VERSION "ChassisFusionCANFD"

NS_ :

BS_:

BU_: ADD BCP BCS EPS FZCU SCU SWM VECU XCD

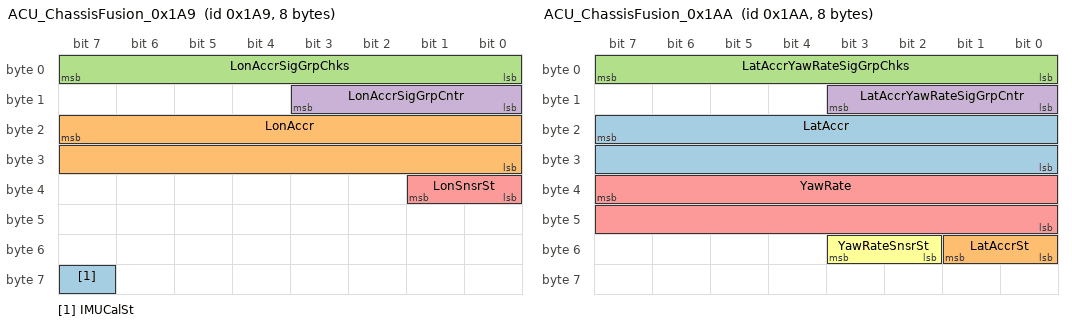
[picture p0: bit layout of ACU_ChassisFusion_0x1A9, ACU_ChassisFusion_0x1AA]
BO_ 425 ACU_ChassisFusion_0x1A9: 8 XCD
 SG_ IMUCalSt : 63|1@0+ (1,0) [0|1] ""  BCP,BCS,SCU
 SG_ LonAccr : 23|16@0+ (0.0002,-5) [-5|5] "g"  BCP,BCS,SCU
 SG_ LonAccrSigGrpChks : 7|8@0+ (1,0) [0|255] ""  BCP,BCS,SCU
 SG_ LonAccrSigGrpCntr : 11|4@0+ (1,0) [0|15] ""  BCP,BCS,SCU
 SG_ LonSnsrSt : 33|2@0+ (1,0) [0|3] ""  BCP,BCS,SCU

BO_ 426 ACU_ChassisFusion_0x1AA: 8 XCD
 SG_ LatAccr : 23|16@0+ (0.0002,-5) [-5|5] "g"  BCS,SCU
 SG_ LatAccrSt : 49|2@0+ (1,0) [0|3] ""  BCS,SCU
 SG_ LatAccrYawRateSigGrpChks : 7|8@0+ (1,0) [0|255] ""  BCS,SCU
 SG_ LatAccrYawRateSigGrpCntr : 11|4@0+ (1,0) [0|15] ""  BCS,SCU
 SG_ YawRate : 39|16@0+ (0.01,-300) [-300|300] "deg/s"  BCS,SCU
 SG_ YawRateSnsrSt : 51|2@0+ (1,0) [0|3] ""  BCS,SCU

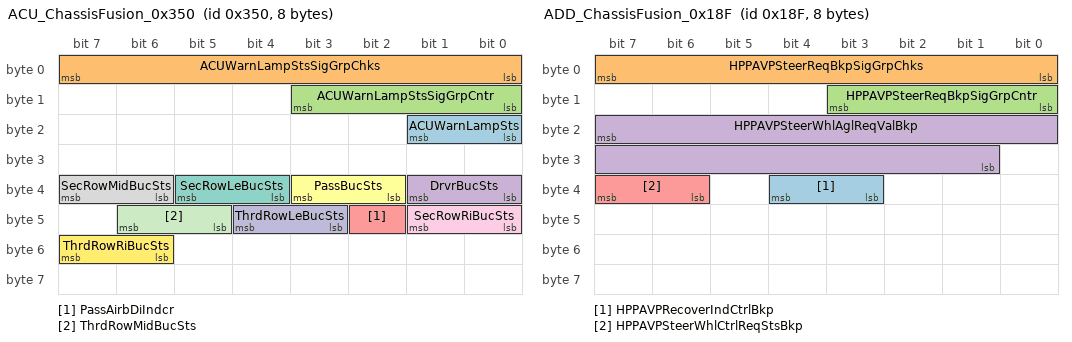
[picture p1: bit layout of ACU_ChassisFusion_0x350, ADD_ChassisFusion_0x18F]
BO_ 848 ACU_ChassisFusion_0x350: 8 XCD
 SG_ ACUWarnLampSts : 17|2@0+ (1,0) [0|3] "" Vector__XXX
 SG_ ACUWarnLampStsSigGrpChks : 7|8@0+ (1,0) [0|255] "" Vector__XXX
 SG_ ACUWarnLampStsSigGrpCntr : 11|4@0+ (1,0) [0|15] "" Vector__XXX
 SG_ DrvrBucSts : 33|2@0+ (1,0) [0|3] ""  SCU
 SG_ PassAirbDiIndcr : 42|1@0+ (1,0) [0|1] "" Vector__XXX
 SG_ PassBucSts : 35|2@0+ (1,0) [0|3] "" Vector__XXX
 SG_ SecRowLeBucSts : 37|2@0+ (1,0) [0|3] "" Vector__XXX
 SG_ SecRowMidBucSts : 39|2@0+ (1,0) [0|3] "" Vector__XXX
 SG_ SecRowRiBucSts : 41|2@0+ (1,0) [0|3] "" Vector__XXX
 SG_ ThrdRowLeBucSts : 44|2@0+ (1,0) [0|3] "" Vector__XXX
 SG_ ThrdRowMidBucSts : 46|2@0+ (1,0) [0|3] "" Vector__XXX
 SG_ ThrdRowRiBucSts : 55|2@0+ (1,0) [0|3] "" Vector__XXX

BO_ 379 ADD_ChassisFusion_0x17B: 16 ADD
 SG_ ADDKeepAwakeReq : 39|1@0+ (1,0) [0|1] ""  FZCU,XCD
 SG_ ParkGearReqEnaFrmADD : 20|2@0+ (1,0) [0|3] ""  FZCU,XCD
 SG_ ParkGearReqFrmADD : 18|3@0+ (1,0) [0|7] ""  FZCU,XCD
 SG_ ParkGearReqSigGrpChks : 7|8@0+ (1,0) [0|255] ""  FZCU,XCD
 SG_ ParkGearReqSigGrpCntr : 11|4@0+ (1,0) [0|15] ""  FZCU,XCD
 SG_ ParkGearReqSigGrpFV : 87|16@0+ (1,0) [0|65535] ""  FZCU,XCD
 SG_ ParkGearReqSigGrpMAC : 103|32@0+ (1,0) [0|0] ""  FZCU,XCD
 SG_ RPAHVOnReqFrmADD : 21|1@0+ (1,0) [0|1] ""  FZCU,XCD
 SG_ RPAPrkinRecdFrmADD : 23|2@0+ (1,0) [0|3] ""  FZCU,XCD

BO_ 399 ADD_ChassisFusion_0x18F: 8 ADD
 SG_ HPPAVPRecoverIndCtrlBkp : 36|2@0+ (1,0) [0|3] ""  EPS
 SG_ HPPAVPSteerReqBkpSigGrpChks : 7|8@0+ (1,0) [0|255] ""  EPS
 SG_ HPPAVPSteerReqBkpSigGrpCntr : 11|4@0+ (1,0) [0|15] ""  EPS
 SG_ HPPAVPSteerWhlAglReqValBkp : 23|15@0- (0.0625,0) [-780|780] "deg"  EPS
 SG_ HPPAVPSteerWhlCtrlReqStsBkp : 39|2@0+ (1,0) [0|3] ""  EPS

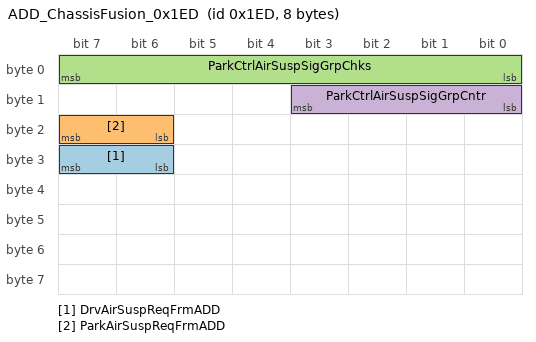
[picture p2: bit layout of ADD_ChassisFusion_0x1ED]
BO_ 493 ADD_ChassisFusion_0x1ED: 8 ADD
 SG_ DrvAirSuspReqFrmADD : 31|2@0+ (1,0) [0|3] ""  SCU
 SG_ ParkAirSuspReqFrmADD : 23|2@0+ (1,0) [0|3] ""  SCU
 SG_ ParkCtrlAirSuspSigGrpChks : 7|8@0+ (1,0) [0|255] ""  SCU
 SG_ ParkCtrlAirSuspSigGrpCntr : 11|4@0+ (1,0) [0|15] ""  SCU

BO_ 512 ADD_ChassisFusion_0x200: 48 ADD
 SG_ ADDBSDLCAStsFrmADD : 271|2@0+ (1,0) [0|3] ""  FZCU,XCD
 SG_ ADSAEBStsFrmADD : 279|3@0+ (1,0) [0|7] ""  FZCU,XCD
 SG_ ADSAEBTarDirFrmADD : 303|3@0+ (1,0) [0|4] ""  FZCU,XCD
 SG_ ADSAEBWarnReqFrmADD : 37|2@0+ (1,0) [0|3] ""  FZCU,VECU,XCD
 SG_ AdsAutoTurnLiCnclReqFrmADD : 89|2@0+ (1,0) [0|3] ""  FZCU,XCD
 SG_ AdsAutoTurnLiSwtStsFrmADD : 167|3@0+ (1,0) [0|7] ""  FZCU,XCD
 SG_ AdsAutoTurnLiUnavlRsnFrmADD : 164|4@0+ (1,0) [0|15] ""  XCD
 SG_ ADSBSDLCAAudioWarnReqFrmADD : 79|2@0+ (1,0) [0|2] ""  FZCU,VECU,XCD
 SG_ ADSBSDLCAWarnReqLeFrmADD : 35|2@0+ (1,0) [0|3] ""  FZCU,VECU,XCD
 SG_ ADSBSDLCAWarnReqRiFrmADD : 47|2@0+ (1,0) [0|3] ""  FZCU,VECU,XCD
 SG_ ADSBSDLightWarningLeReqFrmADD : 77|2@0+ (1,0) [0|2] ""  FZCU,VECU,XCD
 SG_ ADSBSDLightWarningRiReqFrmADD : 75|2@0+ (1,0) [0|2] ""  FZCU,VECU,XCD
 SG_ ADSDOWStsFrmADD : 269|2@0+ (1,0) [0|3] ""  FZCU,XCD
 SG_ ADSDOWWarnReqFrLeFrmADD : 45|2@0+ (1,0) [0|3] ""  FZCU,VECU,XCD
 SG_ ADSDOWWarnReqFrRiFrmADD : 15|2@0+ (1,0) [0|3] ""  FZCU,VECU,XCD
 SG_ ADSDOWWarnReqReLeFrmADD : 13|2@0+ (1,0) [0|3] ""  FZCU,VECU,XCD
 SG_ ADSDOWWarnReqReRiFrmADD : 43|2@0+ (1,0) [0|3] ""  FZCU,VECU,XCD
 SG_ ADSELKStsFrmADD : 276|3@0+ (1,0) [0|7] ""  FZCU,XCD
 SG_ ADSESSStsFrmADD : 287|3@0+ (1,0) [0|7] ""  FZCU,XCD
 SG_ ADSESSWarnReqFrmADD : 41|1@0+ (1,0) [0|1] ""  FZCU,VECU,XCD
 SG_ ADSFctStsSigGrpChks : 263|8@0+ (1,0) [0|255] ""  FZCU,XCD
 SG_ ADSFctStsSigGrpCntr : 267|4@0+ (1,0) [0|15] ""  FZCU,XCD
 SG_ ADSFCWReqFrmADD : 23|2@0+ (1,0) [0|3] ""  FZCU,VECU,XCD
 SG_ ADSFCWStsFrmADD : 284|3@0+ (1,0) [0|7] ""  FZCU,XCD
 SG_ ADSGearReqSigGrpChks : 175|8@0+ (1,0) [0|255] ""  FZCU,XCD
 SG_ ADSGearReqSigGrpCntr : 179|4@0+ (1,0) [0|15] ""  FZCU,XCD
 SG_ AdsIntelgntSpdSwtStsFrmADD : 159|3@0+ (1,0) [0|7] ""  XCD
 SG_ AdsIntelgntSpdUnavlRsnFrmADD : 156|3@0+ (1,0) [0|7] ""  XCD
 SG_ ADSLDPHandOffExitFrmADD : 56|1@0+ (1,0) [0|1] ""  FZCU,VECU,XCD
 SG_ ADSLDPHandOffWarningFrmADD : 65|2@0+ (1,0) [0|3] ""  FZCU,VECU,XCD
 SG_ ADSLDPStsFrmADD : 295|3@0+ (1,0) [0|7] ""  FZCU,XCD
 SG_ ADSLDPWarnReqLeFrmADD : 21|1@0+ (1,0) [0|1] ""  FZCU,VECU,XCD
 SG_ ADSLDPWarnReqRiFrmADD : 20|1@0+ (1,0) [0|1] ""  FZCU,VECU,XCD
 SG_ ADSLDWStsFrmADD : 292|3@0+ (1,0) [0|7] ""  FZCU,XCD
 SG_ ADSLDWWarnLeReqFrmADD : 19|1@0+ (1,0) [0|1] ""  FZCU,VECU,XCD
 SG_ ADSLDWWarnRiReqFrmADD : 18|1@0+ (1,0) [0|1] ""  FZCU,VECU,XCD
 SG_ AdsLearnSwtStsFrmADD : 370|3@0+ (1,0) [0|7] ""  XCD
 SG_ AdsLearnSwtUnavlRsnFrmADD : 363|4@0+ (1,0) [0|15] ""  XCD
 SG_ ADSLiReqFrmADD : 142|2@0+ (1,0) [0|3] ""  FZCU,XCD
 SG_ ADSMAIInhibitReqFrmADD : 207|2@0+ (1,0) [0|3] ""  XCD
 SG_ ADSMAIStsFrmADD : 205|3@0+ (1,0) [0|7] ""  XCD
 SG_ ADSMAIWarnReqFrmADD : 202|2@0+ (1,0) [0|3] ""  XCD
 SG_ AdsModSwtStsFrmADD : 367|4@0+ (1,0) [0|15] ""  XCD
 SG_ AdsNOAOddSwtStsFrmADD : 355|4@0+ (1,0) [0|15] ""  XCD
 SG_ AdsNOAOddSwtUnavlRsnFrmADD : 373|3@0+ (1,0) [0|7] ""  XCD
 SG_ ADSRCTAStsFrmADD : 273|2@0+ (1,0) [0|3] ""  FZCU,XCD
 SG_ ADSRCTAWarnReqLeFrmADD : 17|2@0+ (1,0) [0|3] ""  FZCU,VECU,XCD
 SG_ ADSRCTAWarnReqRiFrmADD : 31|2@0+ (1,0) [0|3] ""  FZCU,VECU,XCD
 SG_ ADSRCTBStsFrmADD : 281|2@0+ (1,0) [0|3] ""  FZCU,XCD
 SG_ ADSRCTBWarnReqLeFrmADD : 29|2@0+ (1,0) [0|3] ""  FZCU,VECU,XCD
 SG_ ADSRCTBWarnReqRiFrmADD : 27|2@0+ (1,0) [0|3] ""  FZCU,VECU,XCD
 SG_ ADSRCWStsFrmADD : 289|2@0+ (1,0) [0|3] ""  FZCU,XCD
 SG_ ADSRCWWarnReqFrmADD : 25|2@0+ (1,0) [0|3] ""  FZCU,VECU,XCD
 SG_ ADSSysErrorRmdFrmADD : 95|2@0+ (1,0) [0|3] ""  XCD
 SG_ ADSSysErrorStsFrmADD : 93|2@0+ (1,0) [0|3] ""  XCD
 SG_ ADSTakeoverRmdFrmADD : 91|2@0+ (1,0) [0|3] ""  XCD
 SG_ ADSTLAStsFrmADD : 335|3@0+ (1,0) [0|7] ""  XCD
 SG_ AdsTrfcLiCtrlSwtStsFrmADD : 375|2@0+ (1,0) [0|3] ""  XCD
 SG_ ADSVcCtrlArbFrmADD : 39|2@0+ (1,0) [0|3] ""  FZCU,VECU,XCD
 SG_ AdsVehDetourSwtStsFrmADD : 357|2@0+ (1,0) [0|3] ""  XCD
 SG_ ADSWarnSigGrpChks : 7|8@0+ (1,0) [0|255] ""  FZCU,VECU,XCD
 SG_ ADSWarnSigGrpCntr : 11|4@0+ (1,0) [0|15] ""  FZCU,VECU,XCD
 SG_ ADSwtStsSigGrp2Chks : 343|8@0+ (1,0) [0|255] ""  XCD
 SG_ ADSwtStsSigGrp2Cntr : 347|4@0+ (1,0) [0|15] ""  XCD
 SG_ AEBTarObjClassFrmADD : 223|2@0+ (1,0) [0|3] ""  FZCU,XCD
 SG_ AEBTarObjTTIFrmADD : 231|8@0+ (0.02,0) [0|5.1] ""  FZCU,XCD
 SG_ AEBtoIDPFrmADDChks : 215|8@0+ (1,0) [0|255] ""  FZCU,XCD
 SG_ AEBtoIDPFrmADDCntr : 219|4@0+ (1,0) [0|15] ""  FZCU,XCD
 SG_ AutoDrvLaneChgStsFrmADD : 103|4@0+ (1,0) [0|15] ""  FZCU,XCD
 SG_ AVMCamVideoChainSts : 245|2@0+ (1,0) [0|3] ""  XCD
 SG_ AVMCamVideoChainStsChks : 239|8@0+ (1,0) [0|255] ""  XCD
 SG_ AVMCamVideoChainStsCntr : 243|4@0+ (1,0) [0|15] ""  XCD
 SG_ DrvAtmLiReqFrmADD : 40|1@0+ (1,0) [0|1] ""  FZCU,VECU,XCD
 SG_ DrvGearReqFrmADD : 191|3@0+ (1,0) [0|7] ""  FZCU,XCD
 SG_ DrvGearReqVldFrmADD : 188|1@0+ (1,0) [0|1] ""  FZCU,XCD
 SG_ DrvHUDDspFrmADD : 99|4@0+ (1,0) [0|15] ""  FZCU,XCD
 SG_ DrvLaneChgStsFrmADD : 111|4@0+ (1,0) [0|15] ""  FZCU,XCD
 SG_ DrvMdlStsFrmADD : 317|3@0+ (1,0) [0|7] ""  FZCU,XCD
 SG_ DrvNOAExtLgtDstFrmADD : 119|9@0+ (1,0) [0|511] "m"  FZCU,XCD
 SG_ DrvNOAQutLgtDstFrmADD : 135|9@0+ (1,0) [0|511] "m"  FZCU,XCD
 SG_ DrvNOARemdFrmADD : 327|6@0+ (1,0) [0|63] ""  XCD
 SG_ DrvPltSysStsFrmADD : 126|4@0+ (1,0) [0|15] ""  FZCU,XCD
 SG_ DrvPnt2PntExtLgtDstFrmADD : 311|9@0+ (1,0) [0|511] "m"  XCD
 SG_ DrvPnt2PntSysStsFrmADD : 332|5@0+ (1,0) [0|31] ""  XCD
 SG_ DrvrSeldDstLvlFrmADD : 122|3@0+ (1,0) [0|7] ""  FZCU,XCD
 SG_ DrvSysWarnFrmADD : 55|3@0+ (1,0) [0|7] ""  FZCU,VECU,XCD
 SG_ DrvTurnLiReqFrmADD : 140|2@0+ (1,0) [0|3] ""  FZCU,XCD
 SG_ IndcrCancelReqFrmADD : 138|2@0+ (1,0) [0|3] ""  FZCU,XCD
 SG_ LidarCleanReqFrmADD : 321|2@0+ (1,0) [0|3] ""  FZCU,XCD
 SG_ NOASysStsFrmADD : 107|4@0+ (1,0) [0|15] ""  FZCU,XCD
 SG_ NOATypFrmADD : 153|2@0+ (1,0) [0|3] "-"  XCD
 SG_ TSASignQlyFrmADD : 63|7@0+ (1,0) [0|126] ""  FZCU,VECU,XCD
 SG_ TSASignTypeFrmADD : 71|6@0+ (1,0) [0|63] ""  FZCU,VECU,XCD
 SG_ TSASpdLimitFrmADD : 52|5@0+ (1,0) [0|31] ""  FZCU,VECU,XCD
 SG_ TSASpdLimitUnitFrmADD : 33|2@0+ (1,0) [0|3] ""  FZCU,VECU,XCD
 SG_ UserFbReqFrmADD : 151|2@0+ (1,0) [0|3] ""  FZCU,XCD

BO_ 513 ADD_ChassisFusion_0x201: 48 ADD
 SG_ ADSAPPUnableOpenRsnFrmADD : 162|3@0+ (1,0) [0|7] ""  XCD
 SG_ ADSAVPStsFrmADD : 127|4@0+ (1,0) [0|15] ""  XCD
 SG_ ADSHPPStsFrmADD : 95|4@0+ (1,0) [0|15] ""  XCD
 SG_ ADSLRRSnsrStsFrmADD : 351|4@0+ (1,0) [0|15] ""  XCD
 SG_ ADSRLSRSnsrStsFrmADD : 71|4@0+ (1,0) [0|15] ""  XCD
 SG_ ADSRRSRSnsrStsFrmADD : 67|4@0+ (1,0) [0|15] ""  XCD
 SG_ AFrCamStsFrmADD : 245|3@0+ (1,0) [0|7] ""  XCD
 SG_ ALeCamStsFrmADD : 250|3@0+ (1,0) [0|7] ""  XCD
 SG_ APAIcnDispStsFrmADD : 335|3@0+ (1,0) [0|7] ""  XCD
 SG_ APAVcFbFrmADD : 231|7@0+ (1,0) [0|127] ""  XCD
 SG_ APAVcQuitAvlFrmADD : 220|1@0+ (1,0) [0|1] ""  XCD
 SG_ APAVcStsFrmADD : 219|1@0+ (1,0) [0|1] ""  XCD
 SG_ AReCamStsFrmADD : 253|3@0+ (1,0) [0|7] ""  XCD
 SG_ ARiCamStsFrmADD : 7|3@0+ (1,0) [0|7] ""  XCD
 SG_ AVMOpnReqFrmADD : 223|3@0+ (1,0) [0|7] ""  XCD
 SG_ AVPHPPStatusSigGrpChks : 87|8@0+ (1,0) [0|255] ""  XCD
 SG_ AVPHPPStatusSigGrpCntr : 91|4@0+ (1,0) [0|15] ""  XCD
 SG_ AVPIcnDispStsFrmADD : 332|3@0+ (1,0) [0|7] ""  XCD
 SG_ CameraStsforADBFrmADD : 279|2@0+ (1,0) [0|3] ""  FZCU,XCD
 SG_ CameraStsFrmADD : 277|2@0+ (1,0) [0|3] ""  FZCU,XCD
 SG_ F120CamStsFrmADD : 35|3@0+ (1,0) [0|7] ""  XCD
 SG_ F120DVRStsFrmADD : 15|3@0+ (1,0) [0|7] ""  XCD
 SG_ F30CamStsFrmADD : 4|3@0+ (1,0) [0|7] ""  XCD
 SG_ F30DVRStsFrmADD : 12|3@0+ (1,0) [0|7] ""  XCD
 SG_ FLidarStsFrmADD : 47|4@0+ (1,0) [0|15] ""  XCD
 SG_ FUSSStsFrmADD : 43|4@0+ (1,0) [0|15] ""  XCD
 SG_ HPPActiveSubStsFrmADD : 114|3@0+ (1,0) [0|7] ""  XCD
 SG_ HPPAlrtWarnFrmADD : 151|3@0+ (1,0) [0|7] ""  XCD
 SG_ HPPAVPModSts : 76|3@0+ (1,0) [0|7] ""  XCD
 SG_ HPPBakMapDfltParkSlotDispFrmADD : 311|1@0+ (1,0) [0|1] ""  XCD
 SG_ HPPDriverOperateDialogFrmADD : 111|4@0+ (1,0) [0|15] ""  XCD
 SG_ HPPDriverOperateInd2FrmADD : 119|5@0+ (1,0) [0|31] ""  XCD
 SG_ HPPDriverOperateIndFrmADD : 143|5@0+ (1,0) [0|31] ""  XCD
 SG_ HPPIcnDispStsFrmADD : 343|3@0+ (1,0) [0|7] ""  XCD
 SG_ HPPInfotipFrmADD : 103|6@0+ (1,0) [0|63] ""  XCD
 SG_ HPPLearnSubStsFrmADD : 123|4@0+ (1,0) [0|15] ""  XCD
 SG_ HPPLrnVcFbFrmADD : 218|1@0+ (1,0) [0|1] ""  XCD
 SG_ HPPPlayBackPushFrmADD : 310|1@0+ (1,0) [0|1] ""  XCD
 SG_ HPPQuitIndFrmADD : 159|7@0+ (1,0) [0|127] ""  XCD
 SG_ HPPRecoverButtonStsFrmADD : 307|2@0+ (1,0) [0|3] ""  XCD
 SG_ HPPRecoverIndFrmADD : 167|5@0+ (1,0) [0|31] ""  XCD
 SG_ HPPRouteInd2FrmADD : 107|4@0+ (1,0) [0|15] ""  XCD
 SG_ HPPRouteIndFrmADD : 148|5@0+ (1,0) [0|31] ""  XCD
 SG_ HPPRouteManageStsFrmADD : 309|1@0+ (1,0) [0|1] ""  XCD
 SG_ HPPToSRSigGrpChks : 295|8@0+ (1,0) [0|255] ""  XCD
 SG_ HPPToSRSigGrpCntr : 299|4@0+ (1,0) [0|15] ""  XCD
 SG_ HPPUnableToActiveIndFrmADD : 135|7@0+ (1,0) [0|127] ""  XCD
 SG_ HPPVehInParkSlotFrmADD : 308|1@0+ (1,0) [0|1] ""  XCD
 SG_ IMUStsFrmADD : 55|4@0+ (1,0) [0|15] ""  XCD
 SG_ ISPLigtSnsrVFrmADD : 263|16@0+ (1,0) [0|65535] "Lux"  FZCU,XCD
 SG_ LidarStsFrmADD : 275|2@0+ (1,0) [0|3] ""  FZCU,XCD
 SG_ ParkIcnStsSigGrpChks : 319|8@0+ (1,0) [0|255] ""  XCD
 SG_ ParkIcnStsSigGrpCntr : 323|4@0+ (1,0) [0|15] ""  XCD
 SG_ ParkVCstatusSigGrpChks : 207|8@0+ (1,0) [0|255] ""  XCD
 SG_ ParkVCstatusSigGrpCntr : 211|4@0+ (1,0) [0|15] ""  XCD
 SG_ ParkVicShdFrmADD : 215|3@0+ (1,0) [0|7] ""  XCD
 SG_ PrkSteerWhlBtnLi : 329|2@0+ (1,0) [0|3] ""  XCD
 SG_ ReCamStsFrmADD : 287|3@0+ (1,0) [0|7] ""  XCD
 SG_ ReDVRStsFrmADD : 39|3@0+ (1,0) [0|7] ""  XCD
 SG_ RUSSStsFrmADD : 51|4@0+ (1,0) [0|15] ""  XCD
 SG_ SLFCamStsFrmADD : 234|3@0+ (1,0) [0|7] ""  XCD
 SG_ SLFDVRStsFrmADD : 23|3@0+ (1,0) [0|7] ""  XCD
 SG_ SLLidarStsFrmADD : 63|4@0+ (1,0) [0|15] ""  XCD
 SG_ SLRCamStsFrmADD : 237|3@0+ (1,0) [0|7] ""  XCD
 SG_ SLRDVRStsFrmADD : 20|3@0+ (1,0) [0|7] ""  XCD
 SG_ SnmDetInfoFrmADD : 175|16@0+ (1,0) [0|65535] ""  XCD
 SG_ SnmDetResFrmADD : 185|2@0+ (1,0) [0|3] ""  XCD
 SG_ SnmF120CamDetResFrmADD : 187|2@0+ (1,0) [0|3] ""  XCD
 SG_ SnmReCamDetResFrmADD : 189|2@0+ (1,0) [0|3] ""  XCD
 SG_ SnmSLFCamDetResFrmADD : 191|2@0+ (1,0) [0|3] ""  XCD
 SG_ SnmSLRCamDetResFrmADD : 193|2@0+ (1,0) [0|3] ""  XCD
 SG_ SnmSRFCamDetResFrmADD : 195|2@0+ (1,0) [0|3] ""  XCD
 SG_ SnmSRRCamDetResFrmADD : 197|2@0+ (1,0) [0|3] ""  XCD
 SG_ SRFCamStsFrmADD : 242|3@0+ (1,0) [0|7] ""  XCD
 SG_ SRFDVRStsFrmADD : 31|3@0+ (1,0) [0|7] ""  XCD
 SG_ SRLidarStsFrmADD : 59|4@0+ (1,0) [0|15] ""  XCD
 SG_ SRRCamStsFrmADD : 79|3@0+ (1,0) [0|7] ""  XCD
 SG_ SRRDVRStsFrmADD : 28|3@0+ (1,0) [0|7] ""  XCD

BO_ 516 ADD_ChassisFusion_0x204: 32 ADD
 SG_ APAAlrtWarnFrmADD : 121|2@0+ (1,0) [0|3] ""  FZCU,XCD
 SG_ APAButtonReqFrmADD : 199|2@0+ (1,0) [0|3] ""  XCD
 SG_ APARPAActiveSubFunFrmADD : 114|3@0+ (1,0) [0|7] ""  FZCU,XCD
 SG_ APARPADriverOperateInd2FrmADD : 159|6@0+ (1,0) [0|63] ""  FZCU,XCD
 SG_ APARPADriverOperateIndFrmADD : 127|6@0+ (1,0) [0|63] ""  FZCU,XCD
 SG_ APARPAQuitReasonIndFrmADD : 135|6@0+ (1,0) [0|63] ""  FZCU,XCD
 SG_ APARPARecoverIndFrmADD : 143|5@0+ (1,0) [0|31] ""  FZCU,XCD
 SG_ APARPAstatusFrmADD : 118|4@0+ (1,0) [0|15] ""  FZCU,XCD
 SG_ APARPAstatusSigGrpChks : 87|8@0+ (1,0) [0|255] ""  FZCU,XCD
 SG_ APARPAstatusSigGrpCntr : 91|4@0+ (1,0) [0|15] ""  FZCU,XCD
 SG_ APARPAUnableToActiveIndFrmADD : 151|6@0+ (1,0) [0|63] ""  FZCU,XCD
 SG_ AVPCharLidCtrlFrmADD : 15|2@0+ (1,0) [0|3] ""  FZCU,XCD
 SG_ DriverlessStsFrmADD : 185|2@0+ (1,0) [0|3] ""  XCD
 SG_ OutdoorPrkDrvrOperIndFrmADD : 197|6@0+ (1,0) [0|63] ""  XCD
 SG_ OutdoorPrkQuitIndFrmADD : 191|6@0+ (1,0) [0|63] ""  XCD
 SG_ OutdoorPrkRecoverIndFrmADD : 183|5@0+ (1,0) [0|31] ""  XCD
 SG_ OutdoorPrkUnableToActvIndFrmADD : 175|6@0+ (1,0) [0|63] ""  XCD
 SG_ ParkActiveRearSpoilerReqFrmADD : 202|3@0+ (1,0) [0|7] ""  XCD
 SG_ ParkAtmLiReqFrmADD : 13|2@0+ (1,0) [0|3] ""  FZCU,XCD
 SG_ ParkBackMirrorUnfoldReqFrmADD : 23|2@0+ (1,0) [0|3] ""  FZCU,XCD
 SG_ ParkCornrLiReqFrmADD : 207|2@0+ (1,0) [0|3] ""  FZCU,XCD
 SG_ ParkDoorLockReqFrmADD : 21|2@0+ (1,0) [0|3] ""  FZCU,XCD
 SG_ ParkingPushFrmADD : 71|3@0+ (1,0) [0|7] ""  XCD
 SG_ ParkLightReqSigGrpChks : 7|8@0+ (1,0) [0|255] ""  FZCU,XCD
 SG_ ParkLightReqSigGrpCntr : 11|4@0+ (1,0) [0|15] ""  FZCU,XCD
 SG_ ParkLoBeamReqFrmADD : 19|1@0+ (1,0) [0|1] ""  FZCU,XCD
 SG_ ParkMdlStsFrmADD : 63|3@0+ (1,0) [0|7] ""  FZCU,XCD
 SG_ ParkProgressSigReDistFrmADD : 111|9@0+ (1,0) [0|511] "dm"  FZCU,XCD
 SG_ ParkTurnLiReqFrmADD : 18|2@0+ (1,0) [0|3] ""  FZCU,XCD
 SG_ ParkWindowReqFrmADD : 16|1@0+ (1,0) [0|1] ""  FZCU,XCD
 SG_ PASBuzzerWarnMuteIndFrmADD : 57|1@0+ (1,0) [0|1] ""  XCD
 SG_ PRAMoveSigReDistFrmADD : 103|8@0+ (1,0) [0|255] "dm"  FZCU,XCD
 SG_ PrkgHornReqFrmADD : 31|1@0+ (1,0) [0|1] ""  FZCU,XCD
 SG_ RPAAvailableFrmADD : 30|1@0+ (1,0) [0|1] ""  FZCU,XCD
 SG_ RPAAvailableFrmADDFV : 215|16@0+ (1,0) [0|65535] ""  XCD
 SG_ RPAAvailableFrmADDMAC : 231|32@0+ (1,0) [0|0] ""  XCD
 SG_ RPADriverOperateIndFrmADD : 79|4@0+ (1,0) [0|15] ""  XCD
 SG_ RPAOperateToastFrmADD : 75|4@0+ (1,0) [0|15] ""  XCD
 SG_ RPAQuitReasonIndFrmADD : 55|7@0+ (1,0) [0|127] ""  XCD
 SG_ RPARecoverIndFrmADD : 68|5@0+ (1,0) [0|31] ""  XCD
 SG_ RPAUnableToActiveIndFrmADD : 47|4@0+ (1,0) [0|15] ""  XCD
 SG_ WeatherStsFrmADD : 60|3@0+ (1,0) [0|7] ""  FZCU,SCU,XCD

BO_ 518 ADD_ChassisFusion_0x206: 64 ADD
 SG_ BndryLeftAng1FrmADD : 263|13@0- (0.01,0) [-40.96|40.95] ""  FZCU
 SG_ BndryLeftAng2FrmADD : 287|13@0- (0.01,0) [-40.96|40.95] ""  FZCU
 SG_ BndryLeftAng3FrmADD : 311|13@0- (0.01,0) [-40.96|40.95] ""  FZCU
 SG_ BndryLeftAng4FrmADD : 335|13@0- (0.01,0) [-40.96|40.95] ""  FZCU
 SG_ BndryLeftAng5FrmADD : 359|13@0- (0.01,0) [-40.96|40.95] ""  FZCU
 SG_ BndryLeftDist1FrmADD : 265|10@0+ (1,0) [0|1023] ""  FZCU
 SG_ BndryLeftDist2FrmADD : 289|10@0+ (1,0) [0|1023] ""  FZCU
 SG_ BndryLeftDist3FrmADD : 313|10@0+ (1,0) [0|1023] ""  FZCU
 SG_ BndryLeftDist4FrmADD : 337|10@0+ (1,0) [0|1023] ""  FZCU
 SG_ BndryLeftDist5FrmADD : 361|10@0+ (1,0) [0|1023] ""  FZCU
 SG_ BndryLowerAng1FrmADD : 383|13@0- (0.01,0) [-40.96|40.95] ""  FZCU
 SG_ BndryLowerAng2FrmADD : 407|13@0- (0.01,0) [-40.96|40.95] ""  FZCU
 SG_ BndryLowerAng3FrmADD : 431|13@0- (0.01,0) [-40.96|40.95] ""  FZCU
 SG_ BndryLowerAng4FrmADD : 455|13@0- (0.01,0) [-40.96|40.95] ""  FZCU
 SG_ BndryLowerAng5FrmADD : 479|13@0- (0.01,0) [-40.96|40.95] ""  FZCU
 SG_ BndryLowerDist1FrmADD : 385|10@0+ (1,0) [0|1023] ""  FZCU
 SG_ BndryLowerDist2FrmADD : 409|10@0+ (1,0) [0|1023] ""  FZCU
 SG_ BndryLowerDist3FrmADD : 433|10@0+ (1,0) [0|1023] ""  FZCU
 SG_ BndryLowerDist4FrmADD : 457|10@0+ (1,0) [0|1023] ""  FZCU
 SG_ BndryLowerDist5FrmADD : 481|10@0+ (1,0) [0|1023] ""  FZCU
 SG_ VehObjDist1FrmADD : 7|10@0+ (1,0) [0|1023] "m"  FZCU,XCD
 SG_ VehObjDist2FrmADD : 9|10@0+ (1,0) [0|1023] "m"  FZCU,XCD
 SG_ VehObjDist3FrmADD : 31|10@0+ (1,0) [0|1023] "m"  FZCU,XCD
 SG_ VehObjDist4FrmADD : 33|10@0+ (1,0) [0|1023] "m"  FZCU,XCD
 SG_ VehObjDist5FrmADD : 55|10@0+ (1,0) [0|1023] "m"  FZCU,XCD
 SG_ VehObjDist6FrmADD : 57|10@0+ (1,0) [0|1023] "m"  FZCU,XCD
 SG_ VehObjDist7FrmADD : 79|10@0+ (1,0) [0|1023] "m"  FZCU,XCD
 SG_ VehObjDist8FrmADD : 81|10@0+ (1,0) [0|1023] "m"  FZCU,XCD
 SG_ VehObjHorzCtrAng1FrmADD : 103|11@0- (0.05,0) [-51.2|51.15] "Deg"  FZCU,XCD
 SG_ VehObjHorzCtrAng2FrmADD : 106|11@0- (0.05,0) [-51.2|51.15] "Deg"  FZCU,XCD
 SG_ VehObjHorzCtrAng3FrmADD : 127|11@0- (0.05,0) [-51.2|51.15] "Deg"  FZCU,XCD
 SG_ VehObjHorzCtrAng4FrmADD : 130|11@0- (0.05,0) [-51.2|51.15] "Deg"  FZCU,XCD
 SG_ VehObjHorzCtrAng5FrmADD : 151|11@0- (0.05,0) [-51.2|51.15] "Deg"  FZCU,XCD
 SG_ VehObjHorzCtrAng6FrmADD : 154|11@0- (0.05,0) [-51.2|51.15] "Deg"  FZCU,XCD
 SG_ VehObjHorzCtrAng7FrmADD : 175|11@0- (0.05,0) [-51.2|51.15] "Deg"  FZCU,XCD
 SG_ VehObjHorzCtrAng8FrmADD : 178|11@0- (0.05,0) [-51.2|51.15] "Deg"  FZCU,XCD
 SG_ VehObjHorzWidthAng1FrmADD : 199|7@0+ (0.1,0) [0|12.7] "m"  FZCU,XCD
 SG_ VehObjHorzWidthAng2FrmADD : 207|7@0+ (0.1,0) [0|12.7] "m"  FZCU,XCD
 SG_ VehObjHorzWidthAng3FrmADD : 215|7@0+ (0.1,0) [0|12.7] "m"  FZCU,XCD
 SG_ VehObjHorzWidthAng4FrmADD : 223|7@0+ (0.1,0) [0|12.7] "m"  FZCU,XCD
 SG_ VehObjHorzWidthAng5FrmADD : 231|7@0+ (0.1,0) [0|12.7] "m"  FZCU,XCD
 SG_ VehObjHorzWidthAng6FrmADD : 247|7@0+ (0.1,0) [0|12.7] "m"  FZCU,XCD
 SG_ VehObjHorzWidthAng7FrmADD : 239|7@0+ (0.1,0) [0|12.7] "m"  FZCU,XCD
 SG_ VehObjHorzWidthAng8FrmADD : 255|7@0+ (0.1,0) [0|12.7] "m"  FZCU,XCD

BO_ 519 ADD_ChassisFusion_0x207: 64 ADD
 SG_ BndryRightAng1FrmADD : 7|13@0- (0.01,0) [-40.96|40.95] ""  FZCU
 SG_ BndryRightAng2FrmADD : 31|13@0- (0.01,0) [-40.96|40.95] ""  FZCU
 SG_ BndryRightAng3FrmADD : 55|13@0- (0.01,0) [-40.96|40.95] ""  FZCU
 SG_ BndryRightAng4FrmADD : 79|13@0- (0.01,0) [-40.96|40.95] ""  FZCU
 SG_ BndryRightAng5FrmADD : 103|13@0- (0.01,0) [-40.96|40.95] ""  FZCU
 SG_ BndryRightDist1FrmADD : 9|10@0+ (1,0) [0|1023] ""  FZCU
 SG_ BndryRightDist2FrmADD : 33|10@0+ (1,0) [0|1023] ""  FZCU
 SG_ BndryRightDist3FrmADD : 57|10@0+ (1,0) [0|1023] ""  FZCU
 SG_ BndryRightDist4FrmADD : 81|10@0+ (1,0) [0|1023] ""  FZCU
 SG_ BndryRightDist5FrmADD : 105|10@0+ (1,0) [0|1023] ""  FZCU
 SG_ BndryValidity1FrmADD : 10|1@0+ (1,0) [0|1] ""  FZCU
 SG_ BndryValidity2FrmADD : 34|1@0+ (1,0) [0|1] ""  FZCU
 SG_ BndryValidity3FrmADD : 58|1@0+ (1,0) [0|1] ""  FZCU
 SG_ BndryValidity4FrmADD : 82|1@0+ (1,0) [0|1] ""  FZCU
 SG_ BndryValidity5FrmADD : 106|1@0+ (1,0) [0|1] ""  FZCU
 SG_ EnvIllumFrmADD : 258|2@0+ (1,0) [0|3] ""  FZCU,XCD
 SG_ RoadCondDistFrmADD : 376|9@0+ (1,0) [0|500] ""  FZCU,SCU
 SG_ RoadConditionFrmADD : 399|8@0+ (1,0) [0|100] ""  FZCU,SCU
 SG_ RoadCondLenthFrmADD : 415|9@0+ (1,0) [0|500] ""  FZCU,SCU
 SG_ TooManyBndryFlagFrmADD : 133|1@0+ (1,0) [0|1] ""  FZCU
 SG_ TooManyVehFlagFrmADD : 132|1@0+ (1,0) [0|1] ""  FZCU
 SG_ TrafSignDist1FrmADD : 127|10@0+ (1,0) [0|1023] "m"  FZCU
 SG_ TrafSignDist2FrmADD : 143|10@0+ (1,0) [0|1023] "m"  FZCU
 SG_ TrafSignHorzCtrAng1FrmADD : 159|11@0- (0.05,0) [-51.2|51.15] "Deg"  FZCU
 SG_ TrafSignHorzCtrAng2FrmADD : 255|11@0- (0.05,0) [-51.2|51.15] "Deg"  FZCU
 SG_ TrafSignHorzWidthAng1FrmADD : 350|7@0+ (0.1,0) [0|12.7] "Deg"  FZCU
 SG_ TrafSignHorzWidthAng2FrmADD : 383|7@0+ (0.1,0) [0|12.7] "Deg"  FZCU
 SG_ TrafSignID1FrmADD : 359|10@0+ (1,0) [0|1023] ""  FZCU
 SG_ TrafSignID2FrmADD : 361|10@0+ (1,0) [0|1023] ""  FZCU
 SG_ TrafSignValidity1FrmADD : 131|1@0+ (1,0) [0|1] ""  FZCU,XCD
 SG_ TrafSignValidity2FrmADD : 130|1@0+ (1,0) [0|1] ""  FZCU
 SG_ VehObjDir1FrmADD : 129|1@0+ (1,0) [0|1] ""  FZCU,XCD
 SG_ VehObjDir2FrmADD : 128|1@0+ (1,0) [0|1] ""  FZCU,XCD
 SG_ VehObjDir3FrmADD : 149|1@0+ (1,0) [0|1] ""  FZCU,XCD
 SG_ VehObjDir4FrmADD : 148|1@0+ (1,0) [0|1] ""  FZCU,XCD
 SG_ VehObjDir5FrmADD : 147|1@0+ (1,0) [0|1] ""  FZCU,XCD
 SG_ VehObjDir6FrmADD : 146|1@0+ (1,0) [0|1] ""  FZCU,XCD
 SG_ VehObjDir7FrmADD : 145|1@0+ (1,0) [0|1] ""  FZCU,XCD
 SG_ VehObjDir8FrmADD : 144|1@0+ (1,0) [0|1] ""  FZCU,XCD
 SG_ VehObjID1FrmADD : 175|16@0+ (1,0) [0|65535] ""  FZCU,XCD
 SG_ VehObjID2FrmADD : 191|16@0+ (1,0) [0|65535] ""  FZCU,XCD
 SG_ VehObjID3FrmADD : 207|16@0+ (1,0) [0|65535] ""  FZCU,XCD
 SG_ VehObjID4FrmADD : 223|16@0+ (1,0) [0|65535] ""  FZCU,XCD
 SG_ VehObjID5FrmADD : 239|16@0+ (1,0) [0|65535] ""  FZCU,XCD
 SG_ VehObjID6FrmADD : 271|16@0+ (1,0) [0|65535] ""  FZCU,XCD
 SG_ VehObjID7FrmADD : 287|16@0+ (1,0) [0|65535] ""  FZCU,XCD
 SG_ VehObjID8FrmADD : 303|16@0+ (1,0) [0|65535] ""  FZCU,XCD
 SG_ VehObjType1FrmADD : 319|4@0+ (1,0) [0|15] ""  FZCU,XCD
 SG_ VehObjType2FrmADD : 315|4@0+ (1,0) [0|15] ""  FZCU,XCD
 SG_ VehObjType3FrmADD : 327|4@0+ (1,0) [0|15] ""  FZCU,XCD
 SG_ VehObjType4FrmADD : 323|4@0+ (1,0) [0|15] ""  FZCU,XCD
 SG_ VehObjType5FrmADD : 335|4@0+ (1,0) [0|15] ""  FZCU,XCD
 SG_ VehObjType6FrmADD : 331|4@0+ (1,0) [0|15] ""  FZCU,XCD
 SG_ VehObjType7FrmADD : 343|4@0+ (1,0) [0|15] ""  FZCU,XCD
 SG_ VehObjType8FrmADD : 339|4@0+ (1,0) [0|15] ""  FZCU,XCD
 SG_ VehObjValidity1FrmADD : 164|1@0+ (1,0) [0|1] ""  FZCU,XCD
 SG_ VehObjValidity2FrmADD : 163|1@0+ (1,0) [0|1] ""  FZCU,XCD
 SG_ VehObjValidity3FrmADD : 162|1@0+ (1,0) [0|1] ""  FZCU,XCD
 SG_ VehObjValidity4FrmADD : 161|1@0+ (1,0) [0|1] ""  FZCU,XCD
 SG_ VehObjValidity5FrmADD : 160|1@0+ (1,0) [0|1] ""  FZCU,XCD
 SG_ VehObjValidity6FrmADD : 260|1@0+ (1,0) [0|1] ""  FZCU,XCD
 SG_ VehObjValidity7FrmADD : 259|1@0+ (1,0) [0|1] ""  FZCU,XCD
 SG_ VehObjValidity8FrmADD : 351|1@0+ (1,0) [0|1] ""  FZCU,XCD

BO_ 528 ADD_ChassisFusion_0x210: 8 ADD
 SG_ ADDSyncFVReq : 7|32@0+ (1,0) [0|4294967295] ""  XCD

BO_ 661 ADD_ChassisFusion_0x295: 32 ADD
 SG_ ADSRCTBBrkReqFrmADD : 31|1@0+ (1,0) [0|1] ""  BCS,XCD
 SG_ ADSRCTBBrkSigGrpChks : 7|8@0+ (1,0) [0|255] ""  BCS,XCD
 SG_ ADSRCTBBrkSigGrpCntr : 11|4@0+ (1,0) [0|15] ""  BCS,XCD
 SG_ ADSRCTBTarDecelFrmADD : 23|8@0+ (0.05,-10) [-10|2.75] "mps2"  BCS,XCD
 SG_ BmpTrk1ConfFrmADD : 199|7@0+ (1,0) [0|127] "%"  FZCU,SCU
 SG_ BmpTrk1HeiFrmADD : 231|16@0+ (0.05,-1638.4) [-1638.4|1638.35] ""  FZCU,SCU
 SG_ BmpTrk1TypFrmADD : 207|5@0+ (1,0) [0|31] ""  FZCU,SCU
 SG_ BmpTrk2ConfFrmADD : 183|7@0+ (1,0) [0|127] ""  FZCU,SCU
 SG_ BmpTrk2HeiFrmADD : 167|16@0+ (0.05,-1638.4) [-1638.4|1638.35] ""  FZCU,SCU
 SG_ BmpTrk2TypFrmADD : 191|5@0+ (1,0) [0|31] ""  FZCU,SCU
 SG_ Road1EndPotXRiFrmADD : 39|16@0+ (0.1,-3276.8) [-3276.8|3276.7] ""  FZCU,SCU
 SG_ Road1EndPotYRiFrmADD : 103|16@0+ (0.1,-3276.8) [-3276.8|3276.7] ""  FZCU,SCU
 SG_ Road1StrtPotXLeFrmADD : 55|16@0+ (0.1,-3276.8) [-3276.8|3276.7] ""  FZCU,SCU
 SG_ Road1StrtPotYLeFrmADD : 119|16@0+ (0.1,-3276.8) [-3276.8|3276.7] ""  FZCU,SCU
 SG_ Road2EndPotXRiFrmADD : 71|16@0+ (0.1,-3276.8) [-3276.8|3276.7] ""  FZCU,SCU
 SG_ Road2EndPotYRiFrmADD : 135|16@0+ (0.1,-3276.8) [-3276.8|3276.7] ""  FZCU,SCU
 SG_ Road2StrtPotXLeFrmADD : 87|16@0+ (0.1,-3276.8) [-3276.8|3276.7] ""  FZCU,SCU
 SG_ Road2StrtPotYLeFrmADD : 151|16@0+ (0.1,-3276.8) [-3276.8|3276.7] ""  FZCU,SCU

BO_ 688 ADD_ChassisFusion_0x2B0: 16 ADD
 SG_ ADDCooltFlowReqFrmADD : 79|6@0+ (0.25,0) [0|15.75] "Lpmin"  FZCU
 SG_ ADDFaultInfoFlag : 7|1@0+ (1,0) [0|1] ""  XCD
 SG_ ADDTValFrmADD : 71|8@0+ (1,-40) [-40|215] "degC"  FZCU
 SG_ ADSLrnUnavlRsnFrmADD : 6|3@0+ (1,0) [0|4] ""  XCD
 SG_ ADSParkSpdSwtStsFrmADD : 95|3@0+ (1,0) [0|7] ""  XCD
 SG_ ADSParkSpdSwtUnavlRsnFrmADD : 3|4@0+ (1,0) [0|15] ""  XCD
 SG_ APASwtStsFrmADD : 23|3@0+ (1,0) [0|7] ""  XCD
 SG_ APASwtUnavlRsnFrmADD : 47|4@0+ (1,0) [0|15] ""  XCD
 SG_ AutoVehCustEIPSwtFrmADD : 87|3@0+ (1,0) [0|4] ""  XCD
 SG_ AutoVehCustEIPSwtRsnFrmADD : 84|2@0+ (1,0) [0|3] ""  XCD
 SG_ AutoVehSrvAuthntStsFrmADD : 82|3@0+ (1,0) [0|4] ""  XCD
 SG_ AutoVehSrvAuthntStsRsnFrmADD : 73|2@0+ (1,0) [0|3] ""  XCD
 SG_ AvmCamTriggerModReqFrmADD : 91|2@0+ (1,0) [0|3] ""  XCD
 SG_ AVPSwtStsFrmADD : 31|3@0+ (1,0) [0|7] ""  XCD
 SG_ AVPSwtUnavlRsnFrmADD : 43|4@0+ (1,0) [0|15] ""  XCD
 SG_ HPPBckGrLearFrmADD : 28|3@0+ (1,0) [0|7] ""  XCD
 SG_ HPPBckGrLearUnavlRsnFrmADD : 55|4@0+ (1,0) [0|15] ""  XCD
 SG_ HPPSwtStsFrmADD : 39|3@0+ (1,0) [0|7] ""  XCD
 SG_ HPPSwtUnavlRsnFrmADD : 51|4@0+ (1,0) [0|15] ""  XCD
 SG_ ParkSwtStsSigGrpChks : 15|8@0+ (1,0) [0|255] ""  XCD
 SG_ ParkSwtStsSigGrpCntr : 19|4@0+ (1,0) [0|15] ""  XCD
 SG_ RPASentryQuit : 92|1@0+ (1,0) [0|1] ""  XCD

BO_ 693 ADD_ChassisFusion_0x2B5: 64 ADD
 SG_ ParkOutTarDirFrmADD : 143|2@0+ (1,0) [0|3] ""  XCD
 SG_ ParkSlotTarFrmADD : 151|5@0+ (1,0) [0|31] ""  XCD
 SG_ ParkTarPosnSigGrpChks : 135|8@0+ (1,0) [0|255] ""  XCD
 SG_ ParkTarPosnSigGrpCntr : 139|4@0+ (1,0) [0|15] ""  XCD
 SG_ PASBuzzerWarnMuteReqFrmADD : 119|1@0+ (1,0) [0|1] ""  XCD
 SG_ PASDistanceLevSigGrpChks : 423|8@0+ (1,0) [0|255] ""  XCD
 SG_ PASDistanceLevSigGrpCntr : 427|4@0+ (1,0) [0|15] ""  XCD
 SG_ PASDistanceSystemGrpChks : 159|8@0+ (1,0) [0|255] ""  XCD
 SG_ PASDistanceSystemGrpCntr : 163|4@0+ (1,0) [0|15] ""  XCD
 SG_ PASFCBuzzerWarnFrmADD : 118|3@0+ (1,0) [0|7] ""  XCD
 SG_ PASFLBuzzerSigGrpChks : 95|8@0+ (1,0) [0|255] ""  XCD
 SG_ PASFLBuzzerSigGrpCntr : 99|4@0+ (1,0) [0|15] ""  XCD
 SG_ PASFLBuzzerWarnFrmADD : 115|3@0+ (1,0) [0|7] ""  XCD
 SG_ PASFLDistanceFrmADD : 175|10@0+ (1,0) [0|550] "cm"  XCD
 SG_ PASFLDistanceLevFrmADD : 439|3@0+ (1,0) [0|7] ""  XCD
 SG_ PASFMLDistanceFrmADD : 177|10@0+ (1,0) [0|550] "cm"  XCD
 SG_ PASFMLDistanceLevFrmADD : 436|3@0+ (1,0) [0|7] ""  XCD
 SG_ PASFMRDistanceFrmADD : 199|10@0+ (1,0) [0|550] "cm"  XCD
 SG_ PASFMRDistanceLevFrmADD : 447|3@0+ (1,0) [0|7] ""  XCD
 SG_ PASFRBuzzerWarnFrmADD : 111|3@0+ (1,0) [0|7] ""  XCD
 SG_ PASFRDistanceFrmADD : 201|10@0+ (1,0) [0|550] "cm"  XCD
 SG_ PASFRDistanceLevFrmADD : 444|3@0+ (1,0) [0|7] ""  XCD
 SG_ PASFSLDistanceFrmADD : 367|10@0+ (1,0) [0|550] "cm"  XCD
 SG_ PASFSLDistanceLevFrmADD : 455|3@0+ (1,0) [0|7] ""  XCD
 SG_ PASFSRDistanceFrmADD : 369|10@0+ (1,0) [0|550] "cm"  XCD
 SG_ PASFSRDistanceLevFrmADD : 452|3@0+ (1,0) [0|7] ""  XCD
 SG_ PASRLBuzzerWarnFrmADD : 108|3@0+ (1,0) [0|7] ""  XCD
 SG_ PASRLDistanceFrmADD : 223|10@0+ (1,0) [0|550] "cm"  XCD
 SG_ PASRLDistanceLevFrmADD : 463|3@0+ (1,0) [0|7] ""  XCD
 SG_ PASRMLDistanceFrmADD : 225|10@0+ (1,0) [0|550] "cm"  XCD
 SG_ PASRMLDistanceLevFrmADD : 460|3@0+ (1,0) [0|7] ""  XCD
 SG_ PASRMRDistanceFrmADD : 247|10@0+ (1,0) [0|550] "cm"  XCD
 SG_ PASRMRDistanceLevFrmADD : 471|3@0+ (1,0) [0|7] ""  XCD
 SG_ PASRRBuzzerWarnFrmADD : 127|3@0+ (1,0) [0|7] ""  XCD
 SG_ PASRRDistanceFrmADD : 249|10@0+ (1,0) [0|550] "cm"  XCD
 SG_ PASRRDistanceLevFrmADD : 468|3@0+ (1,0) [0|7] ""  XCD
 SG_ PASRSLDistanceFrmADD : 391|10@0+ (1,0) [0|550] "cm"  XCD
 SG_ PASRSLDistanceLevFrmADD : 479|3@0+ (1,0) [0|7] ""  XCD
 SG_ PASRSRDistanceFrmADD : 393|10@0+ (1,0) [0|550] "cm"  XCD
 SG_ PASRSRDistanceLevFrmADD : 476|3@0+ (1,0) [0|7] ""  XCD
 SG_ PASSDWFLSideDistanceFrmADD : 271|10@0+ (1,0) [0|550] "cm"  XCD
 SG_ PASSDWFLSideDistanceLevFrmADD : 487|3@0+ (1,0) [0|7] ""  XCD
 SG_ PASSDWFMLSideDistanceFrmADD : 273|10@0+ (1,0) [0|550] "cm"  XCD
 SG_ PASSDWFMLSideDistanceLevFrmADD : 484|3@0+ (1,0) [0|7] ""  XCD
 SG_ PASSDWFMRSideDistanceFrmADD : 295|10@0+ (1,0) [0|550] "cm"  XCD
 SG_ PASSDWFMRSideDistanceLevFrmADD : 495|3@0+ (1,0) [0|7] ""  XCD
 SG_ PASSDWFRSideDistanceFrmADD : 297|10@0+ (1,0) [0|550] "cm"  XCD
 SG_ PASSDWFRSideDistanceLevFrmADD : 492|3@0+ (1,0) [0|7] ""  XCD
 SG_ PASSDWRLSideDistanceFrmADD : 319|10@0+ (1,0) [0|550] "cm"  XCD
 SG_ PASSDWRLSideDistanceLevFrmADD : 503|3@0+ (1,0) [0|7] ""  XCD
 SG_ PASSDWRMLSideDistanceFrmADD : 321|10@0+ (1,0) [0|550] "cm"  XCD
 SG_ PASSDWRMLSideDistanceLevFrmADD : 500|3@0+ (1,0) [0|7] ""  XCD
 SG_ PASSDWRMRSideDistanceFrmADD : 343|10@0+ (1,0) [0|550] "cm"  XCD
 SG_ PASSDWRMRSideDistanceLevFrmADD : 511|3@0+ (1,0) [0|7] ""  XCD
 SG_ PASSDWRRSideDistanceFrmADD : 345|10@0+ (1,0) [0|550] "cm"  XCD
 SG_ PASSDWRRSideDistanceLevFrmADD : 508|3@0+ (1,0) [0|7] ""  XCD

BO_ 775 ADD_ChassisFusion_0x307: 32 ADD
 SG_ ParkProgressSigLFPosXFrmADD : 55|16@0+ (0.01,-327.67) [-327.67|327.68] "m"  XCD
 SG_ ParkProgressSigLFPosYFrmADD : 71|16@0+ (0.01,-327.67) [-327.67|327.68] "m"  XCD
 SG_ ParkProgressSigLRPosXFrmADD : 87|16@0+ (0.01,-327.67) [-327.67|327.68] "m"  XCD
 SG_ ParkProgressSigLRPosYFrmADD : 103|16@0+ (0.01,-327.67) [-327.67|327.68] "m"  XCD
 SG_ ParkProgressSigRFPosXFrmADD : 119|16@0+ (0.01,-327.67) [-327.67|327.68] "m"  XCD
 SG_ ParkProgressSigRFPosYFrmADD : 135|16@0+ (0.01,-327.67) [-327.67|327.68] "m"  XCD
 SG_ ParkProgressSigRRPosXFrmADD : 151|16@0+ (0.01,-327.67) [-327.67|327.68] "m"  XCD
 SG_ ParkProgressSigRRPosYFrmADD : 167|16@0+ (0.01,-327.67) [-327.67|327.68] "m"  XCD
 SG_ PASProgressSigGrpChks : 39|8@0+ (1,0) [0|255] ""  XCD
 SG_ PASProgressSigGrpCntr : 43|4@0+ (1,0) [0|15] ""  XCD
 SG_ PASSubFunAvaiFrmADD : 15|3@0+ (1,0) [0|7] ""  XCD
 SG_ PASWorkingModeFrmADD : 23|3@0+ (1,0) [0|7] ""  XCD
 SG_ PASWorkingModeSigGrpChks : 7|8@0+ (1,0) [0|255] ""  XCD
 SG_ PASWorkingModeSigGrpCntr : 11|4@0+ (1,0) [0|15] ""  XCD

BO_ 873 ADD_ChassisFusion_0x369: 8 ADD
 SG_ LowPwrReqFrLdrFrmADD : 23|2@0+ (1,0) [0|2] ""  XCD
 SG_ LowPwrReqFrRdrFrmADD : 21|2@0+ (1,0) [0|2] ""  FZCU,XCD

BO_ 238 ADD_ChassisFusion_0xEE: 32 ADD
 SG_ ADD2BLEMForRPA00 : 7|64@0+ (1,0) [0|1.84467440737096E+019] ""  XCD
 SG_ ADD2BLEMForRPA00FV : 215|16@0+ (1,0) [0|65535] ""  XCD
 SG_ ADD2BLEMForRPA00MAC : 231|32@0+ (1,0) [0|0] ""  XCD
 SG_ ADD2BLEMForRPA01 : 71|64@0+ (1,0) [0|1.84467440737096E+019] ""  XCD
 SG_ ADD2BLEMForRPA02 : 135|64@0+ (1,0) [0|1.84467440737096E+019] ""  XCD
 SG_ ADD2BLEMForRPA03 : 199|16@0+ (1,0) [0|65535] ""  XCD

BO_ 239 ADD_ChassisFusion_0xEF: 24 ADD
 SG_ ADDIMUSigGrpChks : 7|8@0+ (1,0) [0|255] ""  FZCU,SCU,VECU
 SG_ ADDIMUSigGrpCntr : 11|4@0+ (1,0) [0|15] ""  FZCU,SCU,VECU
 SG_ XAccelStaFrmADD : 33|2@0+ (1,0) [0|3] ""  FZCU,SCU,VECU
 SG_ XAccelValFrmADD : 23|20@0+ (0.001,-98.1) [-98.1|98.1] "m/s^2"  FZCU,SCU,VECU
 SG_ XAngRateStaFrmADD : 177|2@0+ (1,0) [0|3] ""  FZCU,SCU,VECU
 SG_ XAngRateValFrmADD : 47|22@0+ (1E-005,-8.72665) [-8.72665|8.72665] "rad/s"  FZCU,SCU,VECU
 SG_ YAccelStaFrmADD : 161|2@0+ (1,0) [0|3] ""  FZCU,SCU,VECU
 SG_ YAccelValFrmADD : 71|20@0+ (0.001,-98.1) [-98.1|98.1] "m/s^2"  FZCU,SCU,VECU
 SG_ YAngRateStaFrmADD : 163|2@0+ (1,0) [0|3] ""  FZCU,SCU,VECU
 SG_ YAngRateValFrmADD : 95|22@0+ (1E-005,-8.72665) [-8.72665|8.72665] "rad/s"  FZCU,SCU,VECU
 SG_ ZAccelStaFrmADD : 171|2@0+ (1,0) [0|3] ""  FZCU,SCU,VECU
 SG_ ZAccelValFrmADD : 119|20@0+ (0.001,-98.1) [-98.1|98.1] "m/s^2"  FZCU,SCU,VECU
 SG_ ZAngRateStaFrmADD : 169|2@0+ (1,0) [0|3] ""  FZCU,SCU,VECU
 SG_ ZAngRateValFrmADD : 143|22@0+ (1E-005,-8.72665) [-8.72665|8.72665] "rad/s"  FZCU,SCU,VECU

BO_ 1331 ADDChassisFusionCanfdNMFrA: 8 ADD
 SG_ ADDChassisBkpActiveWakeup : 12|1@0+ (1,0) [0|1] "" Vector__XXX
 SG_ ADDChassisBkpNodeAddress : 7|8@0+ (1,0) [0|255] "" Vector__XXX
 SG_ ADDChassisBkpRepeatMsgReq : 8|1@0+ (1,0) [0|1] "" Vector__XXX
 SG_ ADDChassisBkpRepeatMsgSt : 16|1@0+ (1,0) [0|1] "" Vector__XXX
 SG_ NMKeepAwkRsnADD : 48|9@0+ (1,0) [0|511] "" Vector__XXX
 SG_ UDB17ADD : 17|1@0+ (1,0) [0|1] "" Vector__XXX
 SG_ UDB18ADD : 18|1@0+ (1,0) [0|1] "" Vector__XXX
 SG_ UDB19ADD : 19|1@0+ (1,0) [0|1] "" Vector__XXX
 SG_ UDB20ADD : 20|1@0+ (1,0) [0|1] "" Vector__XXX
 SG_ UDB21ADD : 21|1@0+ (1,0) [0|1] "" Vector__XXX
 SG_ UDB22ADD : 22|1@0+ (1,0) [0|1] "" Vector__XXX
 SG_ UDB23ADD : 23|1@0+ (1,0) [0|1] "" Vector__XXX
 SG_ UDB24ADD : 24|1@0+ (1,0) [0|1] "" Vector__XXX
 SG_ UDB25ADD : 25|1@0+ (1,0) [0|1] "" Vector__XXX
 SG_ UDB26ADD : 26|1@0+ (1,0) [0|1] "" Vector__XXX
 SG_ UDB27ADD : 27|1@0+ (1,0) [0|1] "" Vector__XXX
 SG_ UDB28ADD : 28|1@0+ (1,0) [0|1] "" Vector__XXX
 SG_ UDB29ADD : 29|1@0+ (1,0) [0|1] "" Vector__XXX
 SG_ UDB30ADD : 30|1@0+ (1,0) [0|1] "" Vector__XXX
 SG_ UDB31ADD : 31|1@0+ (1,0) [0|1] "" Vector__XXX
 SG_ UDB32ADD : 32|1@0+ (1,0) [0|1] "" Vector__XXX
 SG_ UDB33ADD : 33|1@0+ (1,0) [0|1] "" Vector__XXX
 SG_ UDB34ADD : 34|1@0+ (1,0) [0|1] "" Vector__XXX
 SG_ UDB35ADD : 35|1@0+ (1,0) [0|1] "" Vector__XXX
 SG_ UDB36ADD : 36|1@0+ (1,0) [0|1] "" Vector__XXX
 SG_ UDB37ADD : 37|1@0+ (1,0) [0|1] "" Vector__XXX
 SG_ UDB38ADD : 38|1@0+ (1,0) [0|1] "" Vector__XXX
 SG_ UDB39ADD : 39|1@0+ (1,0) [0|1] "" Vector__XXX
 SG_ UDB40ADD : 40|1@0+ (1,0) [0|1] "" Vector__XXX
 SG_ UDB41ADD : 41|1@0+ (1,0) [0|1] "" Vector__XXX
 SG_ UDB42ADD : 42|1@0+ (1,0) [0|1] "" Vector__XXX
 SG_ UDB43ADD : 43|1@0+ (1,0) [0|1] "" Vector__XXX
 SG_ UDB44ADD : 44|1@0+ (1,0) [0|1] "" Vector__XXX
 SG_ UDB45ADD : 45|1@0+ (1,0) [0|1] "" Vector__XXX
 SG_ UDB46ADD : 46|1@0+ (1,0) [0|1] "" Vector__XXX
 SG_ UDB47ADD : 47|1@0+ (1,0) [0|1] "" Vector__XXX

BO_ 1326 ADDChassisFusionCanfdNMFrB: 8 ADD
 SG_ ADDChassisBkpActiveWakeup1 : 12|1@0+ (1,0) [0|1] ""  VECU
 SG_ ADDChassisBkpNodeAddress1 : 7|8@0+ (1,0) [0|255] ""  VECU
 SG_ ADDChassisBkpRepeatMsgReq1 : 8|1@0+ (1,0) [0|1] ""  VECU
 SG_ ADDChassisBkpRepeatMsgSt1 : 16|1@0+ (1,0) [0|1] ""  VECU
 SG_ NMKeepAwkRsnADD : 48|9@0+ (1,0) [0|511] "" Vector__XXX
 SG_ UDB17ADD : 17|1@0+ (1,0) [0|1] "" Vector__XXX
 SG_ UDB18ADD : 18|1@0+ (1,0) [0|1] "" Vector__XXX
 SG_ UDB19ADD : 19|1@0+ (1,0) [0|1] "" Vector__XXX
 SG_ UDB20ADD : 20|1@0+ (1,0) [0|1] "" Vector__XXX
 SG_ UDB21ADD : 21|1@0+ (1,0) [0|1] "" Vector__XXX
 SG_ UDB22ADD : 22|1@0+ (1,0) [0|1] "" Vector__XXX
 SG_ UDB23ADD : 23|1@0+ (1,0) [0|1] "" Vector__XXX
 SG_ UDB24ADD : 24|1@0+ (1,0) [0|1] "" Vector__XXX
 SG_ UDB25ADD : 25|1@0+ (1,0) [0|1] "" Vector__XXX
 SG_ UDB26ADD : 26|1@0+ (1,0) [0|1] "" Vector__XXX
 SG_ UDB27ADD : 27|1@0+ (1,0) [0|1] "" Vector__XXX
 SG_ UDB28ADD : 28|1@0+ (1,0) [0|1] "" Vector__XXX
 SG_ UDB29ADD : 29|1@0+ (1,0) [0|1] "" Vector__XXX
 SG_ UDB30ADD : 30|1@0+ (1,0) [0|1] "" Vector__XXX
 SG_ UDB31ADD : 31|1@0+ (1,0) [0|1] "" Vector__XXX
 SG_ UDB32ADD : 32|1@0+ (1,0) [0|1] "" Vector__XXX
 SG_ UDB33ADD : 33|1@0+ (1,0) [0|1] "" Vector__XXX
 SG_ UDB34ADD : 34|1@0+ (1,0) [0|1] "" Vector__XXX
 SG_ UDB35ADD : 35|1@0+ (1,0) [0|1] "" Vector__XXX
 SG_ UDB36ADD : 36|1@0+ (1,0) [0|1] "" Vector__XXX
 SG_ UDB37ADD : 37|1@0+ (1,0) [0|1] "" Vector__XXX
 SG_ UDB38ADD : 38|1@0+ (1,0) [0|1] "" Vector__XXX
 SG_ UDB39ADD : 39|1@0+ (1,0) [0|1] "" Vector__XXX
 SG_ UDB40ADD : 40|1@0+ (1,0) [0|1] "" Vector__XXX
 SG_ UDB41ADD : 41|1@0+ (1,0) [0|1] "" Vector__XXX
 SG_ UDB42ADD : 42|1@0+ (1,0) [0|1] "" Vector__XXX
 SG_ UDB43ADD : 43|1@0+ (1,0) [0|1] "" Vector__XXX
 SG_ UDB44ADD : 44|1@0+ (1,0) [0|1] "" Vector__XXX
 SG_ UDB45ADD : 45|1@0+ (1,0) [0|1] "" Vector__XXX
 SG_ UDB46ADD : 46|1@0+ (1,0) [0|1] "" Vector__XXX
 SG_ UDB47ADD : 47|1@0+ (1,0) [0|1] "" Vector__XXX

BO_ 336 BCP_ChassisFusion_0x150: 16 BCP
 SG_ ABAActv : 94|1@0+ (1,0) [0|1] "" Vector__XXX
 SG_ ABAAvl : 95|1@0+ (1,0) [0|1] "" Vector__XXX
 SG_ APBAplAvlBCP : 61|2@0+ (1,0) [0|2] ""  SCU
 SG_ APBRelAvlBCP : 59|2@0+ (1,0) [0|3] ""  SCU
 SG_ APBStsBkp : 91|3@0+ (1,0) [0|7] "" Vector__XXX
 SG_ BCPBrkLiIllmnReq : 19|1@0+ (1,0) [0|1] ""  SCU
 SG_ BCPBrkSysWarnText : 45|3@0+ (1,0) [0|7] ""  SCU
 SG_ BCPFaultInfoFlag : 109|1@0+ (1,0) [0|1] "" Vector__XXX
 SG_ BCPKeepAwakeReq : 111|1@0+ (1,0) [0|1] "" Vector__XXX
 SG_ BCPMstCylP : 57|10@0+ (0.3,-30) [-30|276.6] "bar"  SCU
 SG_ BCPMstCylPVld : 15|2@0+ (1,0) [0|2] ""  SCU
 SG_ BCPSimulatorP : 41|10@0+ (0.3,-30) [-30|276.6] "bar"  SCU
 SG_ BCPSimulatorPVld : 63|2@0+ (1,0) [0|2] ""  SCU
 SG_ BCPSysSts : 47|2@0+ (1,0) [0|3] ""  SCU
 SG_ BcpSysStsSigGrpChks : 7|8@0+ (1,0) [0|255] ""  SCU
 SG_ BcpSysStsSigGrpCntr : 11|4@0+ (1,0) [0|15] ""  SCU
 SG_ BrkAssSigGrpChks : 79|8@0+ (1,0) [0|255] "" Vector__XXX
 SG_ BrkAssSigGrpCntr : 83|4@0+ (1,0) [0|15] "" Vector__XXX
 SG_ BrkFldWarn : 23|1@0+ (1,0) [0|1] ""  SCU
 SG_ BrkFldWarnVld : 42|1@0+ (1,0) [0|1] ""  SCU
 SG_ BrkPedlAppld : 22|1@0+ (1,0) [0|1] ""  SCU
 SG_ BrkPedlAppldVld : 21|2@0+ (1,0) [0|3] ""  SCU
 SG_ BrkPedlPerct : 38|7@0+ (1,0) [0|100] "%"  SCU
 SG_ BrkPedlPerctVld : 39|1@0+ (1,0) [0|1] ""  SCU
 SG_ HBAActv : 92|1@0+ (1,0) [0|1] "" Vector__XXX
 SG_ HBAAvl : 93|1@0+ (1,0) [0|1] "" Vector__XXX
 SG_ HBBActv : 110|1@0+ (1,0) [0|1] "" Vector__XXX
 SG_ InpRodStk : 17|10@0+ (0.05,-5) [-5|46.1] "mm"  SCU
 SG_ InpRodStkVld : 18|1@0+ (1,0) [0|1] ""  SCU

BO_ 340 BCP_ChassisFusion_0x154: 24 BCP
 SG_ ActCirNoPressureQ : 23|2@0+ (1,0) [0|2] ""  BCS,FZCU,XCD
 SG_ APBAplAvlBCPFusion : 167|2@0+ (1,0) [0|2] ""  BCS,FZCU,XCD
 SG_ APBRelAvlBCPFusion : 165|2@0+ (1,0) [0|3] ""  BCS,FZCU,XCD
 SG_ APBStsBkpFusion : 131|3@0+ (1,0) [0|4] ""  BCS,FZCU,XCD
 SG_ BCPBrkSysActCircNoP : 39|1@0+ (1,0) [0|1] ""  BCS,FZCU,XCD
 SG_ BcpBrkSysCtrlBkpSigGrpChks : 103|8@0+ (1,0) [0|255] ""  BCS,FZCU,XCD
 SG_ BcpBrkSysCtrlBkpSigGrpCntr : 107|4@0+ (1,0) [0|15] ""  BCS,FZCU,XCD
 SG_ BCPBrkSysFTarDrvr : 21|14@0+ (8,-131008) [-131008|0] "N"  BCS,FZCU,XCD
 SG_ BCPBrkSysFTarDrvrVld : 38|2@0+ (1,0) [0|3] ""  BCS,FZCU,XCD
 SG_ BCPSysCtrlSigGrpChks : 7|8@0+ (1,0) [0|255] ""  BCS,FZCU,XCD
 SG_ BCPSysCtrlSigGrpCntr : 11|4@0+ (1,0) [0|15] ""  BCS,FZCU,XCD
 SG_ BrkSysActCircNoP : 151|1@0+ (1,0) [0|1] ""  BCS,FZCU,XCD
 SG_ BrkSysBCPDiagActv : 149|1@0+ (1,0) [0|1] ""  BCS,FZCU,XCD
 SG_ BrkSysCmptIdx : 135|4@0+ (1,0) [0|15] ""  BCS,FZCU,XCD
 SG_ BrkSysHBCReq : 150|1@0+ (1,0) [0|1] ""  BCS,FZCU,XCD
 SG_ BrkSysPRnt : 143|8@0+ (1,0) [0|250] "bar"  BCS,FZCU,XCD
 SG_ BrkSysPRntVld : 148|2@0+ (1,0) [0|3] ""  BCS,FZCU,XCD
 SG_ InpRodStkBkp : 33|10@0+ (0.05,-5) [-5|46.1] "mm"  BCS,FZCU,XCD
 SG_ InpRodStkBkpVld : 36|1@0+ (1,0) [0|1] ""  BCS,FZCU,XCD
 SG_ RPBActrStSec : 175|3@0+ (1,0) [0|7] ""  BCS,FZCU,XCD
 SG_ RpbBkpSigGrpChks : 159|8@0+ (1,0) [0|255] ""  BCS,FZCU,XCD
 SG_ RpbBkpSigGrpCntr : 163|4@0+ (1,0) [0|15] ""  BCS,FZCU,XCD
 SG_ RPBRPBCoornSec : 183|8@0+ (1,0) [0|255] ""  BCS,FZCU,XCD

BO_ 344 BCP_ChassisFusion_0x158: 8 BCP
 SG_ BCPKeepAwakeReqBkp : 63|1@0+ (1,0) [0|1] ""  FZCU,XCD

BO_ 487 BCP_ChassisFusion_0x1E7: 24 BCP
 SG_ BcpBrkSysBkpSigGrpChks : 31|8@0+ (1,0) [0|255] ""  BCS,XCD
 SG_ BcpBrkSysBkpSigGrpCntr : 35|4@0+ (1,0) [0|15] ""  BCS,XCD
 SG_ BcpBrkSysIndcnBkpSigGrpChks : 103|8@0+ (1,0) [0|255] ""  ADD,BCS,FZCU,XCD
 SG_ BcpBrkSysIndcnBkpSigGrpCntr : 107|4@0+ (1,0) [0|15] ""  ADD,BCS,FZCU,XCD
 SG_ BCPDrvBrakeActType : 159|3@0+ (1,0) [0|4] ""  BCS,XCD
 SG_ BCPRecuStatusAct : 185|2@0+ (1,0) [0|2] ""  BCS,XCD
 SG_ BrkSysAPBBkp2MainSafeLimCom2 : 15|2@0+ (1,0) [0|3] ""  BCS,XCD
 SG_ BrkSysAPBParkBrkReqBkp2MainCom2 : 22|3@0+ (1,0) [0|7] ""  BCS,XCD
 SG_ BrkSysAPCBkp2MainStCom2 : 19|4@0+ (1,0) [0|15] ""  BCS,XCD
 SG_ BrkSysAPCBkpSigGrpChks : 7|8@0+ (1,0) [0|255] ""  BCS,XCD
 SG_ BrkSysAPCBkpSigGrpCntr : 11|4@0+ (1,0) [0|15] ""  BCS,XCD
 SG_ BrkSysBCPLdmBrkActActr : 39|2@0+ (1,0) [0|3] ""  BCS,XCD
 SG_ BrkSysBCPLdmBrkActAxle : 37|2@0+ (1,0) [0|3] ""  BCS,XCD
 SG_ BrkSysBCPLdmBrkActGenr : 77|2@0+ (1,0) [0|3] ""  BCS,XCD
 SG_ BrkSysBCPLdmBrkActTyp : 61|3@0+ (1,0) [0|7] ""  BCS,XCD
 SG_ BrkSysBCPLdmSysModReq : 58|3@0+ (1,0) [0|7] ""  BCS,XCD
 SG_ BrkSysBrkPedlAppld : 111|1@0+ (1,0) [0|1] ""  ADD,BCS,FZCU,XCD
 SG_ BrkSysBrkPedlAppldVld : 110|2@0+ (1,0) [0|3] ""  ADD,BCS,FZCU,XCD
 SG_ BrkSysEnaActvCtrlByDrvr : 108|1@0+ (1,0) [0|1] ""  ADD,BCS,FZCU,XCD
 SG_ BrkSysFTarDrvr : 127|11@0+ (64,-131008) [-131008|0] "N"  ADD,BCS,FZCU,XCD
 SG_ BrkSysFTarDrvrVld : 132|2@0+ (1,0) [0|3] ""  ADD,BCS,FZCU,XCD
 SG_ BrkSysLdmFTarBrkBCP : 47|13@0+ (8,-65472) [-65472|0] "N"  BCS,XCD
 SG_ BrkSysLdmFTarBrkBCPVld : 75|2@0+ (1,0) [0|3] ""  BCS,XCD
 SG_ BrkSysLdmFTarMaxPt : 71|10@0- (64,0) [-32768|32704] "N"  BCS,XCD
 SG_ BrkSysLdmFTarMinPt : 73|10@0- (64,0) [-32768|32704] "N"  BCS,XCD
 SG_ BrkSysLdmGlbStsAct : 95|2@0+ (1,0) [0|3] ""  BCS,XCD
 SG_ BrkSysParkBrkReq : 93|3@0+ (1,0) [0|7] ""  BCS,XCD
 SG_ BrkSysPRednPotnl : 119|8@0+ (0.5,0) [0|120] "bar"  ADD,BCS,FZCU,XCD
 SG_ BrkSysPRednPotnlVld : 130|2@0+ (1,0) [0|3] ""  ADD,BCS,FZCU,XCD
 SG_ BrkSysWarnLampReq : 143|2@0+ (1,0) [0|3] ""  ADD,BCS,FZCU,XCD
 SG_ FxTargetDriverMinFrict : 175|14@0+ (8,-131008) [-131008|0] "bar"  BCS,XCD
 SG_ RecuSuppressEna : 156|1@0+ (1,0) [0|1] ""  BCS,XCD
 SG_ RPBHydPSpprtChks : 151|8@0+ (1,0) [0|255] ""  BCS,XCD
 SG_ RPBHydPSpprtCntr : 155|4@0+ (1,0) [0|14] ""  BCS,XCD
 SG_ RPBHydPSpprtP : 167|8@0+ (1,0) [0|180] "bar"  BCS,XCD
 SG_ RPBHydPSpprtReq : 177|2@0+ (1,0) [0|3] ""  BCS,XCD

BO_ 1318 BCPChassisFusionNMFr: 8 BCP
 SG_ BCPChassisBkpActiveWakeup : 12|1@0+ (1,0) [0|1] "" Vector__XXX
 SG_ BCPChassisBkpNodeAddress : 7|8@0+ (1,0) [0|255] "" Vector__XXX
 SG_ BCPChassisBkpRepeatMsgReq : 8|1@0+ (1,0) [0|1] "" Vector__XXX
 SG_ BCPChassisBkpRepeatMsgSt : 16|1@0+ (1,0) [0|1] "" Vector__XXX
 SG_ NMKeepAwkRsnBCP : 48|9@0+ (1,0) [0|511] "" Vector__XXX
 SG_ UDB17BCP : 17|1@0+ (1,0) [0|1] "" Vector__XXX
 SG_ UDB18BCP : 18|1@0+ (1,0) [0|1] "" Vector__XXX
 SG_ UDB19BCP : 19|1@0+ (1,0) [0|1] "" Vector__XXX
 SG_ UDB20BCP : 20|1@0+ (1,0) [0|1] "" Vector__XXX
 SG_ UDB21BCP : 21|1@0+ (1,0) [0|1] "" Vector__XXX
 SG_ UDB22BCP : 22|1@0+ (1,0) [0|1] "" Vector__XXX
 SG_ UDB23BCP : 23|1@0+ (1,0) [0|1] "" Vector__XXX
 SG_ UDB24BCP : 24|1@0+ (1,0) [0|1] "" Vector__XXX
 SG_ UDB25BCP : 25|1@0+ (1,0) [0|1] "" Vector__XXX
 SG_ UDB26BCP : 26|1@0+ (1,0) [0|1] "" Vector__XXX
 SG_ UDB27BCP : 27|1@0+ (1,0) [0|1] "" Vector__XXX
 SG_ UDB28BCP : 28|1@0+ (1,0) [0|1] "" Vector__XXX
 SG_ UDB29BCP : 29|1@0+ (1,0) [0|1] "" Vector__XXX
 SG_ UDB30BCP : 30|1@0+ (1,0) [0|1] "" Vector__XXX
 SG_ UDB31BCP : 31|1@0+ (1,0) [0|1] "" Vector__XXX
 SG_ UDB32BCP : 32|1@0+ (1,0) [0|1] "" Vector__XXX
 SG_ UDB33BCP : 33|1@0+ (1,0) [0|1] "" Vector__XXX
 SG_ UDB34BCP : 34|1@0+ (1,0) [0|1] "" Vector__XXX
 SG_ UDB35BCP : 35|1@0+ (1,0) [0|1] "" Vector__XXX
 SG_ UDB36BCP : 36|1@0+ (1,0) [0|1] "" Vector__XXX
 SG_ UDB37BCP : 37|1@0+ (1,0) [0|1] "" Vector__XXX
 SG_ UDB38BCP : 38|1@0+ (1,0) [0|1] "" Vector__XXX
 SG_ UDB39BCP : 39|1@0+ (1,0) [0|1] "" Vector__XXX
 SG_ UDB40BCP : 40|1@0+ (1,0) [0|1] "" Vector__XXX
 SG_ UDB41BCP : 41|1@0+ (1,0) [0|1] "" Vector__XXX
 SG_ UDB42BCP : 42|1@0+ (1,0) [0|1] "" Vector__XXX
 SG_ UDB43BCP : 43|1@0+ (1,0) [0|1] "" Vector__XXX
 SG_ UDB44BCP : 44|1@0+ (1,0) [0|1] "" Vector__XXX
 SG_ UDB45BCP : 45|1@0+ (1,0) [0|1] "" Vector__XXX
 SG_ UDB46BCP : 46|1@0+ (1,0) [0|1] "" Vector__XXX
 SG_ UDB47BCP : 47|1@0+ (1,0) [0|1] "" Vector__XXX

BO_ 337 BCS_ChassisFusion_0x151: 32 BCS
 SG_ ABPActv : 191|1@0+ (1,0) [0|1] "" Vector__XXX
 SG_ ABPAvl : 197|1@0+ (1,0) [0|1] "" Vector__XXX
 SG_ ABSActv : 16|1@0+ (1,0) [0|1] ""  SCU
 SG_ ABSErrDetd : 29|1@0+ (1,0) [0|1] ""  SCU
 SG_ AEBActv : 189|1@0+ (1,0) [0|1] "" Vector__XXX
 SG_ AEBAvl : 190|1@0+ (1,0) [0|1] "" Vector__XXX
 SG_ APBAplAvlBCS : 135|2@0+ (1,0) [0|2] ""  SCU
 SG_ APBErrDetd : 115|2@0+ (1,0) [0|3] ""  SCU
 SG_ APBRelAvlBCS : 133|2@0+ (1,0) [0|3] ""  SCU
 SG_ APBSts : 118|3@0+ (1,0) [0|7] ""  SCU
 SG_ APBTxtDip : 43|4@0+ (1,0) [0|15] ""  SCU
 SG_ AVHAvl : 139|1@0+ (1,0) [0|1] ""  SCU
 SG_ AVHSts : 141|2@0+ (1,0) [0|3] ""  SCU
 SG_ AWBActv : 198|1@0+ (1,0) [0|1] "" Vector__XXX
 SG_ AWBAvl : 199|1@0+ (1,0) [0|1] "" Vector__XXX
 SG_ BcsBasicFcnSigGrpChks : 87|8@0+ (1,0) [0|255] ""  SCU
 SG_ BcsBasicFcnSigGrpCntr : 91|4@0+ (1,0) [0|15] ""  SCU
 SG_ BCSBrkSysWarnText : 52|3@0+ (1,0) [0|7] ""  SCU
 SG_ BcsExtdFcnSigGrpChks : 175|8@0+ (1,0) [0|255] "" Vector__XXX
 SG_ BcsExtdFcnSigGrpCntr : 179|4@0+ (1,0) [0|15] "" Vector__XXX
 SG_ BCSFaultInfoFlag : 150|1@0+ (1,0) [0|1] "" Vector__XXX
 SG_ BCSKeepAwakeReq : 151|1@0+ (1,0) [0|1] "" Vector__XXX
 SG_ BcsSysCtrSigGrpChks : 7|8@0+ (1,0) [0|255] ""  SCU
 SG_ BcsSysCtrSigGrpCntr : 11|4@0+ (1,0) [0|15] ""  SCU
 SG_ BrkLiIllmnReq : 15|1@0+ (1,0) [0|1] ""  SCU
 SG_ BrkSysWarnLamp : 23|2@0+ (1,0) [0|3] ""  SCU
 SG_ CDPActv : 137|1@0+ (1,0) [0|1] ""  SCU
 SG_ CDPAvl : 136|1@0+ (1,0) [0|1] ""  SCU
 SG_ CSTSts : 58|2@0+ (1,0) [0|3] ""  SCU
 SG_ DrvOffTqThd : 103|15@0+ (1,0) [0|30000] "Nm"  SCU
 SG_ DSTActv : 119|1@0+ (1,0) [0|1] ""  SCU
 SG_ DSTSteerTqReq : 112|9@0- (0.1,0) [-6|6] "Nm"  SCU
 SG_ EBAActv : 188|1@0+ (1,0) [0|1] "" Vector__XXX
 SG_ EBDActv : 31|1@0+ (1,0) [0|1] ""  SCU
 SG_ EBDErrDetd : 28|1@0+ (1,0) [0|1] ""  SCU
 SG_ EmgyBrkLiReq : 27|1@0+ (1,0) [0|1] ""  SCU
 SG_ ESCErrDetd : 30|1@0+ (1,0) [0|1] ""  SCU
 SG_ ESCIntvLamp : 19|1@0+ (1,0) [0|1] ""  SCU
 SG_ ESCPataLamp : 21|2@0+ (1,0) [0|3] ""  SCU
 SG_ ESCSwitchAvl : 55|3@0+ (1,0) [0|7] ""  SCU
 SG_ EstimdSumOfVehHydBrkEachWhl : 71|15@0+ (8,-250000) [-250000|0] "N"  SCU
 SG_ HBBActive : 72|1@0+ (1,0) [0|1] ""  SCU
 SG_ HBBSts : 63|2@0+ (1,0) [0|3] ""  SCU
 SG_ HBCActv : 56|1@0+ (1,0) [0|1] ""  SCU
 SG_ HDCAvl : 61|1@0+ (1,0) [0|1] ""  SCU
 SG_ HDCCtrlSts : 60|2@0+ (1,0) [0|3] ""  SCU
 SG_ HDCUnAvlRsn : 251|3@0+ (1,0) [0|7] "" Vector__XXX
 SG_ HHCActv : 143|1@0+ (1,0) [0|1] ""  SCU
 SG_ HHCAvl : 142|1@0+ (1,0) [0|1] ""  SCU
 SG_ HRBActv : 25|1@0+ (1,0) [0|1] ""  SCU
 SG_ HRBAvl : 26|1@0+ (1,0) [0|1] ""  SCU
 SG_ HydBrkFExist : 14|1@0+ (1,0) [0|1] ""  SCU
 SG_ MstCylPCmp : 39|12@0+ (0.1,0) [0|250] "bar"  SCU
 SG_ MstCylPVld : 48|1@0+ (1,0) [0|1] ""  SCU
 SG_ SCMActv : 104|1@0+ (1,0) [0|1] ""  SCU
 SG_ SCMAvl : 138|1@0+ (1,0) [0|1] ""  SCU
 SG_ TCSActv : 17|1@0+ (1,0) [0|1] ""  SCU
 SG_ VDCActv : 18|1@0+ (1,0) [0|1] ""  SCU
 SG_ VehStandStillIndcr : 13|1@0+ (1,0) [0|1] ""  SCU
 SG_ VehStandStillIndcrVld : 12|1@0+ (1,0) [0|1] ""  SCU

BO_ 338 BCS_ChassisFusion_0x152: 24 BCS
 SG_ APAActrAvl : 163|1@0+ (1,0) [0|1] "" Vector__XXX
 SG_ APCActvVehHld : 175|1@0+ (1,0) [0|1] "" Vector__XXX
 SG_ APCDrvrBrkOvrdFlg : 174|1@0+ (1,0) [0|1] "" Vector__XXX
 SG_ APCFailrSts : 167|4@0+ (1,0) [0|15] "" Vector__XXX
 SG_ ApcFcnSigGrpChks : 151|8@0+ (1,0) [0|255] "" Vector__XXX
 SG_ ApcFcnSigGrpCntr : 155|4@0+ (1,0) [0|15] "" Vector__XXX
 SG_ APCSts : 162|3@0+ (1,0) [0|4] "" Vector__XXX
 SG_ BCSLgtCtrlPtTarTq : 39|16@0- (1,0) [-30000|30000] "Nm"  SCU
 SG_ BCSLgtCtrlPtTarTqEna : 24|1@0+ (1,0) [0|1] ""  SCU
 SG_ BcsTqCtrlSigGrpChks : 7|8@0+ (1,0) [0|255] ""  SCU
 SG_ BcsTqCtrlSigGrpCntr : 11|4@0+ (1,0) [0|15] ""  SCU
 SG_ BiasMaxFrntAxle : 119|7@0+ (1,0) [0|100] "%"  SCU
 SG_ BiasMaxReAxle : 127|7@0+ (1,0) [0|100] "%"  SCU
 SG_ CstRgnBlendSts : 135|2@0+ (1,0) [0|3] ""  SCU
 SG_ CstRgnBlendTqReqFA : 55|16@0- (1,0) [-30000|30000] "Nm"  SCU
 SG_ CstRgnBlendTqReqRA : 71|16@0- (1,0) [-30000|30000] "Nm"  SCU
 SG_ DrgTqCtrlActvFA : 112|1@0+ (1,0) [0|1] ""  SCU
 SG_ DrgTqCtrlActvRA : 120|1@0+ (1,0) [0|1] ""  SCU
 SG_ PtTqRednActvFA : 14|1@0+ (1,0) [0|1] ""  SCU
 SG_ PtTqRednActvRA : 15|1@0+ (1,0) [0|1] ""  SCU
 SG_ RPAAVPActrAvl : 173|2@0+ (1,0) [0|3] "" Vector__XXX
 SG_ TarRdcdPtTqFA : 87|16@0- (1,0) [-30000|30000] "Nm"  SCU
 SG_ TarRdcdPtTqRA : 103|16@0- (1,0) [-30000|30000] "Nm"  SCU
 SG_ TarRecuTqReq : 23|15@0+ (1,-32767) [-32767|0] "Nm"  SCU
 SG_ TarRecuTqReqSts : 13|2@0+ (1,0) [0|3] ""  SCU

BO_ 354 BCS_ChassisFusion_0x162: 32 BCS
 SG_ APBAplAvlBCSFusion : 143|2@0+ (1,0) [0|2] ""  BCP,FZCU,XCD
 SG_ APBRelAvlBCSFusion : 141|2@0+ (1,0) [0|3] ""  BCP,FZCU,XCD
 SG_ APBStsFusion : 156|3@0+ (1,0) [0|4] ""  BCP,FZCU,XCD
 SG_ BCSKeepAwakeReqBkp : 120|1@0+ (1,0) [0|1] ""  FZCU,XCD
 SG_ BrkSysAxRoadSlope : 69|6@0- (0.1,0) [-3.2|3.1] "m/s^2"  BCP,XCD
 SG_ BrkSysAxRoadSlopeVld : 73|2@0+ (1,0) [0|3] ""  BCP,XCD
 SG_ BrkSysBCSDiagActv : 76|1@0+ (1,0) [0|1] ""  BCP,XCD
 SG_ BrkSysMonBkpSigGrpChks : 47|8@0+ (1,0) [0|255] ""  BCP,XCD
 SG_ BrkSysMonBkpSigGrpCntr : 51|4@0+ (1,0) [0|15] ""  BCP,XCD
 SG_ BrkSysMotPedlPosnDrvr : 63|10@0+ (0.1,0) [0|102.2] "%"  BCP,XCD
 SG_ BrkSysShiftVol : 87|8@0+ (0.04,0) [0|10.16] "cm^3"  BCP,XCD
 SG_ BrkSysSkidDrv : 74|1@0+ (1,0) [0|1] ""  BCP,XCD
 SG_ BrkSysSkidYawRate : 75|1@0+ (1,0) [0|1] ""  BCP,XCD
 SG_ PRBCoornPrim : 167|8@0+ (1,0) [0|255] ""  BCP,FZCU,XCD
 SG_ RPBActrStPrim : 150|3@0+ (1,0) [0|7] ""  BCP,FZCU,XCD
 SG_ RPBAx : 175|16@0+ (0.0002,-5) [-5|5] "g"  BCP,FZCU,XCD
 SG_ RPBAxSt : 158|2@0+ (1,0) [0|3] ""  BCP,FZCU,XCD
 SG_ RPBIntReqPrim : 147|4@0+ (1,0) [0|15] ""  BCP,FZCU,XCD
 SG_ RPBPrkgBtnPsd : 151|1@0+ (1,0) [0|1] ""  BCP,FZCU,XCD
 SG_ RPBPrkgBtnPsdVld : 159|1@0+ (1,0) [0|1] ""  BCP,FZCU,XCD
 SG_ RpbStsIndcnBkpSigGrpChks : 135|8@0+ (1,0) [0|255] ""  BCP,FZCU,XCD
 SG_ RpbStsIndcnBkpSigGrpCntr : 139|4@0+ (1,0) [0|15] ""  BCP,FZCU,XCD
 SG_ VehSpdBkp : 23|16@0+ (0.05625,0) [0|360] "kph"  EPS,XCD
 SG_ VehSpdBkpVld : 15|1@0+ (1,0) [0|1] ""  EPS,XCD
 SG_ WhlspdBkpFcnSigGrpChks : 7|8@0+ (1,0) [0|255] ""  EPS,XCD
 SG_ WhlspdBkpFcnSigGrpCntr : 11|4@0+ (1,0) [0|15] ""  EPS,XCD

BO_ 179 BCS_ChassisFusion_0xB3: 32 BCS
 SG_ AdcFcnSigGrpChks : 223|8@0+ (1,0) [0|255] "" Vector__XXX
 SG_ AdcFcnSigGrpCntr : 227|4@0+ (1,0) [0|15] "" Vector__XXX
 SG_ BCSActrActvForADC : 231|2@0+ (1,0) [0|3] "" Vector__XXX
 SG_ BCSActrAvlStsForADC : 239|3@0+ (1,0) [0|7] "" Vector__XXX
 SG_ BCSActrAvlStsForADCL3 : 236|3@0+ (1,0) [0|7] "" Vector__XXX
 SG_ BCSActrRampOffStsForADC : 229|2@0+ (1,0) [0|3] "" Vector__XXX
 SG_ BCSActrVldForADC : 233|1@0+ (1,0) [0|1] "" Vector__XXX
 SG_ VehSpd : 87|16@0+ (0.05625,0) [0|360] "kph"  SCU,SWM
 SG_ VehSpdVld : 103|1@0+ (1,0) [0|1] ""  SCU,SWM
 SG_ WhlDirFrntLe : 101|2@0+ (1,0) [0|3] ""  SCU,SWM
 SG_ WhlDirFrntLeVld : 102|1@0+ (1,0) [0|1] ""  SCU,SWM
 SG_ WhlDirFrntRi : 97|2@0+ (1,0) [0|3] ""  SCU,SWM
 SG_ WhlDirFrntRiVld : 98|1@0+ (1,0) [0|1] ""  SCU,SWM
 SG_ WhlDirReLe : 117|2@0+ (1,0) [0|3] ""  SCU,SWM
 SG_ WhlDirReLeVld : 118|1@0+ (1,0) [0|1] ""  SCU,SWM
 SG_ WhlDirReRi : 113|2@0+ (1,0) [0|3] ""  SCU,SWM
 SG_ WhlDirReRiVld : 114|1@0+ (1,0) [0|1] ""  SCU,SWM
 SG_ WhlDstTiStampFrntLe : 159|16@0+ (1,0) [0|65535] "ms"  SCU,SWM
 SG_ WhlDstTiStampFrntRi : 175|16@0+ (1,0) [0|65535] "ms"  SCU,SWM
 SG_ WhlDstTiStampReLe : 191|16@0+ (1,0) [0|65535] "ms"  SCU,SWM
 SG_ WhlDstTiStampReRi : 207|16@0+ (1,0) [0|65535] "ms"  SCU,SWM
 SG_ WhlSpdEdgeFrntLe : 111|8@0+ (1,0) [0|255] ""  SCU,SWM
 SG_ WhlSpdEdgeFrntLeVld : 99|1@0+ (1,0) [0|1] ""  SCU,SWM
 SG_ WhlSpdEdgeFrntRi : 127|8@0+ (1,0) [0|255] ""  SCU,SWM
 SG_ WhlSpdEdgeFrntRiVld : 119|1@0+ (1,0) [0|1] ""  SCU,SWM
 SG_ WhlSpdEdgeReLe : 135|8@0+ (1,0) [0|255] ""  SCU,SWM
 SG_ WhlSpdEdgeReLeVld : 115|1@0+ (1,0) [0|1] ""  SCU,SWM
 SG_ WhlSpdEdgeReRi : 151|8@0+ (1,0) [0|255] ""  SCU,SWM
 SG_ WhlSpdEdgeReRiVld : 143|1@0+ (1,0) [0|1] ""  SCU,SWM
 SG_ WhlSpdFrntLe : 23|16@0+ (0.05625,0) [0|360] "kph"  SCU,SWM
 SG_ WhlSpdFrntLeVld : 15|1@0+ (1,0) [0|1] ""  SCU,SWM
 SG_ WhlSpdFrntRi : 39|16@0+ (0.05625,0) [0|360] "kph"  SCU,SWM
 SG_ WhlSpdFrntRiVld : 14|1@0+ (1,0) [0|1] ""  SCU,SWM
 SG_ WhlSpdReLe : 55|16@0+ (0.05625,0) [0|360] "kph"  SCU,SWM
 SG_ WhlSpdReLeVld : 13|1@0+ (1,0) [0|1] ""  SCU,SWM
 SG_ WhlSpdReRi : 71|16@0+ (0.05625,0) [0|360] "kph"  SCU,SWM
 SG_ WhlSpdReRiVld : 12|1@0+ (1,0) [0|1] ""  SCU,SWM
 SG_ WhlStsSigGrpChks : 7|8@0+ (1,0) [0|255] ""  SCU,SWM
 SG_ WhlStsSigGrpCntr : 11|4@0+ (1,0) [0|15] ""  SCU,SWM

CM_ SG_ 425 IMUCalSt "IMUCalibrationSt
IMU标定状态";
CM_ SG_ 425 LonAccr "Longititude Acceleration
纵向加速度";
CM_ SG_ 425 LonSnsrSt "Longititude Sensor State
纵向加速度有效性";
CM_ SG_ 426 LatAccr "Lateral Acceleration
横向加速度";
CM_ SG_ 426 LatAccrSt "Lateral Sensor State
横向加速度有效性";
CM_ SG_ 426 YawRate "Yaw Rate
横摆角速度";
CM_ SG_ 426 YawRateSnsrSt "Yaw Rate Sensor State
横摆角速度有效性";
CM_ SG_ 848 ACUWarnLampSts "Airbag Warning Lamp Status 
ACU故障灯信号";
CM_ SG_ 848 DrvrBucSts "Driver Buckle Status 
主驾驶安全带扣状态";
CM_ SG_ 848 PassAirbDiIndcr "Passenger airbag disable indicator
副驾安全气囊禁用状态指示";
CM_ SG_ 848 PassBucSts "Passenger Buckle Status
副驾安全带状态";
CM_ SG_ 848 SecRowLeBucSts "Second Row Left Buckle Status
第二排左安全带状态";
CM_ SG_ 848 SecRowMidBucSts "Second Row Middle Buckle Status
第二排中安全带状态";
CM_ SG_ 848 SecRowRiBucSts "Second Row Right Buckle Status
第二排右安全带状态";
CM_ SG_ 848 ThrdRowLeBucSts "Third Row Left Buckle Status 第三排左安全带状态";
CM_ SG_ 848 ThrdRowMidBucSts "Third Row Middle Buckle Status第三排中安全带状态";
CM_ SG_ 848 ThrdRowRiBucSts "Third Row Right Buckle Status 第三排右安全带状态";
CM_ SG_ 379 ADDKeepAwakeReq "请求整车电源状态";
CM_ SG_ 379 ParkGearReqEnaFrmADD "Parking system Gear request Enable";
CM_ SG_ 379 ParkGearReqFrmADD "Parking system Gear request";
CM_ SG_ 379 RPAHVOnReqFrmADD "Request HV ON";
CM_ SG_ 379 RPAPrkinRecdFrmADD "RPA Park in Record
RPA 记录上次是遥控泊入还是人为泊入";
CM_ SG_ 399 HPPAVPRecoverIndCtrlBkp "HPP AVP recovery interrupt indication Backup";
CM_ SG_ 399 HPPAVPSteerWhlAglReqValBkp "HPP AVP  Steering Wheel Angle Request Value Backup";
CM_ SG_ 399 HPPAVPSteerWhlCtrlReqStsBkp "HPP AVP Steering Wheel Control Request Status Backup";
CM_ SG_ 493 DrvAirSuspReqFrmADD "driving air suspension request";
CM_ SG_ 493 ParkAirSuspReqFrmADD "Parking Control Air Suspension Request";
CM_ SG_ 512 ADDBSDLCAStsFrmADD "BSD LCA function status";
CM_ SG_ 512 ADSAEBStsFrmADD "AEB function status";
CM_ SG_ 512 ADSAEBTarDirFrmADD "AEB目标方向显示标志";
CM_ SG_ 512 ADSAEBWarnReqFrmADD "AEB warning request";
CM_ SG_ 512 AdsAutoTurnLiCnclReqFrmADD "Adas Auto Turn Light Cancel Request";
CM_ SG_ 512 AdsAutoTurnLiSwtStsFrmADD "Adas Auto Turn Light switch status";
CM_ SG_ 512 AdsAutoTurnLiUnavlRsnFrmADD "Adas Auto Turn Light switch  unavailable reason";
CM_ SG_ 512 ADSBSDLCAAudioWarnReqFrmADD "用于表征 BSDLCA 声音报警需求";
CM_ SG_ 512 ADSBSDLCAWarnReqLeFrmADD "BSD_LCA warning request";
CM_ SG_ 512 ADSBSDLCAWarnReqRiFrmADD "BSD warning request";
CM_ SG_ 512 ADSBSDLightWarningLeReqFrmADD "智驾对左侧BSD灯的请求信号";
CM_ SG_ 512 ADSBSDLightWarningRiReqFrmADD "智驾对右侧BSD灯的请求信号";
CM_ SG_ 512 ADSDOWStsFrmADD "DOW function status";
CM_ SG_ 512 ADSDOWWarnReqFrLeFrmADD "DOW warning request - front left";
CM_ SG_ 512 ADSDOWWarnReqFrRiFrmADD "DOW warning request - front right";
CM_ SG_ 512 ADSDOWWarnReqReLeFrmADD "DOW warning request - rear left";
CM_ SG_ 512 ADSDOWWarnReqReRiFrmADD "DOW warning request - rear right";
CM_ SG_ 512 ADSELKStsFrmADD "ELK function status";
CM_ SG_ 512 ADSESSStsFrmADD "ESS function status";
CM_ SG_ 512 ADSESSWarnReqFrmADD "ESS warning request";
CM_ SG_ 512 ADSFCWReqFrmADD "FCW request";
CM_ SG_ 512 ADSFCWStsFrmADD "FCW function status";
CM_ SG_ 512 AdsIntelgntSpdSwtStsFrmADD "Adas Intelligent Speed switch status";
CM_ SG_ 512 AdsIntelgntSpdUnavlRsnFrmADD "Adas Intelligent Speed switch  unavailable reason";
CM_ SG_ 512 ADSLDPHandOffExitFrmADD "LDP脱手超时退出";
CM_ SG_ 512 ADSLDPHandOffWarningFrmADD "LDP脱手报警提示";
CM_ SG_ 512 ADSLDPStsFrmADD "LDP function status";
CM_ SG_ 512 ADSLDPWarnReqLeFrmADD "LDP warning request - left";
CM_ SG_ 512 ADSLDPWarnReqRiFrmADD "LDP warning request - right";
CM_ SG_ 512 ADSLDWStsFrmADD "LDW function status";
CM_ SG_ 512 ADSLDWWarnLeReqFrmADD "ADS LDW Warning LEFT Request";
CM_ SG_ 512 ADSLDWWarnRiReqFrmADD "ADS LDW Warning right Request";
CM_ SG_ 512 AdsLearnSwtStsFrmADD "Adas learned switch status";
CM_ SG_ 512 AdsLearnSwtUnavlRsnFrmADD "Adas learned switch unavailable reason";
CM_ SG_ 512 ADSLiReqFrmADD "ADS light request";
CM_ SG_ 512 ADSMAIInhibitReqFrmADD "MAI Inhibit Warning Request";
CM_ SG_ 512 ADSMAIStsFrmADD "MAI Function Status";
CM_ SG_ 512 ADSMAIWarnReqFrmADD "MAI Warning Request";
CM_ SG_ 512 AdsModSwtStsFrmADD "Adas mode switch status";
CM_ SG_ 512 AdsNOAOddSwtStsFrmADD "Adas-NOA odd switch status";
CM_ SG_ 512 AdsNOAOddSwtUnavlRsnFrmADD "Adas-NOA odd switch unavailable reason";
CM_ SG_ 512 ADSRCTAStsFrmADD "RCTA function status";
CM_ SG_ 512 ADSRCTAWarnReqLeFrmADD "RCTA warning request";
CM_ SG_ 512 ADSRCTAWarnReqRiFrmADD "RCTA warning request";
CM_ SG_ 512 ADSRCTBStsFrmADD "RCTB function status";
CM_ SG_ 512 ADSRCTBWarnReqLeFrmADD "RCTB warning request";
CM_ SG_ 512 ADSRCTBWarnReqRiFrmADD "RCTB warning request";
CM_ SG_ 512 ADSRCWStsFrmADD "RCW function status";
CM_ SG_ 512 ADSRCWWarnReqFrmADD "RCW warning rcw_warninguest";
CM_ SG_ 512 ADSSysErrorRmdFrmADD "智驾系统故障提示";
CM_ SG_ 512 ADSSysErrorStsFrmADD "智驾系统故障状态";
CM_ SG_ 512 ADSTakeoverRmdFrmADD "智驾紧急请求用户接管";
CM_ SG_ 512 ADSTLAStsFrmADD "TLA功能状态机信号";
CM_ SG_ 512 AdsTrfcLiCtrlSwtStsFrmADD "Adas traffic light control switch status";
CM_ SG_ 512 ADSVcCtrlArbFrmADD "Voice_Control_Arbitration_Feedback";
CM_ SG_ 512 AdsVehDetourSwtStsFrmADD "Adas vehicle detour switch status";
CM_ SG_ 512 AEBTarObjClassFrmADD "AEB target object classification";
CM_ SG_ 512 AEBTarObjTTIFrmADD "AEB  target object time to impact";
CM_ SG_ 512 AutoDrvLaneChgStsFrmADD "Autonomous Lane Change Status";
CM_ SG_ 512 AVMCamVideoChainSts "AVM视频传输链路故障状态";
CM_ SG_ 512 DrvAtmLiReqFrmADD "Atmosphere light request";
CM_ SG_ 512 DrvGearReqFrmADD "Driving Gear request";
CM_ SG_ 512 DrvGearReqVldFrmADD "智驾行车档位请求有效位
0x0 无效
0x1 有效";
CM_ SG_ 512 DrvHUDDspFrmADD "HUD display msg";
CM_ SG_ 512 DrvLaneChgStsFrmADD "Lane Change Status";
CM_ SG_ 512 DrvMdlStsFrmADD "Pilot Driver Model Status";
CM_ SG_ 512 DrvNOAExtLgtDstFrmADD "Noa Exit Longitudinal Relative Distance";
CM_ SG_ 512 DrvNOAQutLgtDstFrmADD "Noa Quit Longitudinal Relative Distance";
CM_ SG_ 512 DrvNOARemdFrmADD "NOA text msg";
CM_ SG_ 512 DrvPltSysStsFrmADD "Pilot System Status
激活状态为 PilotNormalActive PilotOverride_Long PilotOverride_Lat pilotActiveOnlylgt Pilotoverlay StandActive StandWait Takeover MRM";
CM_ SG_ 512 DrvPnt2PntExtLgtDstFrmADD "Point2Point Exit Longitudinal Relative Distance";
CM_ SG_ 512 DrvPnt2PntSysStsFrmADD "Point2Point System Status";
CM_ SG_ 512 DrvrSeldDstLvlFrmADD "Pilot Driver Selected Distance Level";
CM_ SG_ 512 DrvSysWarnFrmADD "Driving system warning request";
CM_ SG_ 512 DrvTurnLiReqFrmADD "ADS turn light request";
CM_ SG_ 512 IndcrCancelReqFrmADD "变道完成后取消长拨杆信号";
CM_ SG_ 512 LidarCleanReqFrmADD "激光雷达清洗请求";
CM_ SG_ 512 NOASysStsFrmADD "NOA System Status
NOA激活状态 NormalActive  NOAOverride_Long StandActive StandWait Overlay  Takeover MRM";
CM_ SG_ 512 NOATypFrmADD "NOA Type";
CM_ SG_ 512 TSASignQlyFrmADD "Quality/Confidence of the detected road sign";
CM_ SG_ 512 TSASignTypeFrmADD "Detected road sign type";
CM_ SG_ 512 TSASpdLimitFrmADD "TSR Traffic Sign Recognition Speed limit values";
CM_ SG_ 512 TSASpdLimitUnitFrmADD "TSR Traffic Sign Recognition  speed limit unit";
CM_ SG_ 512 UserFbReqFrmADD "user feedback request";
CM_ SG_ 513 ADSAPPUnableOpenRsnFrmADD "智驾中心APP无法打开原因提示";
CM_ SG_ 513 ADSAVPStsFrmADD "AVP State Machine Status
AVP 状态机信号";
CM_ SG_ 513 ADSHPPStsFrmADD "HPP State Machine Status
HPP 状态机信号";
CM_ SG_ 513 ADSLRRSnsrStsFrmADD "front radar working status";
CM_ SG_ 513 ADSRLSRSnsrStsFrmADD "rear left radar working status";
CM_ SG_ 513 ADSRRSRSnsrStsFrmADD "rear right radar working status";
CM_ SG_ 513 AFrCamStsFrmADD "AVM Front camera Status";
CM_ SG_ 513 ALeCamStsFrmADD "AVM Left camera Status";
CM_ SG_ 513 APAIcnDispStsFrmADD "APA Icon Display Status
APA 状态灯显示信号";
CM_ SG_ 513 APAVcFbFrmADD "APA Voice Control Feedback
APA 语控开启反馈";
CM_ SG_ 513 APAVcQuitAvlFrmADD "APA Quit Availability
APA 退出可用信号";
CM_ SG_ 513 APAVcStsFrmADD "APA Voice Control Status for Voice Contrl
APA 功能状态to 语控";
CM_ SG_ 513 AReCamStsFrmADD "AVM Rear camera Status";
CM_ SG_ 513 ARiCamStsFrmADD "AVM Right camera Status";
CM_ SG_ 513 AVMOpnReqFrmADD "AVM Open Request
AVM 开启请求";
CM_ SG_ 513 AVPIcnDispStsFrmADD "AVP Icon Display Status
AVP状态灯显示信号";
CM_ SG_ 513 CameraStsforADBFrmADD "Camera Status for ADB";
CM_ SG_ 513 CameraStsFrmADD "camera Status
摄像头状态";
CM_ SG_ 513 F120CamStsFrmADD "F120 camera Status";
CM_ SG_ 513 F120DVRStsFrmADD "DVR F120 camera channel status";
CM_ SG_ 513 F30CamStsFrmADD "F30 camera Status";
CM_ SG_ 513 F30DVRStsFrmADD "DVR F30 camera channel status";
CM_ SG_ 513 FLidarStsFrmADD "front lidar working status";
CM_ SG_ 513 FUSSStsFrmADD "front USS working status";
CM_ SG_ 513 HPPActiveSubStsFrmADD "HPP Active Sub-State Machine Status
HPP 激活子状态机信号";
CM_ SG_ 513 HPPAlrtWarnFrmADD "HPP接管提醒";
CM_ SG_ 513 HPPAVPModSts "代客泊车模式";
CM_ SG_ 513 HPPBakMapDfltParkSlotDispFrmADD "后台静默图回放 使用默认车位确认";
CM_ SG_ 513 HPPDriverOperateDialogFrmADD "HPPDriverOperateDialog
HPP驾驶员操作提醒询问类";
CM_ SG_ 513 HPPDriverOperateInd2FrmADD "HPP Driver Operation Indicator2
HPP 驾驶员操作提示 动态文字类";
CM_ SG_ 513 HPPDriverOperateIndFrmADD "HPP Driver Operation Indicator
HPP 驾驶员操作提示";
CM_ SG_ 513 HPPIcnDispStsFrmADD "HPP Icon Display Status
HPP状态灯显示信号";
CM_ SG_ 513 HPPInfotipFrmADD "HPP过程中信息提示";
CM_ SG_ 513 HPPLearnSubStsFrmADD "HPP Learning Sub-State Machine Status
HPP 学习子状态机信号";
CM_ SG_ 513 HPPLrnVcFbFrmADD "HPP Learning Voice Control Feedback
HPP 学习语控反馈";
CM_ SG_ 513 HPPPlayBackPushFrmADD "HPP路线回放推荐";
CM_ SG_ 513 HPPQuitIndFrmADD "HPP Quit Indicator
HPP 功能退出提示";
CM_ SG_ 513 HPPRecoverButtonStsFrmADD "继续寻位泊车可用性";
CM_ SG_ 513 HPPRecoverIndFrmADD "HPP Recover Indicator
HPP 回放中断提示";
CM_ SG_ 513 HPPRouteInd2FrmADD "HPP Route Management Succeed Indicator
HPP 路线管理成功类信息提示";
CM_ SG_ 513 HPPRouteIndFrmADD "HPP Route Management Indicator
HPP 路线管理提示";
CM_ SG_ 513 HPPRouteManageStsFrmADD "HPP 路线管理状态";
CM_ SG_ 513 HPPUnableToActiveIndFrmADD "HPP Unable to Active Indicator
HPP功能开启失败提示";
CM_ SG_ 513 HPPVehInParkSlotFrmADD "车辆是否处于车位内";
CM_ SG_ 513 IMUStsFrmADD "IMU working status";
CM_ SG_ 513 ISPLigtSnsrVFrmADD "ISP Light sensor value";
CM_ SG_ 513 LidarStsFrmADD "Lidar Status";
CM_ SG_ 513 ParkVicShdFrmADD "泊车语音屏蔽请求";
CM_ SG_ 513 PrkSteerWhlBtnLi "一键智驾泊车背光灯";
CM_ SG_ 513 ReCamStsFrmADD "Rear camera Status";
CM_ SG_ 513 ReDVRStsFrmADD "DVR Rear Camera channel status";
CM_ SG_ 513 RUSSStsFrmADD "rear USS working status";
CM_ SG_ 513 SLFCamStsFrmADD "Side Left Front camera Status";
CM_ SG_ 513 SLFDVRStsFrmADD "DVR Side Left Front camera channel status";
CM_ SG_ 513 SLLidarStsFrmADD "side left working status";
CM_ SG_ 513 SLRCamStsFrmADD "Side Left Rear camera Status";
CM_ SG_ 513 SLRDVRStsFrmADD "DVR Side Left Rear camera channel status";
CM_ SG_ 513 SnmDetInfoFrmADD "Sentry Detection Information";
CM_ SG_ 513 SnmDetResFrmADD "Sentry Mode Detection result";
CM_ SG_ 513 SnmF120CamDetResFrmADD "Sentry Mode F120 camera detection result";
CM_ SG_ 513 SnmReCamDetResFrmADD "Sentry Mode Rear camera detection result";
CM_ SG_ 513 SnmSLFCamDetResFrmADD "Sentry Mode Side Left Front camera detection result";
CM_ SG_ 513 SnmSLRCamDetResFrmADD "Sentry Mode Side Left Rear camera detection result";
CM_ SG_ 513 SnmSRFCamDetResFrmADD "Sentry Mode Side Right Front detection result";
CM_ SG_ 513 SnmSRRCamDetResFrmADD "Sentry Mode Side Right Rear camera detection result";
CM_ SG_ 513 SRFCamStsFrmADD "Side Right Front camera Status";
CM_ SG_ 513 SRFDVRStsFrmADD "DVR Side Right Front camera channel status";
CM_ SG_ 513 SRLidarStsFrmADD "side right working status";
CM_ SG_ 513 SRRCamStsFrmADD "Side Right Rear camera Status";
CM_ SG_ 513 SRRDVRStsFrmADD "DVR Side Rear Rear camera channel status";
CM_ SG_ 516 APAAlrtWarnFrmADD "APAAlrtWarnFrmADD
APA Alert紧急接管提示";
CM_ SG_ 516 APAButtonReqFrmADD "APA ParkIn or Parkout Button Display Request
开始泊入或开始泊出按钮显示请求";
CM_ SG_ 516 APARPAActiveSubFunFrmADD "APA RPA Activated function
APA RPA 被激活的功能";
CM_ SG_ 516 APARPADriverOperateInd2FrmADD "APA RPA Driver operating indication
APA RPA 驾驶员操作提示2";
CM_ SG_ 516 APARPADriverOperateIndFrmADD "APA RPA Driver operating indication
APA RPA 驾驶员操作提示";
CM_ SG_ 516 APARPAQuitReasonIndFrmADD "APA RPA quit reason indication
APA RPA完全退出原因提示";
CM_ SG_ 516 APARPARecoverIndFrmADD "APA RPA recovery interrupt indication
可恢复中断提示";
CM_ SG_ 516 APARPAstatusFrmADD "APA RPA status";
CM_ SG_ 516 APARPAUnableToActiveIndFrmADD "APA RPA Unable To Active indication
APA RPA无法激活原因提示";
CM_ SG_ 516 AVPCharLidCtrlFrmADD "AVP Charging Lid Control Request
AVP 充电盖控制请求";
CM_ SG_ 516 DriverlessStsFrmADD "无人功能使用状态";
CM_ SG_ 516 OutdoorPrkDrvrOperIndFrmADD "离车泊车操作提示";
CM_ SG_ 516 OutdoorPrkQuitIndFrmADD "离车泊车退出提示";
CM_ SG_ 516 OutdoorPrkRecoverIndFrmADD "离车泊车可恢复中断提示";
CM_ SG_ 516 OutdoorPrkUnableToActvIndFrmADD "离车泊车无法激活提示";
CM_ SG_ 516 ParkActiveRearSpoilerReqFrmADD "Parking Active Rear Spoiler Request
泊车电动尾翼请求";
CM_ SG_ 516 ParkAtmLiReqFrmADD "Parking system Atmosphere light Request";
CM_ SG_ 516 ParkBackMirrorUnfoldReqFrmADD "Parking system Back Mirroe Fold or Unfold Request";
CM_ SG_ 516 ParkCornrLiReqFrmADD "泊车对角灯的控制请求";
CM_ SG_ 516 ParkDoorLockReqFrmADD "Parking system Door Lock or unlock Request";
CM_ SG_ 516 ParkingPushFrmADD "泊车手机端push提示信号";
CM_ SG_ 516 ParkLoBeamReqFrmADD "Parking Low Beam Request
泊车近光灯请求";
CM_ SG_ 516 ParkMdlStsFrmADD "Parking Driver Model Status";
CM_ SG_ 516 ParkProgressSigReDistFrmADD "Parking progress single remain distance indication
泊车单步剩余距离";
CM_ SG_ 516 ParkTurnLiReqFrmADD "Parking system turn light request";
CM_ SG_ 516 ParkWindowReqFrmADD "Parking system Window Closed Request";
CM_ SG_ 516 PASBuzzerWarnMuteIndFrmADD "PAS静音提示";
CM_ SG_ 516 PRAMoveSigReDistFrmADD "RPA Move single remain distance indication遥控移车单步剩余距离";
CM_ SG_ 516 PrkgHornReqFrmADD "parking horn request";
CM_ SG_ 516 RPAAvailableFrmADD "RPA Available Signal
RPA 可用信号";
CM_ SG_ 516 RPADriverOperateIndFrmADD "RPA操作提示1";
CM_ SG_ 516 RPAOperateToastFrmADD "RPA操作提示2";
CM_ SG_ 516 RPAQuitReasonIndFrmADD "RPA退出提示";
CM_ SG_ 516 RPARecoverIndFrmADD "RPA可恢复中断提示";
CM_ SG_ 516 RPAUnableToActiveIndFrmADD "RPA无法激活提示";
CM_ SG_ 516 WeatherStsFrmADD "Weather Status";
CM_ SG_ 518 BndryLeftAng1FrmADD "Boundary1 Left Angle";
CM_ SG_ 518 BndryLeftAng2FrmADD "Boundary2 Left Angle";
CM_ SG_ 518 BndryLeftAng3FrmADD "Boundary3 Left Angle";
CM_ SG_ 518 BndryLeftAng4FrmADD "Boundary4 Left Angle";
CM_ SG_ 518 BndryLeftAng5FrmADD "Boundary5 Left Angle";
CM_ SG_ 518 BndryLeftDist1FrmADD "Boundary1 Left Distance";
CM_ SG_ 518 BndryLeftDist2FrmADD "Boundary2 Left Distance";
CM_ SG_ 518 BndryLeftDist3FrmADD "Boundary3 Left Distance";
CM_ SG_ 518 BndryLeftDist4FrmADD "Boundary4 Left Distance";
CM_ SG_ 518 BndryLeftDist5FrmADD "Boundary5 Left Distance";
CM_ SG_ 518 BndryLowerAng1FrmADD "Boundary1 Lower Angle";
CM_ SG_ 518 BndryLowerAng2FrmADD "Boundary2 Lower Angle";
CM_ SG_ 518 BndryLowerAng3FrmADD "Boundary3 Lower Angle";
CM_ SG_ 518 BndryLowerAng4FrmADD "Boundary3 Lower Angle";
CM_ SG_ 518 BndryLowerAng5FrmADD "Boundary5 Lower Angle";
CM_ SG_ 518 BndryLowerDist1FrmADD "Boundary1 Lower Distance";
CM_ SG_ 518 BndryLowerDist2FrmADD "Boundary2 Lower Distance";
CM_ SG_ 518 BndryLowerDist3FrmADD "Boundary3 Lower Distance";
CM_ SG_ 518 BndryLowerDist4FrmADD "Boundary3 Lower Distance";
CM_ SG_ 518 BndryLowerDist5FrmADD "Boundary5 Lower Distance";
CM_ SG_ 518 VehObjDist1FrmADD "Vehicle1 Object Distance";
CM_ SG_ 518 VehObjDist2FrmADD "Vehicle2 Object Distance";
CM_ SG_ 518 VehObjDist3FrmADD "Vehicle3 Object Distance";
CM_ SG_ 518 VehObjDist4FrmADD "Vehicle4 Object Distance";
CM_ SG_ 518 VehObjDist5FrmADD "Vehicle5 Object Distance";
CM_ SG_ 518 VehObjDist6FrmADD "Vehicle6 Object Distance";
CM_ SG_ 518 VehObjDist7FrmADD "Vehicle7 Object Distance";
CM_ SG_ 518 VehObjDist8FrmADD "Vehicle8 Object Distance";
CM_ SG_ 518 VehObjHorzCtrAng1FrmADD "Vehicle1 Object horizontal center angle";
CM_ SG_ 518 VehObjHorzCtrAng2FrmADD "Vehicle2 Object horizontal center angle";
CM_ SG_ 518 VehObjHorzCtrAng3FrmADD "Vehicle3 Object horizontal center angle";
CM_ SG_ 518 VehObjHorzCtrAng4FrmADD "Vehicle4 Object horizontal center angle";
CM_ SG_ 518 VehObjHorzCtrAng5FrmADD "Vehicle5 Object horizontal center angle";
CM_ SG_ 518 VehObjHorzCtrAng6FrmADD "Vehicle6 Object horizontal center angle";
CM_ SG_ 518 VehObjHorzCtrAng7FrmADD "Vehicle7 Object horizontal center angle";
CM_ SG_ 518 VehObjHorzCtrAng8FrmADD "Vehicle8 Object horizontal center angle";
CM_ SG_ 518 VehObjHorzWidthAng1FrmADD "Vehicle1 Object horizontal width angle";
CM_ SG_ 518 VehObjHorzWidthAng2FrmADD "Vehicle2 Object horizontal width angle";
CM_ SG_ 518 VehObjHorzWidthAng3FrmADD "Vehicle3 Object horizontal width angle";
CM_ SG_ 518 VehObjHorzWidthAng4FrmADD "Vehicle4 Object horizontal width angle";
CM_ SG_ 518 VehObjHorzWidthAng5FrmADD "Vehicle5 Object horizontal width angle";
CM_ SG_ 518 VehObjHorzWidthAng6FrmADD "Vehicle6 Object horizontal width angle";
CM_ SG_ 518 VehObjHorzWidthAng7FrmADD "Vehicle7 Object horizontal width angle";
CM_ SG_ 518 VehObjHorzWidthAng8FrmADD "Vehicle8 Object horizontal width angle";
CM_ SG_ 519 BndryRightAng1FrmADD "Boundary1 Right Angle";
CM_ SG_ 519 BndryRightAng2FrmADD "Boundary2 Right Angle";
CM_ SG_ 519 BndryRightAng3FrmADD "Boundary3 Right Angle";
CM_ SG_ 519 BndryRightAng4FrmADD "Boundary4 Right Angle";
CM_ SG_ 519 BndryRightAng5FrmADD "Boundary5 Right Angle";
CM_ SG_ 519 BndryRightDist1FrmADD "Boundary1 Right Distance";
CM_ SG_ 519 BndryRightDist2FrmADD "Boundary2 Right Distance";
CM_ SG_ 519 BndryRightDist3FrmADD "Boundary3 Right Distance";
CM_ SG_ 519 BndryRightDist4FrmADD "Boundary3 Right Distance";
CM_ SG_ 519 BndryRightDist5FrmADD "Boundary5 Right Distance";
CM_ SG_ 519 BndryValidity1FrmADD "Boundary1 Validity";
CM_ SG_ 519 BndryValidity2FrmADD "Boundary2 Validity";
CM_ SG_ 519 BndryValidity3FrmADD "Boundary3 Validity";
CM_ SG_ 519 BndryValidity4FrmADD "Boundary4 Validity";
CM_ SG_ 519 BndryValidity5FrmADD "Boundary5 Validity";
CM_ SG_ 519 EnvIllumFrmADD "Environment Illumination From ADD
智驾感知识别环境亮度";
CM_ SG_ 519 RoadCondDistFrmADD "Road Condition Distance From ADD
距离下一个特征工况的距离";
CM_ SG_ 519 RoadConditionFrmADD "Road Condition From ADD
图层道路颠簸工况";
CM_ SG_ 519 RoadCondLenthFrmADD "Road Condition Length From ADD
连续特征工况的长度";
CM_ SG_ 519 TooManyBndryFlagFrmADD "Too Many Boundary Flag";
CM_ SG_ 519 TooManyVehFlagFrmADD "Too Many vehice Flag";
CM_ SG_ 519 TrafSignDist1FrmADD "Traffic sign1 Object Distance";
CM_ SG_ 519 TrafSignDist2FrmADD "Traffic sign2 Object Distance";
CM_ SG_ 519 TrafSignHorzCtrAng1FrmADD "Traffic sign1 Object horizontal center angle";
CM_ SG_ 519 TrafSignHorzCtrAng2FrmADD "Traffic sign2 Object horizontal center angle";
CM_ SG_ 519 TrafSignHorzWidthAng1FrmADD "Traffic sign1 Object horizontal width angle";
CM_ SG_ 519 TrafSignHorzWidthAng2FrmADD "Traffic sign2 Object horizontal width angle";
CM_ SG_ 519 TrafSignID1FrmADD "Traffic sign1 Object ID";
CM_ SG_ 519 TrafSignID2FrmADD "Traffic sign2 Object ID";
CM_ SG_ 519 TrafSignValidity1FrmADD "Traffic sign1 Object validity";
CM_ SG_ 519 TrafSignValidity2FrmADD "Traffic sign2 Object validity";
CM_ SG_ 519 VehObjDir1FrmADD "Vehicle1 Object Direciton";
CM_ SG_ 519 VehObjDir2FrmADD "Vehicle2 Object Direciton";
CM_ SG_ 519 VehObjDir3FrmADD "Vehicle3 Object Direciton";
CM_ SG_ 519 VehObjDir4FrmADD "Vehicle4 Object Direciton";
CM_ SG_ 519 VehObjDir5FrmADD "Vehicle5 ObjectDireciton";
CM_ SG_ 519 VehObjDir6FrmADD "Vehicle6 Object Direciton";
CM_ SG_ 519 VehObjDir7FrmADD "Vehicle7 Object Direciton";
CM_ SG_ 519 VehObjDir8FrmADD "Vehicle8 Object Direciton";
CM_ SG_ 519 VehObjID1FrmADD "Vehicle1 Object ID";
CM_ SG_ 519 VehObjID2FrmADD "Vehicle2 Object ID";
CM_ SG_ 519 VehObjID3FrmADD "Vehicle3 Object ID";
CM_ SG_ 519 VehObjID4FrmADD "Vehicle4 Object ID";
CM_ SG_ 519 VehObjID5FrmADD "Vehicle5 Object ID";
CM_ SG_ 519 VehObjID6FrmADD "Vehicle6 Object ID";
CM_ SG_ 519 VehObjID7FrmADD "Vehicle7 Object ID";
CM_ SG_ 519 VehObjID8FrmADD "Vehicle8 Object ID";
CM_ SG_ 519 VehObjType1FrmADD "Vehicle1 Object type";
CM_ SG_ 519 VehObjType2FrmADD "Vehicle2 Object type";
CM_ SG_ 519 VehObjType3FrmADD "Vehicle3 Object type";
CM_ SG_ 519 VehObjType4FrmADD "Vehicle4 Object type";
CM_ SG_ 519 VehObjType5FrmADD "Vehicle5 Object type";
CM_ SG_ 519 VehObjType6FrmADD "Vehicle6 Object type";
CM_ SG_ 519 VehObjType7FrmADD "Vehicle7 Object type";
CM_ SG_ 519 VehObjType8FrmADD "Vehicle8 Object type";
CM_ SG_ 519 VehObjValidity1FrmADD "Vehicle1 Object validity";
CM_ SG_ 519 VehObjValidity2FrmADD "Vehicle2 Object validity";
CM_ SG_ 519 VehObjValidity3FrmADD "Vehicle3 Object validity";
CM_ SG_ 519 VehObjValidity4FrmADD "Vehicle4 Object validity";
CM_ SG_ 519 VehObjValidity5FrmADD "Vehicle5 Object validity";
CM_ SG_ 519 VehObjValidity6FrmADD "Vehicle6 Object validity";
CM_ SG_ 519 VehObjValidity7FrmADD "Vehicle7 Object validity";
CM_ SG_ 519 VehObjValidity8FrmADD "Vehicle8 Object validity";
CM_ SG_ 528 ADDSyncFVReq "ADD同步请求";
CM_ SG_ 661 ADSRCTBBrkReqFrmADD "ADD发出的RCTB制动请求状态";
CM_ SG_ 661 ADSRCTBTarDecelFrmADD "ADD发出的RCTB减速度请求";
CM_ SG_ 661 BmpTrk1ConfFrmADD "Bumpy Track Type conf";
CM_ SG_ 661 BmpTrk1HeiFrmADD "Bumpy Track Height";
CM_ SG_ 661 BmpTrk1TypFrmADD "Bumpy Track Type";
CM_ SG_ 661 BmpTrk2ConfFrmADD "减速带2置信度
Bumpy Track Confidence level";
CM_ SG_ 661 BmpTrk2HeiFrmADD "减速带2高度
Bumpy Track Height";
CM_ SG_ 661 BmpTrk2TypFrmADD "Bumpy Track Type
减速带类型";
CM_ SG_ 661 Road1EndPotXRiFrmADD "减速带1右侧终止点 X坐标
Road1 End PointX Right";
CM_ SG_ 661 Road1EndPotYRiFrmADD "Road1 End PointY right";
CM_ SG_ 661 Road1StrtPotXLeFrmADD "减速带1 左侧起始点 X坐标
Road1 Start PointX left";
CM_ SG_ 661 Road1StrtPotYLeFrmADD "Road1 Start PointY left";
CM_ SG_ 661 Road2EndPotXRiFrmADD "减速带2右侧终止点 X坐标
Road1 End PointX Right";
CM_ SG_ 661 Road2EndPotYRiFrmADD "Road2 End PointY right";
CM_ SG_ 661 Road2StrtPotXLeFrmADD "减速带2 左侧起始点 X坐标
Road1 Start PointX left";
CM_ SG_ 661 Road2StrtPotYLeFrmADD "Road2 Start PointY left";
CM_ SG_ 688 ADDCooltFlowReqFrmADD "ADD coolant flowrate Request";
CM_ SG_ 688 ADDFaultInfoFlag "ADD Fault Information Flag";
CM_ SG_ 688 ADDTValFrmADD "ADD Temperature Value";
CM_ SG_ 688 ADSLrnUnavlRsnFrmADD "1";
CM_ SG_ 688 ADSParkSpdSwtStsFrmADD "Adas parking speed switch status
泊车速度开关状态";
CM_ SG_ 688 ADSParkSpdSwtUnavlRsnFrmADD "Adas parking speed switch unavailable reason  泊车速度开关不可点击原因";
CM_ SG_ 688 APASwtStsFrmADD "APA Switch Status";
CM_ SG_ 688 APASwtUnavlRsnFrmADD "APA Switch Unavailable Reason
APA 开关不可点击原因反馈信号";
CM_ SG_ 688 AutoVehCustEIPSwtFrmADD "智能驾驶用户体验改进计划开关  Autonomous Vehicle Customer Experience Improvement Program Switch";
CM_ SG_ 688 AutoVehCustEIPSwtRsnFrmADD "智能驾驶用户体验改进计划开关不可用原因";
CM_ SG_ 688 AutoVehSrvAuthntStsFrmADD "智能驾驶服务授权状态
Autonomous Vehicle Service Authorization Status";
CM_ SG_ 688 AutoVehSrvAuthntStsRsnFrmADD "智能驾驶服务授权不可用原因";
CM_ SG_ 688 AvmCamTriggerModReqFrmADD "AVM环视相机帧同步切换请求";
CM_ SG_ 688 AVPSwtStsFrmADD "AVP Switch Status
AVP 泊车设置项开关";
CM_ SG_ 688 AVPSwtUnavlRsnFrmADD "AVP Switch Unavailable Reason
AVP开关不可点击原因反馈信号";
CM_ SG_ 688 HPPBckGrLearFrmADD "HPP Background learning Switch Status
HPP后台自学习设置项开关";
CM_ SG_ 688 HPPBckGrLearUnavlRsnFrmADD "HPP BackGround Learning Unavailable Reason
HPP后台自学习开关不可点原因";
CM_ SG_ 688 HPPSwtStsFrmADD "HPP Switch Status
HPP主设置项开关";
CM_ SG_ 688 HPPSwtUnavlRsnFrmADD "HPP Switch Unavailable Reason
HPP开关不可点击原因反馈信号";
CM_ SG_ 688 RPASentryQuit "RPA退出哨兵模式请求";
CM_ SG_ 693 ParkOutTarDirFrmADD "Park Out Target Direction
目标泊出方向";
CM_ SG_ 693 ParkSlotTarFrmADD "Target Park Slot
目标车位";
CM_ SG_ 693 PASBuzzerWarnMuteReqFrmADD "Mute PAS Buzzer alarm Request
静音PAS声音报警请求";
CM_ SG_ 693 PASFCBuzzerWarnFrmADD "PAS Front Center Buzzer alarm level
PAS前中区声音报警信号";
CM_ SG_ 693 PASFLBuzzerWarnFrmADD "PAS Front Left Buzzer alarm level
PAS前左区声音报警信号";
CM_ SG_ 693 PASFLDistanceFrmADD "Front Left area distance display
倒车雷达左前区距离显示";
CM_ SG_ 693 PASFLDistanceLevFrmADD "Front Left area distance  Level 
倒车雷达左前区距离显示等级";
CM_ SG_ 693 PASFMLDistanceFrmADD "Front middle Left area distance display
倒车雷达左中前区距离显示";
CM_ SG_ 693 PASFMLDistanceLevFrmADD "Front middle Left area distance Level
倒车雷达左中前区距离显示等级";
CM_ SG_ 693 PASFMRDistanceFrmADD "Front Middle Right area distance display
倒车雷达右中前区距离显示";
CM_ SG_ 693 PASFMRDistanceLevFrmADD "Front Middle Right area distance Level
倒车雷达右中前区距离显示等级";
CM_ SG_ 693 PASFRBuzzerWarnFrmADD "PAS Front Right Buzzer alarm level
PAS前右区声音报警信号";
CM_ SG_ 693 PASFRDistanceFrmADD "Front Right area distance display
倒车雷达右前区距离显示";
CM_ SG_ 693 PASFRDistanceLevFrmADD "Front Right area distance Level
倒车雷达右前区距离显示等级";
CM_ SG_ 693 PASFSLDistanceFrmADD "Front Side Left area distance display
 倒车雷达前左侧区距离显示";
CM_ SG_ 693 PASFSLDistanceLevFrmADD "Front Side Left area distance  Level 
倒车雷达前左侧区距离显示等级";
CM_ SG_ 693 PASFSRDistanceFrmADD "Front Side Right area distance display
倒车雷达前右侧区距离显示";
CM_ SG_ 693 PASFSRDistanceLevFrmADD "Front Side Right area distance  Level 
倒车雷达前右侧区距离显示等级";
CM_ SG_ 693 PASRLBuzzerWarnFrmADD "PAS Rear Left Buzzer alarm level
PAS后左区声音报警信号";
CM_ SG_ 693 PASRLDistanceFrmADD "Rear Left area distance display
倒车雷达左后区距离显示";
CM_ SG_ 693 PASRLDistanceLevFrmADD "Rear Left area distance Level
倒车雷达左后区距离显示等级";
CM_ SG_ 693 PASRMLDistanceFrmADD "Rear Middle Left area distance display
倒车雷达左中后区距离显示";
CM_ SG_ 693 PASRMLDistanceLevFrmADD "Rear Middle Left area distance Level
倒车雷达左中后区距离显示等级";
CM_ SG_ 693 PASRMRDistanceFrmADD "Rear Middle Right area distance display 
倒车雷达右中后区距离显示";
CM_ SG_ 693 PASRMRDistanceLevFrmADD "Rear Middle Right area distance Level 
倒车雷达右中后区距离显示等级";
CM_ SG_ 693 PASRRBuzzerWarnFrmADD "PAS Rear Right Buzzer alarm level
PAS后右区声音报警信号";
CM_ SG_ 693 PASRRDistanceFrmADD "Rear Right area distance display
倒车雷达右后区距离显示";
CM_ SG_ 693 PASRRDistanceLevFrmADD "Rear Right area distance Level
倒车雷达右后区距离显示等级";
CM_ SG_ 693 PASRSLDistanceFrmADD "Rear Side Left area distance display 
倒车雷达后左侧区距离显示";
CM_ SG_ 693 PASRSLDistanceLevFrmADD "Rear Side Left area distance  Level 
倒车雷达后左侧区距离显示等级";
CM_ SG_ 693 PASRSRDistanceFrmADD "Rear Side Right area distance display  
倒车雷达后右侧区距离显示";
CM_ SG_ 693 PASRSRDistanceLevFrmADD "Rear Side Right area distance  Level 
倒车雷达后右侧区距离显示等级";
CM_ SG_ 693 PASSDWFLSideDistanceFrmADD "Front Left side area distance display
左前侧边障碍物距离";
CM_ SG_ 693 PASSDWFLSideDistanceLevFrmADD "Front Left side area distance Level
左前侧边障碍物距离显示等级";
CM_ SG_ 693 PASSDWFMLSideDistanceFrmADD "Front Middle Left side area distance display
左中前障碍物距离";
CM_ SG_ 693 PASSDWFMLSideDistanceLevFrmADD "Front Middle Left side area distance Level
左中前障碍物距离显示等级";
CM_ SG_ 693 PASSDWFMRSideDistanceFrmADD "Front Middle Right side area distance display
右中前障碍物距离";
CM_ SG_ 693 PASSDWFMRSideDistanceLevFrmADD "Front Middle Right side area distance Level
右中前障碍物距离显示等级";
CM_ SG_ 693 PASSDWFRSideDistanceFrmADD "Front Right side area distance display
右前侧边障碍物距离";
CM_ SG_ 693 PASSDWFRSideDistanceLevFrmADD "Front Right side area distance Level
右前侧边障碍物距离显示等级";
CM_ SG_ 693 PASSDWRLSideDistanceFrmADD "Rear Left side area distance display
左后侧边障碍物距离";
CM_ SG_ 693 PASSDWRLSideDistanceLevFrmADD "Rear Left side area distance Level
左后侧边障碍物距离显示等级";
CM_ SG_ 693 PASSDWRMLSideDistanceFrmADD "Rear Middle Left side area distance display
左中后障碍物距离";
CM_ SG_ 693 PASSDWRMLSideDistanceLevFrmADD "Rear Middle Left side area distance display
左中后障碍物距离显示等级";
CM_ SG_ 693 PASSDWRMRSideDistanceFrmADD "Rear Middle Right side area distance display
右中后障碍物距离";
CM_ SG_ 693 PASSDWRMRSideDistanceLevFrmADD "Rear Middle Right side area distance Level
右中后障碍物距离显示等级";
CM_ SG_ 693 PASSDWRRSideDistanceFrmADD "Rear Right side area distance display
右后侧边障碍物距离";
CM_ SG_ 693 PASSDWRRSideDistanceLevFrmADD "Rear Right side area distance Level
右后侧边障碍物距离显示等级";
CM_ SG_ 775 ParkProgressSigLFPosXFrmADD "Parking Progress Left Front Position X
预期单步泊车位置左前角点横坐标";
CM_ SG_ 775 ParkProgressSigLFPosYFrmADD "Parking Progress Left Front Position Y
预期单步泊车位置左前角点纵坐标";
CM_ SG_ 775 ParkProgressSigLRPosXFrmADD "Parking Progress Left Rear Position X
预期单步泊车位置左后角点横坐标";
CM_ SG_ 775 ParkProgressSigLRPosYFrmADD "Parking Progress Left Rear Position Y
预期单步泊车位置左后角点纵坐标";
CM_ SG_ 775 ParkProgressSigRFPosXFrmADD "Parking Progress Right Front Position X
预期单步泊车位置右前角点横坐标";
CM_ SG_ 775 ParkProgressSigRFPosYFrmADD "Parking Progress Right Front Position Y
预期单步泊车位置右前角点纵坐标";
CM_ SG_ 775 ParkProgressSigRRPosXFrmADD "Parking Progress Right Rear Position X
预期单步泊车位置右后角点横坐标";
CM_ SG_ 775 ParkProgressSigRRPosYFrmADD "Parking Progress Right Rear Position Y
预期单步泊车位置右后角点纵坐标";
CM_ SG_ 775 PASSubFunAvaiFrmADD "PAS Subsystem Function Available 
PAS子系统状态";
CM_ SG_ 775 PASWorkingModeFrmADD "PAS Working mode of reversing radar
倒车雷达的工作模式";
CM_ SG_ 873 LowPwrReqFrLdrFrmADD "ADD发送的管理激光雷达供电的请求信号";
CM_ SG_ 873 LowPwrReqFrRdrFrmADD "ADD发送的管理毫米波雷达供电的请求信号";
CM_ SG_ 238 ADD2BLEMForRPA00 "RPA路由功能";
CM_ SG_ 238 ADD2BLEMForRPA01 "RPA路由功能";
CM_ SG_ 238 ADD2BLEMForRPA02 "RPA路由功能";
CM_ SG_ 238 ADD2BLEMForRPA03 "RPA路由功能";
CM_ SG_ 239 XAccelStaFrmADD "IMUx轴加速度状态位 0正常 1功能安全异常 2超量程 3无效数值";
CM_ SG_ 239 XAccelValFrmADD "IMUx轴加速度，m/s^2
[-10g,10g], g:9.81";
CM_ SG_ 239 XAngRateStaFrmADD "IMUx轴角速度状态位 0正常 1功能安全异常 2超量程 3无效数值";
CM_ SG_ 239 XAngRateValFrmADD "'IMUx轴角速率，rad/s
[-500°/s，500°/s],pi:3.1415926'
";
CM_ SG_ 239 YAccelStaFrmADD "IMUy轴加速度状态位 0正常 1功能安全异常 2超量程 3无效数值";
CM_ SG_ 239 YAccelValFrmADD "IMUy轴加速度 m s^2
  10g 10g  g 9.81";
CM_ SG_ 239 YAngRateStaFrmADD "IMUy轴角速度状态位 0正常 1功能安全异常 2超量程 3无效数值";
CM_ SG_ 239 YAngRateValFrmADD "IMUy轴角速率 rad s
  500 s 500 s  pi 3.1415926";
CM_ SG_ 239 ZAccelStaFrmADD "IMUz轴加速度状态位 0正常 1功能安全异常 2超量程 3无效数值";
CM_ SG_ 239 ZAccelValFrmADD "IMUz轴加速度 m s^2
  10g 10g  g 9.81";
CM_ SG_ 239 ZAngRateStaFrmADD "IMUz轴角速度状态位 0正常 1功能安全异常 2超量程 3无效数值";
CM_ SG_ 239 ZAngRateValFrmADD "IMUz轴角速率 rad s
  500 s 500 s  pi 3.1415926";
CM_ SG_ 1331 ADDChassisBkpActiveWakeup "Active Wakeup Bit";
CM_ SG_ 1331 ADDChassisBkpNodeAddress "Node source address";
CM_ SG_ 1331 ADDChassisBkpRepeatMsgReq "Repeat Message Request Bit";
CM_ SG_ 1331 ADDChassisBkpRepeatMsgSt "Repeat Message State indication";
CM_ SG_ 1326 ADDChassisBkpActiveWakeup1 "Active Wakeup Bit";
CM_ SG_ 1326 ADDChassisBkpNodeAddress1 "Node source address";
CM_ SG_ 1326 ADDChassisBkpRepeatMsgReq1 "Repeat Message Request Bit";
CM_ SG_ 1326 ADDChassisBkpRepeatMsgSt1 "Repeat Message State indication";
CM_ SG_ 336 ABAActv "ABA active";
CM_ SG_ 336 ABAAvl "ABA available";
CM_ SG_ 336 APBAplAvlBCP "APB Apply Avalible from BCP
BCP侧卡钳是否可以夹紧";
CM_ SG_ 336 APBRelAvlBCP "APB Release Avalible from BCP
BCP侧卡钳是否可以释放";
CM_ SG_ 336 APBStsBkp "BCP&BCS APB Status";
CM_ SG_ 336 BCPBrkLiIllmnReq "Request to illuminate brake light from BCP";
CM_ SG_ 336 BCPBrkSysWarnText "BCP Brake System Warning Text";
CM_ SG_ 336 BCPFaultInfoFlag "BCP Fault Information Flag";
CM_ SG_ 336 BCPKeepAwakeReq "BCP Keep Awake Request";
CM_ SG_ 336 BCPMstCylP "PressureintheBCPmastercylinder";
CM_ SG_ 336 BCPMstCylPVld "QualifierforBCPmastercyclinder'spressuresignal";
CM_ SG_ 336 BCPSimulatorP "Pressure in the BCP Plunger";
CM_ SG_ 336 BCPSimulatorPVld "Qualifier for BCP Plunger's pressure signal";
CM_ SG_ 336 BCPSysSts "BCP System Status";
CM_ SG_ 336 BrkFldWarn "Brake Fluid Warning";
CM_ SG_ 336 BrkFldWarnVld "Qualifier for Brake Fluid Warning Signal";
CM_ SG_ 336 BrkPedlAppld "Indicates whether the driver operates the
 brake pedal. Only active when the driver brakes";
CM_ SG_ 336 BrkPedlAppldVld "Qualifier for brake pedal applied signal";
CM_ SG_ 336 BrkPedlPerct "Brake Pedal Percentage";
CM_ SG_ 336 BrkPedlPerctVld "Qualifier for Brake Pedal Percentage signal";
CM_ SG_ 336 HBAActv "HBA active";
CM_ SG_ 336 HBAAvl "HBA available";
CM_ SG_ 336 HBBActv "HBB active";
CM_ SG_ 336 InpRodStk "Input Rod Stroke";
CM_ SG_ 336 InpRodStkVld "Qualifier for Input Rod Stroke signal";
CM_ SG_ 340 ActCirNoPressureQ "Indicate whether the Pressure can be calculated";
CM_ SG_ 340 BCPBrkSysActCircNoP "BCP Information about ventingandapply";
CM_ SG_ 340 BCPBrkSysFTarDrvr "Target brake force from driver";
CM_ SG_ 340 BCPBrkSysFTarDrvrVld "Qualifier for Target brake force from driver signal";
CM_ SG_ 340 BrkSysActCircNoP "BCP Information about ventingandapply";
CM_ SG_ 340 BrkSysBCPDiagActv "BCP is in extended Diag Session";
CM_ SG_ 340 BrkSysCmptIdx "BCP is sending anstatic number which must
fittothesamenumbermonitoredinBCPtoensurethe
compatibilityofthetwoECU";
CM_ SG_ 340 BrkSysHBCReq "Enumeration for telling BCS which support 
is necessary";
CM_ SG_ 340 BrkSysPRnt "BCP Runouit Pressure";
CM_ SG_ 340 BrkSysPRntVld "Qualifier for BCP_Runouit Pressure signal";
CM_ SG_ 340 InpRodStkBkp "Input Rod Stroke Backup";
CM_ SG_ 340 InpRodStkBkpVld "Qualifier for Input Rod Stroke backup signal";
CM_ SG_ 340 RPBActrStSec "CurrentstateofAPBactuatorconnectedtoECU";
CM_ SG_ 340 RPBRPBCoornSec "StatusofParkBrakeinSecondarySystem.
bit position 0 - HostAvailabilityFull
bit position 1 - HostAvailabilityRelOnly
bit position 2 - DiagnosisModeActive
bit position 3 - CommunicationAvailable";
CM_ SG_ 344 BCPKeepAwakeReqBkp "BCP Keep Awake Request Backup";
CM_ SG_ 487 BCPDrvBrakeActType "Indicate if the BCP pressure control is dominated by driver";
CM_ SG_ 487 BCPRecuStatusAct "Qualifier for pressure reduction potential signal";
CM_ SG_ 487 BrkSysAPBBkp2MainSafeLimCom2 "APB Backup to main safe limit";
CM_ SG_ 487 BrkSysAPBParkBrkReqBkp2MainCom2 "APB Parking Brake Request Backup to Main";
CM_ SG_ 487 BrkSysAPCBkp2MainStCom2 "Parking function status from backup controller to main";
CM_ SG_ 487 BrkSysBCPLdmBrkActActr "IndicatetheactualLDMactuator";
CM_ SG_ 487 BrkSysBCPLdmBrkActAxle "User earor front genetor to execute LDMforcerequest";
CM_ SG_ 487 BrkSysBCPLdmBrkActGenr "If generator isused for LDM to decelerate";
CM_ SG_ 487 BrkSysBCPLdmBrkActTyp "LDM Brake Forcetype";
CM_ SG_ 487 BrkSysBCPLdmSysModReq "System Mode Request from BCP";
CM_ SG_ 487 BrkSysBrkPedlAppld "Indicates whether the driver operates the
brakepedal.Only active when the driver brakes";
CM_ SG_ 487 BrkSysBrkPedlAppldVld "Qualifier for brake system brake pedal applied signal";
CM_ SG_ 487 BrkSysEnaActvCtrlByDrvr "Indicate if the BCP pressure control is dominated by driver";
CM_ SG_ 487 BrkSysFTarDrvr "Target brake force from driver";
CM_ SG_ 487 BrkSysFTarDrvrVld "Qualifier for Target brake force from driver signal";
CM_ SG_ 487 BrkSysLdmFTarBrkBCP "Fx request out of BCP LDM functions";
CM_ SG_ 487 BrkSysLdmFTarBrkBCPVld "Qualifier for Fxrequest out of BCP LDM functions signal";
CM_ SG_ 487 BrkSysLdmFTarMaxPt "Allowed Max PT force from BCP LDM";
CM_ SG_ 487 BrkSysLdmFTarMinPt "Allowed Min PT force from BCP LDM";
CM_ SG_ 487 BrkSysLdmGlbStsAct "LDM function status arbitration";
CM_ SG_ 487 BrkSysParkBrkReq "BCP request APB";
CM_ SG_ 487 BrkSysPRednPotnl "Indicates the pressure reduction potential from BCP to BCS  to limit the max CRB brakeregen.";
CM_ SG_ 487 BrkSysPRednPotnlVld "Qualifier for pressure reduction potential signal";
CM_ SG_ 487 BrkSysWarnLampReq "Indicatethewarninglampinfothatshouldbeset";
CM_ SG_ 487 FxTargetDriverMinFrict "This signal shall provide the minimal friction brake force request from DBR";
CM_ SG_ 487 RecuSuppressEna "CRB Relevant Signal";
CM_ SG_ 487 RPBHydPSpprtChks "E2E Checksum for 0xB7 at byte9 to byte10";
CM_ SG_ 487 RPBHydPSpprtCntr "E2E Counter for 0xB7 at byte9 to byte10";
CM_ SG_ 487 RPBHydPSpprtP "Signalaccording to VDA305 100Pbc Out Hps Pressure";
CM_ SG_ 487 RPBHydPSpprtReq "Signal according to VDA305 100Pbc Out Hps Request";
CM_ SG_ 1318 BCPChassisBkpActiveWakeup "Active Wakeup Bit";
CM_ SG_ 1318 BCPChassisBkpNodeAddress "Node source address";
CM_ SG_ 1318 BCPChassisBkpRepeatMsgReq "Repeat Message Request Bit";
CM_ SG_ 1318 BCPChassisBkpRepeatMsgSt "Repeat Message State indication";
CM_ SG_ 337 ABPActv "ABP active";
CM_ SG_ 337 ABPAvl "ABP available";
CM_ SG_ 337 ABSActv "ABS Control Active";
CM_ SG_ 337 ABSErrDetd "ABS error detected";
CM_ SG_ 337 AEBActv "AEB active";
CM_ SG_ 337 AEBAvl "AEB available";
CM_ SG_ 337 APBAplAvlBCS "APB Apply Avalible from BCS
BCS侧卡钳是否可以夹紧";
CM_ SG_ 337 APBErrDetd "APB Error Status";
CM_ SG_ 337 APBRelAvlBCS "APB Release avalialbe from BCS
BCS侧卡钳是否可以释放";
CM_ SG_ 337 APBSts "APB Status";
CM_ SG_ 337 APBTxtDip "APB Text Display";
CM_ SG_ 337 AVHAvl "AVH available";
CM_ SG_ 337 AVHSts "AVH function status";
CM_ SG_ 337 AWBActv "AWB active";
CM_ SG_ 337 AWBAvl "AWB available";
CM_ SG_ 337 BCSBrkSysWarnText "BCS Brake System Warning Text";
CM_ SG_ 337 BCSFaultInfoFlag "BCS Fault Information Flag";
CM_ SG_ 337 BCSKeepAwakeReq "BCS Keep Awake Request";
CM_ SG_ 337 BrkLiIllmnReq "Request to illuminate brake light";
CM_ SG_ 337 BrkSysWarnLamp "Brake System Warning Lamp";
CM_ SG_ 337 CDPActv "CDP active";
CM_ SG_ 337 CDPAvl "CDP available";
CM_ SG_ 337 CSTSts "CST function status";
CM_ SG_ 337 DrvOffTqThd "Drive off torque threshold";
CM_ SG_ 337 DSTActv "DST active";
CM_ SG_ 337 DSTSteerTqReq "Steering wheel torque requested from DST";
CM_ SG_ 337 EBAActv "EBA active";
CM_ SG_ 337 EBDActv "EBD Control Active";
CM_ SG_ 337 EBDErrDetd "EBD error detected";
CM_ SG_ 337 EmgyBrkLiReq "Emergency brake light request";
CM_ SG_ 337 ESCErrDetd "ESC error detected";
CM_ SG_ 337 ESCIntvLamp "ESC Intervention Lamp";
CM_ SG_ 337 ESCPataLamp "ESC diable status";
CM_ SG_ 337 ESCSwitchAvl "ESC Switch availability
ESC开关可用状态";
CM_ SG_ 337 EstimdSumOfVehHydBrkEachWhl "Estimated sum of vehicle hydraulic brake force acting on each wheel";
CM_ SG_ 337 HBBActive "BCS HBB Active";
CM_ SG_ 337 HBBSts "HBB function status";
CM_ SG_ 337 HBCActv "HBC active";
CM_ SG_ 337 HDCAvl "HDC function available";
CM_ SG_ 337 HDCCtrlSts "HDC function control status";
CM_ SG_ 337 HDCUnAvlRsn "HDC function available";
CM_ SG_ 337 HHCActv "HHC active";
CM_ SG_ 337 HHCAvl "HHC available";
CM_ SG_ 337 HRBActv "HRB available";
CM_ SG_ 337 HRBAvl "HRB active";
CM_ SG_ 337 HydBrkFExist "Hydraulic brake force exsit";
CM_ SG_ 337 MstCylPCmp "Pressure in the master cylinder  offset is included .";
CM_ SG_ 337 MstCylPVld "Qualifier for the master cylinder pressure signal";
CM_ SG_ 337 SCMActv "SCM active";
CM_ SG_ 337 SCMAvl "SCM Available";
CM_ SG_ 337 TCSActv "TCS Controller Active";
CM_ SG_ 337 VDCActv "VDC Controller Active";
CM_ SG_ 337 VehStandStillIndcr "Indicate whether the vehicle is standstill or not";
CM_ SG_ 337 VehStandStillIndcrVld "Qualifier for vehicle standstill indicate signal";
CM_ SG_ 338 APAActrAvl "Flag indicate APA availability for longitudinal control";
CM_ SG_ 338 APCActvVehHld "Flag indicate that vehicle is activly hold by longitudinal actuator controller";
CM_ SG_ 338 APCDrvrBrkOvrdFlg "Indicate driver brakes more than the system.";
CM_ SG_ 338 APCFailrSts "detailed information why this APC maneuver failed";
CM_ SG_ 338 APCSts "Longitudinal controller status";
CM_ SG_ 338 BCSLgtCtrlPtTarTq "BCS longitudinal powertrain target torque";
CM_ SG_ 338 BCSLgtCtrlPtTarTqEna "BCS longitudinal powertrain torque request";
CM_ SG_ 338 BiasMaxFrntAxle "The maxium percentage of Target Recuperation Torque executed on front axle";
CM_ SG_ 338 BiasMaxReAxle "The maxium percentage of Target Recuperation Torque executed on rear axle";
CM_ SG_ 338 CstRgnBlendSts "Coast Regen Blending Status";
CM_ SG_ 338 CstRgnBlendTqReqFA "Coast Regen Blending Torque Request FA";
CM_ SG_ 338 CstRgnBlendTqReqRA "Coast Regen Blending Torque Request FA";
CM_ SG_ 338 DrgTqCtrlActvFA "Drag torque control active on front axle";
CM_ SG_ 338 DrgTqCtrlActvRA "Drag torque control active on rear axle";
CM_ SG_ 338 PtTqRednActvFA "Powertrain torque reduction active FA";
CM_ SG_ 338 PtTqRednActvRA "Powertrain torque reduction active RA";
CM_ SG_ 338 RPAAVPActrAvl "Flag indicate RPA  AVP availability for longitudinal control";
CM_ SG_ 338 TarRdcdPtTqFA "Target reduced powertrain torque FA";
CM_ SG_ 338 TarRdcdPtTqRA "Target reduced powertrain torque RA";
CM_ SG_ 338 TarRecuTqReq "Target Recuperation Torque Request to Generator";
CM_ SG_ 338 TarRecuTqReqSts "Status of Target Recuperation torque of Generator";
CM_ SG_ 354 BCSKeepAwakeReqBkp "BCS Keep Awake Request Backup";
CM_ SG_ 354 BrkSysAxRoadSlope "Road Slope used in brake system";
CM_ SG_ 354 BrkSysAxRoadSlopeVld "Qualifier for Road Slope";
CM_ SG_ 354 BrkSysBCSDiagActv "BCS is in extended Diag Session";
CM_ SG_ 354 BrkSysMotPedlPosnDrvr "Accelerator pedal position requested by driver";
CM_ SG_ 354 BrkSysShiftVol "Hydraulic volume is shifted for
 enabling correct plunger rest position";
CM_ SG_ 354 BrkSysSkidDrv "Vehicle is drifting";
CM_ SG_ 354 BrkSysSkidYawRate "Recognices the vehicle is skidding out
 of standstill";
CM_ SG_ 354 PRBCoornPrim "Status of Park Brake in Primary System.
bit position 0: HostAvailabilityFull
bit position 1: HostAvailabilityRelOnly
bit position 2: PrimarySystemAvailable 
bit position 3: ApplyFunctionalitiesAvailable
bit position 4: DriveAwayIntention(VDA305_100)
bit position 5: RollerTestBench(VDA305_100)
bit position 6: DiagnosisModeActive
bit position 7: TargetStatePMcForAbsMeasured";
CM_ SG_ 354 RPBActrStPrim "Current state of APB actuator connected to ECU";
CM_ SG_ 354 RPBAx "Longititude Acceleration
纵向加速度";
CM_ SG_ 354 RPBAxSt "Longititude Sensor State
纵向加速度有效性";
CM_ SG_ 354 RPBIntReqPrim "Park Brake actuation request from Primary to Secondary System";
CM_ SG_ 354 RPBPrkgBtnPsd "P button pressed";
CM_ SG_ 354 RPBPrkgBtnPsdVld "P button pressed valid";
CM_ SG_ 354 VehSpdBkp "Vehiclespeedbackup";
CM_ SG_ 354 VehSpdBkpVld "Qualifierforvehiclespeedsignalbackup";
CM_ SG_ 179 BCSActrActvForADC "BCS actuator active for ADC";
CM_ SG_ 179 BCSActrAvlStsForADC "BCS actuator available status for ADC";
CM_ SG_ 179 BCSActrAvlStsForADCL3 "BCS available status for ADC L3";
CM_ SG_ 179 BCSActrRampOffStsForADC "BCS actuator ramp off status for ADC";
CM_ SG_ 179 BCSActrVldForADC "BCS actuator valid for ADC";
CM_ SG_ 179 VehSpd "Vehicle speed";
CM_ SG_ 179 VehSpdVld "Qualifier for vehicle speed signal";
CM_ SG_ 179 WhlDirFrntLe "Wheel moving direction front left";
CM_ SG_ 179 WhlDirFrntLeVld "Qualifier for wheel moving direction front left";
CM_ SG_ 179 WhlDirFrntRi "Wheel moving direction front right";
CM_ SG_ 179 WhlDirFrntRiVld "Qualifier for wheel moving direction front right";
CM_ SG_ 179 WhlDirReLe "Wheel moving direction rear left";
CM_ SG_ 179 WhlDirReLeVld "Qualifier for wheel moving direction rear left";
CM_ SG_ 179 WhlDirReRi "Wheel moving direction rear right";
CM_ SG_ 179 WhlDirReRiVld "Qualifier for wheel moving direction rear right";
CM_ SG_ 179 WhlDstTiStampFrntLe "Wheel distance time stamp for front left";
CM_ SG_ 179 WhlDstTiStampFrntRi "Wheel distance time stamp for front right";
CM_ SG_ 179 WhlDstTiStampReLe "Wheel distance time stamp for rear left";
CM_ SG_ 179 WhlDstTiStampReRi "Wheel distance time stamp for rear left";
CM_ SG_ 179 WhlSpdEdgeFrntLe "Wheel speed Edges front left";
CM_ SG_ 179 WhlSpdEdgeFrntLeVld "Qualifier for wheel speed Edges front left";
CM_ SG_ 179 WhlSpdEdgeFrntRi "Wheel speed Edges front right";
CM_ SG_ 179 WhlSpdEdgeFrntRiVld "Qualifier for wheel speed Edges front right";
CM_ SG_ 179 WhlSpdEdgeReLe "Wheel speed Edges rear left";
CM_ SG_ 179 WhlSpdEdgeReLeVld "Qualifier for wheel speed Edges rear left";
CM_ SG_ 179 WhlSpdEdgeReRi "Wheel speed Edges rear right";
CM_ SG_ 179 WhlSpdEdgeReRiVld "Qualifier for wheel speed Edges rear right";
CM_ SG_ 179 WhlSpdFrntLe "Wheel speed front left";
CM_ SG_ 179 WhlSpdFrntLeVld "Status of wheel speed front left";
CM_ SG_ 179 WhlSpdFrntRi "Wheel speed front right";
CM_ SG_ 179 WhlSpdFrntRiVld "Status of wheel speed front right";
CM_ SG_ 179 WhlSpdReLe "Wheel speed rear left";
CM_ SG_ 179 WhlSpdReLeVld "Status of wheel speed rear left";
CM_ SG_ 179 WhlSpdReRi "Wheel speed rear right";
CM_ SG_ 179 WhlSpdReRiVld "Status of wheel speed rear right";
BA_DEF_  "BaudRateCANFD" FLOAT 1000 10000000;
BA_DEF_  "Baudrate" FLOAT 1000 1000000;
BA_DEF_  "BusType" STRING ;
BA_DEF_  "DBName" STRING ;
BA_DEF_  "ProtocolType" STRING ;
BA_DEF_ BU_  "NmAsrNode" ENUM  "No","Yes";
BA_DEF_ BO_  "CANFD_BRS" ENUM  "0","1";
BA_DEF_ BO_  "GenMsgCycleTime" FLOAT 0 300000;
BA_DEF_ BO_  "GenMsgCycleTimeFast" FLOAT 0 300000;
BA_DEF_ BO_  "GenMsgDelayTime" FLOAT 0 300000;
BA_DEF_ BO_  "GenMsgNrOfRepetition" INT 0 100000;
BA_DEF_ BO_  "GenMsgSendType" ENUM  "cyclic","spontaneous","cyclicIfActive","spontaneousWithDelay","cyclicAndSpontaneous","cyclicAndSpontaneousWithDelay","IfActive","NoMsgSendType";
BA_DEF_ BO_  "GenMsgStartDelayTime" FLOAT 0 300000;
BA_DEF_ BO_  "VFrameFormat" ENUM  "StandardCAN","ExtendedCAN","reserved","J1939PG","reserved","reserved","reserved","reserved","reserved","reserved","reserved","reserved","reserved","reserved","StandardCAN_FD","ExtendedCAN_FD";
BA_DEF_ SG_  "GenSigSendType" ENUM  "Cyclic","OnWrite","OnWriteWithRepetition","OnChange","OnChangeWithRepetition","IfActive","IfActiveWithRepetition","NoSigSendType";
BA_DEF_ SG_  "GenSigStartValue" FLOAT -1.79769313486232E+308 1.84467440737096E+019;
BA_DEF_ SG_  "SystemSignalLongSymbol" STRING ;
BA_DEF_DEF_  "BaudRateCANFD" 1000;
BA_DEF_DEF_  "Baudrate" 1000;
BA_DEF_DEF_  "BusType" "";
BA_DEF_DEF_  "DBName" "";
BA_DEF_DEF_  "ProtocolType" "";
BA_DEF_DEF_  "NmAsrNode" "No";
BA_DEF_DEF_  "CANFD_BRS" "1";
BA_DEF_DEF_  "GenMsgCycleTime" 0;
BA_DEF_DEF_  "GenMsgCycleTimeFast" 0;
BA_DEF_DEF_  "GenMsgDelayTime" 0;
BA_DEF_DEF_  "GenMsgNrOfRepetition" 0;
BA_DEF_DEF_  "GenMsgSendType" "";
BA_DEF_DEF_  "GenMsgStartDelayTime" 0;
BA_DEF_DEF_  "VFrameFormat" "J1939PG";
BA_DEF_DEF_  "GenSigSendType" "Cyclic";
BA_DEF_DEF_  "GenSigStartValue" 0;
BA_DEF_DEF_  "SystemSignalLongSymbol" "";
BA_ "BaudRateCANFD" 2000000;
BA_ "Baudrate" 500000;
BA_ "BusType" "CAN FD";
BA_ "ProtocolType" "CAN";
BA_ "DBName" "ChassisFusionCANFD";
BA_ "NmAsrNode" BU_ ADD 1;
BA_ "NmAsrNode" BU_ BCP 1;
BA_ "NmAsrNode" BU_ BCS 1;
BA_ "NmAsrNode" BU_ EPS 1;
BA_ "NmAsrNode" BU_ FZCU 1;
BA_ "NmAsrNode" BU_ SCU 1;
BA_ "NmAsrNode" BU_ SWM 1;
BA_ "NmAsrNode" BU_ VECU 1;
BA_ "NmAsrNode" BU_ XCD 1;
BA_ "GenMsgCycleTime" BO_ 425 20;
BA_ "GenMsgSendType" BO_ 425 0;
BA_ "VFrameFormat" BO_ 425 14;
BA_ "GenMsgCycleTime" BO_ 426 20;
BA_ "GenMsgSendType" BO_ 426 0;
BA_ "VFrameFormat" BO_ 426 14;
BA_ "GenMsgCycleTime" BO_ 848 200;
BA_ "GenMsgSendType" BO_ 848 0;
BA_ "VFrameFormat" BO_ 848 14;
BA_ "GenMsgCycleTime" BO_ 379 20;
BA_ "GenMsgSendType" BO_ 379 0;
BA_ "VFrameFormat" BO_ 379 14;
BA_ "GenMsgCycleTime" BO_ 399 20;
BA_ "GenMsgSendType" BO_ 399 0;
BA_ "VFrameFormat" BO_ 399 14;
BA_ "GenMsgCycleTime" BO_ 493 50;
BA_ "GenMsgSendType" BO_ 493 0;
BA_ "VFrameFormat" BO_ 493 14;
BA_ "GenMsgCycleTime" BO_ 512 50;
BA_ "GenMsgSendType" BO_ 512 0;
BA_ "VFrameFormat" BO_ 512 14;
BA_ "GenMsgCycleTime" BO_ 513 50;
BA_ "GenMsgSendType" BO_ 513 0;
BA_ "VFrameFormat" BO_ 513 14;
BA_ "GenMsgCycleTime" BO_ 516 50;
BA_ "GenMsgSendType" BO_ 516 0;
BA_ "VFrameFormat" BO_ 516 14;
BA_ "GenMsgCycleTime" BO_ 518 50;
BA_ "GenMsgSendType" BO_ 518 0;
BA_ "VFrameFormat" BO_ 518 14;
BA_ "GenMsgCycleTime" BO_ 519 50;
BA_ "GenMsgSendType" BO_ 519 0;
BA_ "VFrameFormat" BO_ 519 14;
BA_ "GenMsgDelayTime" BO_ 528 10;
BA_ "GenMsgSendType" BO_ 528 1;
BA_ "VFrameFormat" BO_ 528 14;
BA_ "GenMsgCycleTime" BO_ 661 20;
BA_ "GenMsgSendType" BO_ 661 0;
BA_ "VFrameFormat" BO_ 661 14;
BA_ "GenMsgCycleTime" BO_ 688 100;
BA_ "GenMsgSendType" BO_ 688 0;
BA_ "VFrameFormat" BO_ 688 14;
BA_ "GenMsgCycleTime" BO_ 693 100;
BA_ "GenMsgSendType" BO_ 693 0;
BA_ "VFrameFormat" BO_ 693 14;
BA_ "GenMsgCycleTime" BO_ 775 100;
BA_ "GenMsgSendType" BO_ 775 0;
BA_ "VFrameFormat" BO_ 775 14;
BA_ "GenMsgCycleTime" BO_ 873 1000;
BA_ "GenMsgCycleTimeFast" BO_ 873 40;
BA_ "GenMsgNrOfRepetition" BO_ 873 3;
BA_ "GenMsgSendType" BO_ 873 4;
BA_ "VFrameFormat" BO_ 873 14;
BA_ "GenMsgDelayTime" BO_ 238 10;
BA_ "GenMsgSendType" BO_ 238 1;
BA_ "VFrameFormat" BO_ 238 14;
BA_ "GenMsgCycleTime" BO_ 239 10;
BA_ "GenMsgSendType" BO_ 239 0;
BA_ "VFrameFormat" BO_ 239 14;
BA_ "GenMsgDelayTime" BO_ 1331 20;
BA_ "GenMsgSendType" BO_ 1331 1;
BA_ "VFrameFormat" BO_ 1331 0;
BA_ "GenMsgDelayTime" BO_ 1326 20;
BA_ "GenMsgSendType" BO_ 1326 1;
BA_ "VFrameFormat" BO_ 1326 0;
BA_ "GenMsgCycleTime" BO_ 336 20;
BA_ "GenMsgSendType" BO_ 336 0;
BA_ "VFrameFormat" BO_ 336 14;
BA_ "GenMsgCycleTime" BO_ 340 10;
BA_ "GenMsgSendType" BO_ 340 0;
BA_ "VFrameFormat" BO_ 340 14;
BA_ "GenMsgCycleTime" BO_ 344 20;
BA_ "GenMsgSendType" BO_ 344 0;
BA_ "VFrameFormat" BO_ 344 14;
BA_ "GenMsgCycleTime" BO_ 487 10;
BA_ "GenMsgSendType" BO_ 487 0;
BA_ "VFrameFormat" BO_ 487 14;
BA_ "GenMsgDelayTime" BO_ 1318 20;
BA_ "GenMsgSendType" BO_ 1318 1;
BA_ "VFrameFormat" BO_ 1318 0;
BA_ "GenMsgCycleTime" BO_ 337 20;
BA_ "GenMsgSendType" BO_ 337 0;
BA_ "VFrameFormat" BO_ 337 14;
BA_ "GenMsgCycleTime" BO_ 338 10;
BA_ "GenMsgSendType" BO_ 338 0;
BA_ "VFrameFormat" BO_ 338 14;
BA_ "GenMsgCycleTime" BO_ 354 20;
BA_ "GenMsgSendType" BO_ 354 0;
BA_ "VFrameFormat" BO_ 354 14;
BA_ "GenMsgCycleTime" BO_ 179 10;
BA_ "GenMsgSendType" BO_ 179 0;
BA_ "VFrameFormat" BO_ 179 14;
BA_ "GenSigStartValue" SG_ 425 LonAccr 25000;
BA_ "GenSigStartValue" SG_ 425 LonSnsrSt 1;
BA_ "GenSigStartValue" SG_ 426 LatAccr 25000;
BA_ "GenSigStartValue" SG_ 426 LatAccrSt 1;
BA_ "GenSigStartValue" SG_ 426 YawRate 30000;
BA_ "GenSigStartValue" SG_ 426 YawRateSnsrSt 1;
BA_ "GenSigStartValue" SG_ 512 DrvMdlStsFrmADD 1;
BA_ "GenSigStartValue" SG_ 516 ParkProgressSigReDistFrmADD 511;
BA_ "GenSigStartValue" SG_ 516 PRAMoveSigReDistFrmADD 255;
BA_ "GenSigSendType" SG_ 528 ADDSyncFVReq 1;
BA_ "GenSigStartValue" SG_ 661 ADSRCTBTarDecelFrmADD 200;
BA_ "GenSigStartValue" SG_ 775 ParkProgressSigLFPosXFrmADD 65535;
BA_ "GenSigStartValue" SG_ 775 ParkProgressSigLFPosYFrmADD 65535;
BA_ "GenSigStartValue" SG_ 775 ParkProgressSigLRPosXFrmADD 65535;
BA_ "GenSigStartValue" SG_ 775 ParkProgressSigLRPosYFrmADD 65535;
BA_ "GenSigStartValue" SG_ 775 ParkProgressSigRFPosXFrmADD 65535;
BA_ "GenSigStartValue" SG_ 775 ParkProgressSigRFPosYFrmADD 65535;
BA_ "GenSigStartValue" SG_ 775 ParkProgressSigRRPosXFrmADD 65535;
BA_ "GenSigStartValue" SG_ 775 ParkProgressSigRRPosYFrmADD 65535;
BA_ "GenSigSendType" SG_ 873 LowPwrReqFrLdrFrmADD 1;
BA_ "GenSigSendType" SG_ 873 LowPwrReqFrRdrFrmADD 1;
BA_ "GenSigSendType" SG_ 238 ADD2BLEMForRPA00 1;
BA_ "GenSigSendType" SG_ 238 ADD2BLEMForRPA00FV 1;
BA_ "GenSigSendType" SG_ 238 ADD2BLEMForRPA00MAC 1;
BA_ "GenSigSendType" SG_ 238 ADD2BLEMForRPA01 1;
BA_ "GenSigSendType" SG_ 238 ADD2BLEMForRPA02 1;
BA_ "GenSigSendType" SG_ 238 ADD2BLEMForRPA03 1;
BA_ "GenSigSendType" SG_ 1331 ADDChassisBkpActiveWakeup 1;
BA_ "GenSigSendType" SG_ 1331 ADDChassisBkpNodeAddress 1;
BA_ "GenSigSendType" SG_ 1331 ADDChassisBkpRepeatMsgReq 1;
BA_ "GenSigSendType" SG_ 1331 ADDChassisBkpRepeatMsgSt 1;
BA_ "GenSigSendType" SG_ 1331 NMKeepAwkRsnADD 1;
BA_ "GenSigSendType" SG_ 1331 UDB17ADD 1;
BA_ "GenSigSendType" SG_ 1331 UDB18ADD 1;
BA_ "GenSigSendType" SG_ 1331 UDB19ADD 1;
BA_ "GenSigSendType" SG_ 1331 UDB20ADD 1;
BA_ "GenSigSendType" SG_ 1331 UDB21ADD 1;
BA_ "GenSigSendType" SG_ 1331 UDB22ADD 1;
BA_ "GenSigSendType" SG_ 1331 UDB23ADD 1;
BA_ "GenSigSendType" SG_ 1331 UDB24ADD 1;
BA_ "GenSigSendType" SG_ 1331 UDB25ADD 1;
BA_ "GenSigSendType" SG_ 1331 UDB26ADD 1;
BA_ "GenSigSendType" SG_ 1331 UDB27ADD 1;
BA_ "GenSigSendType" SG_ 1331 UDB28ADD 1;
BA_ "GenSigSendType" SG_ 1331 UDB29ADD 1;
BA_ "GenSigSendType" SG_ 1331 UDB30ADD 1;
BA_ "GenSigSendType" SG_ 1331 UDB31ADD 1;
BA_ "GenSigSendType" SG_ 1331 UDB32ADD 1;
BA_ "GenSigSendType" SG_ 1331 UDB33ADD 1;
BA_ "GenSigSendType" SG_ 1331 UDB34ADD 1;
BA_ "GenSigSendType" SG_ 1331 UDB35ADD 1;
BA_ "GenSigSendType" SG_ 1331 UDB36ADD 1;
BA_ "GenSigSendType" SG_ 1331 UDB37ADD 1;
BA_ "GenSigSendType" SG_ 1331 UDB38ADD 1;
BA_ "GenSigSendType" SG_ 1331 UDB39ADD 1;
BA_ "GenSigSendType" SG_ 1331 UDB40ADD 1;
BA_ "GenSigSendType" SG_ 1331 UDB41ADD 1;
BA_ "GenSigSendType" SG_ 1331 UDB42ADD 1;
BA_ "GenSigSendType" SG_ 1331 UDB43ADD 1;
BA_ "GenSigSendType" SG_ 1331 UDB44ADD 1;
BA_ "GenSigSendType" SG_ 1331 UDB45ADD 1;
BA_ "GenSigSendType" SG_ 1331 UDB46ADD 1;
BA_ "GenSigSendType" SG_ 1331 UDB47ADD 1;
BA_ "GenSigSendType" SG_ 1326 ADDChassisBkpActiveWakeup1 1;
BA_ "GenSigSendType" SG_ 1326 ADDChassisBkpNodeAddress1 1;
BA_ "GenSigSendType" SG_ 1326 ADDChassisBkpRepeatMsgReq1 1;
BA_ "GenSigSendType" SG_ 1326 ADDChassisBkpRepeatMsgSt1 1;
BA_ "GenSigSendType" SG_ 1326 NMKeepAwkRsnADD 1;
BA_ "GenSigSendType" SG_ 1326 UDB17ADD 1;
BA_ "GenSigSendType" SG_ 1326 UDB18ADD 1;
BA_ "GenSigSendType" SG_ 1326 UDB19ADD 1;
BA_ "GenSigSendType" SG_ 1326 UDB20ADD 1;
BA_ "GenSigSendType" SG_ 1326 UDB21ADD 1;
BA_ "GenSigSendType" SG_ 1326 UDB22ADD 1;
BA_ "GenSigSendType" SG_ 1326 UDB23ADD 1;
BA_ "GenSigSendType" SG_ 1326 UDB24ADD 1;
BA_ "GenSigSendType" SG_ 1326 UDB25ADD 1;
BA_ "GenSigSendType" SG_ 1326 UDB26ADD 1;
BA_ "GenSigSendType" SG_ 1326 UDB27ADD 1;
BA_ "GenSigSendType" SG_ 1326 UDB28ADD 1;
BA_ "GenSigSendType" SG_ 1326 UDB29ADD 1;
BA_ "GenSigSendType" SG_ 1326 UDB30ADD 1;
BA_ "GenSigSendType" SG_ 1326 UDB31ADD 1;
BA_ "GenSigSendType" SG_ 1326 UDB32ADD 1;
BA_ "GenSigSendType" SG_ 1326 UDB33ADD 1;
BA_ "GenSigSendType" SG_ 1326 UDB34ADD 1;
BA_ "GenSigSendType" SG_ 1326 UDB35ADD 1;
BA_ "GenSigSendType" SG_ 1326 UDB36ADD 1;
BA_ "GenSigSendType" SG_ 1326 UDB37ADD 1;
BA_ "GenSigSendType" SG_ 1326 UDB38ADD 1;
BA_ "GenSigSendType" SG_ 1326 UDB39ADD 1;
BA_ "GenSigSendType" SG_ 1326 UDB40ADD 1;
BA_ "GenSigSendType" SG_ 1326 UDB41ADD 1;
BA_ "GenSigSendType" SG_ 1326 UDB42ADD 1;
BA_ "GenSigSendType" SG_ 1326 UDB43ADD 1;
BA_ "GenSigSendType" SG_ 1326 UDB44ADD 1;
BA_ "GenSigSendType" SG_ 1326 UDB45ADD 1;
BA_ "GenSigSendType" SG_ 1326 UDB46ADD 1;
BA_ "GenSigSendType" SG_ 1326 UDB47ADD 1;
BA_ "GenSigStartValue" SG_ 336 BCPMstCylP 100;
BA_ "GenSigStartValue" SG_ 336 BCPSimulatorP 100;
BA_ "GenSigStartValue" SG_ 336 InpRodStk 100;
BA_ "GenSigStartValue" SG_ 340 InpRodStkBkp 100;
BA_ "GenSigStartValue" SG_ 487 BrkSysFTarDrvr 2047;
BA_ "GenSigSendType" SG_ 1318 BCPChassisBkpActiveWakeup 1;
BA_ "GenSigSendType" SG_ 1318 BCPChassisBkpNodeAddress 1;
BA_ "GenSigSendType" SG_ 1318 BCPChassisBkpRepeatMsgReq 1;
BA_ "GenSigSendType" SG_ 1318 BCPChassisBkpRepeatMsgSt 1;
BA_ "GenSigSendType" SG_ 1318 NMKeepAwkRsnBCP 1;
BA_ "GenSigSendType" SG_ 1318 UDB17BCP 1;
BA_ "GenSigSendType" SG_ 1318 UDB18BCP 1;
BA_ "GenSigSendType" SG_ 1318 UDB19BCP 1;
BA_ "GenSigSendType" SG_ 1318 UDB20BCP 1;
BA_ "GenSigSendType" SG_ 1318 UDB21BCP 1;
BA_ "GenSigSendType" SG_ 1318 UDB22BCP 1;
BA_ "GenSigSendType" SG_ 1318 UDB23BCP 1;
BA_ "GenSigSendType" SG_ 1318 UDB24BCP 1;
BA_ "GenSigSendType" SG_ 1318 UDB25BCP 1;
BA_ "GenSigSendType" SG_ 1318 UDB26BCP 1;
BA_ "GenSigSendType" SG_ 1318 UDB27BCP 1;
BA_ "GenSigSendType" SG_ 1318 UDB28BCP 1;
BA_ "GenSigSendType" SG_ 1318 UDB29BCP 1;
BA_ "GenSigSendType" SG_ 1318 UDB30BCP 1;
BA_ "GenSigSendType" SG_ 1318 UDB31BCP 1;
BA_ "GenSigSendType" SG_ 1318 UDB32BCP 1;
BA_ "GenSigSendType" SG_ 1318 UDB33BCP 1;
BA_ "GenSigSendType" SG_ 1318 UDB34BCP 1;
BA_ "GenSigSendType" SG_ 1318 UDB35BCP 1;
BA_ "GenSigSendType" SG_ 1318 UDB36BCP 1;
BA_ "GenSigSendType" SG_ 1318 UDB37BCP 1;
BA_ "GenSigSendType" SG_ 1318 UDB38BCP 1;
BA_ "GenSigSendType" SG_ 1318 UDB39BCP 1;
BA_ "GenSigSendType" SG_ 1318 UDB40BCP 1;
BA_ "GenSigSendType" SG_ 1318 UDB41BCP 1;
BA_ "GenSigSendType" SG_ 1318 UDB42BCP 1;
BA_ "GenSigSendType" SG_ 1318 UDB43BCP 1;
BA_ "GenSigSendType" SG_ 1318 UDB44BCP 1;
BA_ "GenSigSendType" SG_ 1318 UDB45BCP 1;
BA_ "GenSigSendType" SG_ 1318 UDB46BCP 1;
BA_ "GenSigSendType" SG_ 1318 UDB47BCP 1;
BA_ "GenSigStartValue" SG_ 337 EstimdSumOfVehHydBrkEachWhl 31250;
BA_ "GenSigStartValue" SG_ 338 BiasMaxFrntAxle 100;
BA_ "GenSigStartValue" SG_ 338 BiasMaxReAxle 100;
BA_ "GenSigStartValue" SG_ 338 TarRdcdPtTqFA 30000;
BA_ "GenSigStartValue" SG_ 338 TarRdcdPtTqRA 30000;
BA_ "GenSigStartValue" SG_ 338 TarRecuTqReq 32767;
BA_ "GenSigStartValue" SG_ 354 RPBAx 25000;
BA_ "GenSigStartValue" SG_ 354 RPBAxSt 1;
VAL_ 425 IMUCalSt 0 "IMU_not_Calibrated" 1 "IMU_Calibrated" ;
VAL_ 425 LonSnsrSt 0 "SIG_IN_SPEC" 1 "SIGNOTAVAIL" 2 "SIGFAIL" 3 "Reserved" ;
VAL_ 426 LatAccrSt 0 "SIG_IN_SPEC" 1 "SIGNOTAVAIL" 2 "SIGFAIL" 3 "Reserved" ;
VAL_ 426 YawRateSnsrSt 0 "SIG_IN_SPEC" 1 "SIGNOTAVAIL" 2 "SIGFAIL" 3 "Reserved" ;
VAL_ 848 ACUWarnLampSts 0 "LampOFF" 1 "LampON" 2 "Blinking" 3 "Reserved" ;
VAL_ 848 DrvrBucSts 0 "Buckled" 1 "Unbuckle" 2 "Reserved" 3 "Reserved" ;
VAL_ 848 PassAirbDiIndcr 0 "enabled" 1 "disable" ;
VAL_ 848 PassBucSts 0 "Buckled" 1 "Unbuckle" 2 "Reserved" 3 "Reserved" ;
VAL_ 848 SecRowLeBucSts 0 "Buckled" 1 "Unbuckle" 2 "Reserved" 3 "Reserved" ;
VAL_ 848 SecRowMidBucSts 0 "Buckled" 1 "Unbuckle" 2 "Reserved" 3 "Reserved" ;
VAL_ 848 SecRowRiBucSts 0 "Buckled" 1 "Unbuckle" 2 "Reserved" 3 "Reserved" ;
VAL_ 848 ThrdRowLeBucSts 0 "Buckled" 1 "Unbuckle" 2 "Reserved" 3 "Reserved" ;
VAL_ 848 ThrdRowMidBucSts 0 "Buckled" 1 "Unbuckle" 2 "Reserved" 3 "Reserved" ;
VAL_ 848 ThrdRowRiBucSts 0 "Buckled" 1 "Unbuckle" 2 "Reserved" 3 "Reserved" ;
VAL_ 379 ADDKeepAwakeReq 0 "No_request" 1 "Request" ;
VAL_ 379 ParkGearReqEnaFrmADD 0 "No_Request" 1 "Request" 2 "Failure" ;
VAL_ 379 ParkGearReqFrmADD 0 "Norequest" 1 "P" 2 "R" 3 "N" 4 "D" ;
VAL_ 379 RPAHVOnReqFrmADD 0 "No_request" 1 "Request" ;
VAL_ 379 RPAPrkinRecdFrmADD 0 "Default" 1 "RPA_In" 2 "Manual_In" 3 "Reserved" ;
VAL_ 399 HPPAVPRecoverIndCtrlBkp 0 "No_Request" 1 "Request" ;
VAL_ 399 HPPAVPSteerWhlCtrlReqStsBkp 0 "NoRequest" 1 "Ready" 2 "active" 3 "Failure" ;
VAL_ 493 DrvAirSuspReqFrmADD 0 "no_request" 1 "request" ;
VAL_ 493 ParkAirSuspReqFrmADD 0 "No_Request" 1 "Request_Forbid" 2 "Request_LiftToNL" 3 "Request_LiftToHL" ;
VAL_ 512 ADDBSDLCAStsFrmADD 0 "Off" 1 "Standby" 2 "Active" 3 "Failure" ;
VAL_ 512 ADSAEBStsFrmADD 0 "Off" 1 "Standby" 2 "Active" 3 "Failure" 4 "Reserved" 5 "Reserved" 6 "Reserved" 7 "Reserved" ;
VAL_ 512 ADSAEBTarDirFrmADD 0 "default" 1 "Left" 2 "Middle" 3 "Right" 4 "unavailable" ;
VAL_ 512 ADSAEBWarnReqFrmADD 0 "no_warning" 1 "warning_level_1" 2 "reserved" 3 "reserved" ;
VAL_ 512 AdsAutoTurnLiCnclReqFrmADD 0 "No_request" 1 "Cancel_left_request" 2 "Cancel_right_request" ;
VAL_ 512 AdsAutoTurnLiSwtStsFrmADD 0 "Default" 1 "Off" 2 "On" 3 "Off_not_support_click" 4 "On_not_support_click" 5 "Unavailable" ;
VAL_ 512 AdsAutoTurnLiUnavlRsnFrmADD 0 "default" 1 "No_reason_req" 2 "not_P_gear" 3 "account_not_log_in" 4 "not_authorized" 5 "Pilot_active" 6 "privacy_mode" 7 "extreme_eco_mode" 8 "lowpower_mode" 9 "parking_function_active" 10 "adas_not_purchased" 11 "Error_detected" 12 "NOA_active" 13 "Reserved_1" 14 "Reserved_2" ;
VAL_ 512 ADSBSDLCAAudioWarnReqFrmADD 0 "default" 1 "no_request" 2 "audio_request" ;
VAL_ 512 ADSBSDLCAWarnReqLeFrmADD 0 "no_warning" 1 "warning_level_1" 2 "warning_level_2" ;
VAL_ 512 ADSBSDLCAWarnReqRiFrmADD 0 "no_warning" 1 "warning_level_1" 2 "warning_level_2" ;
VAL_ 512 ADSBSDLightWarningLeReqFrmADD 0 "no_request" 1 "warning_level1" 2 "warning_level2" ;
VAL_ 512 ADSBSDLightWarningRiReqFrmADD 0 "no_request" 1 "warning_level1" 2 "warning_level2" ;
VAL_ 512 ADSDOWStsFrmADD 0 "Off" 1 "Standby" 2 "Active" 3 "Failure" ;
VAL_ 512 ADSDOWWarnReqFrLeFrmADD 0 "no_warning" 1 "warning_level_1" 2 "warning_level_2" 3 "reserved" ;
VAL_ 512 ADSDOWWarnReqFrRiFrmADD 0 "no_warning" 1 "warning_level_1" 2 "warning_level_2" 3 "reserved" ;
VAL_ 512 ADSDOWWarnReqReLeFrmADD 0 "no_warning" 1 "warning_level_1" 2 "warning_level_2" 3 "reserved" ;
VAL_ 512 ADSDOWWarnReqReRiFrmADD 0 "no_warning" 1 "warning_level_1" 2 "warning_level_2" 3 "reserved" ;
VAL_ 512 ADSELKStsFrmADD 0 "Off" 1 "Standby" 2 "NoWarning" 3 "LeftOverride" 4 "LeftWarning" 5 "RightOverride" 6 "RightWarning" 7 "Fault" ;
VAL_ 512 ADSESSStsFrmADD 0 "Off" 1 "Standby" 2 "Active" 3 "Failure" 4 "Reserved" 5 "Reserved" 6 "Reserved" 7 "Reserved" ;
VAL_ 512 ADSESSWarnReqFrmADD 0 "NoRequest" 1 "Request" ;
VAL_ 512 ADSFCWReqFrmADD 0 "no_warning" 1 "warning_level_1" 2 "warning_level_2" ;
VAL_ 512 ADSFCWStsFrmADD 0 "Off" 1 "Standby" 2 "Active" 3 "Failure" 4 "Reserved" 5 "Reserved" 6 "Reserved" 7 "Reserved" ;
VAL_ 512 AdsIntelgntSpdSwtStsFrmADD 0 "Default" 1 "Off" 2 "On" 3 "Off_not_support_click" 4 "On_not_support_click" 5 "Unavailable" ;
VAL_ 512 AdsIntelgntSpdUnavlRsnFrmADD 0 "default" 1 "No_reason_req" 2 "Map_error" 3 "Error_detected" 4 "Reserved_1" 5 "Reserved_2" ;
VAL_ 512 ADSLDPHandOffExitFrmADD 0 "No_Request" 1 "Request" ;
VAL_ 512 ADSLDPHandOffWarningFrmADD 0 "No_request" 1 "WarningLevel1" 2 "WarningLevel2" 3 "WarningLevel3" ;
VAL_ 512 ADSLDPStsFrmADD 0 "Off" 1 "Standby" 2 "NoWarning" 3 "LeftOverride" 4 "LeftWarning" 5 "RightOverride" 6 "RightWarning" 7 "Fault" ;
VAL_ 512 ADSLDPWarnReqLeFrmADD 0 "NoRequest" 1 "Request" ;
VAL_ 512 ADSLDPWarnReqRiFrmADD 0 "NoRequest" 1 "Request" ;
VAL_ 512 ADSLDWStsFrmADD 0 "Off" 1 "Standby" 2 "NoWarning" 3 "LeftOverride" 4 "LeftWarning" 5 "RightOverride" 6 "RightWarning" 7 "Fault" ;
VAL_ 512 ADSLDWWarnLeReqFrmADD 0 "NoRequest" 1 "request" ;
VAL_ 512 ADSLDWWarnRiReqFrmADD 0 "NoRequest" 1 "request" ;
VAL_ 512 AdsLearnSwtStsFrmADD 0 "Default" 1 "No_Display" 2 "Display" 3 "Display_not_support_click" ;
VAL_ 512 AdsLearnSwtUnavlRsnFrmADD 0 "default" 1 "No_reason_req" 2 "not_P_gear" 3 "account_not_log_in" 4 "not_authorized" 5 "Reserved_1" 6 "privacy_mode" 7 "extreme_eco_mode" 8 "lowpower_mode" 9 "Reserved_2" 10 "adas_not_purchased" 11 "Error_detected" 12 "Reserved_3" ;
VAL_ 512 ADSLiReqFrmADD 0 "no_request" 1 "request" ;
VAL_ 512 ADSMAIInhibitReqFrmADD 0 "no_request" 1 "request" 2 "reseved1" 3 "reseved2" ;
VAL_ 512 ADSMAIStsFrmADD 0 "Off" 1 "Passive" 2 "Standby" 3 "ActiveInhibit" 4 "ActiveWarning" 5 "Fault" 6 "Reserved1" 7 "Reserved2" ;
VAL_ 512 ADSMAIWarnReqFrmADD 0 "no_request" 1 "request" 2 "reseved1" 3 "reseved2" ;
VAL_ 512 AdsModSwtStsFrmADD 0 "Default" 1 "ACC_On" 2 "LCC_On" 3 "NOA_On" 4 "ACC_On_NOA_Not_Support_Click" 5 "LCC_On_NOA_Not_Support_Click" 6 "ACC_On_LCC_Not_Support_Click" 7 "ACC_On_All_Not_Support_Click" 8 "LCC_On_All_Not_Support_Click" 9 "NOA_On_All_Not_Support_Click" 10 "Unavailable" ;
VAL_ 512 AdsNOAOddSwtStsFrmADD 0 "Default" 1 "Highway" 2 "Urban_road" 3 "Highway_and_Urban_road" 4 "HNOA_Active" 5 "CNOA_Active" 6 "CNOA_not_support_click" 7 "unavailable" ;
VAL_ 512 AdsNOAOddSwtUnavlRsnFrmADD 0 "default" 1 "No_reason_req" 2 "Hnoa_active" 3 "Cnoa_active" 4 "CNOA_not_learned" 5 "Error_detected" 6 "reserved_1" 7 "reserved_2" ;
VAL_ 512 ADSRCTAStsFrmADD 0 "Off" 1 "Standby" 2 "Active" 3 "Failure" ;
VAL_ 512 ADSRCTAWarnReqLeFrmADD 0 "no_warning" 1 "warning_level_1" 2 "warning_level_2" ;
VAL_ 512 ADSRCTAWarnReqRiFrmADD 0 "no_warning" 1 "warning_level_1" 2 "warning_level_2" ;
VAL_ 512 ADSRCTBStsFrmADD 0 "Off" 1 "Standby" 2 "Active" 3 "Failure" ;
VAL_ 512 ADSRCTBWarnReqLeFrmADD 0 "no_warning" 1 "warning_level_1" 2 "warning_level_2" ;
VAL_ 512 ADSRCTBWarnReqRiFrmADD 0 "no_warning" 1 "warning_level_1" 2 "warning_level_2" ;
VAL_ 512 ADSRCWStsFrmADD 0 "Off" 1 "Standby" 2 "Active" 3 "Failure" ;
VAL_ 512 ADSRCWWarnReqFrmADD 0 "no_warning" 1 "warning_level_1" 2 "warning_level_2" ;
VAL_ 512 ADSSysErrorRmdFrmADD 0 "default" 1 "fault" 2 "reserved_1" 3 "reserved_2" ;
VAL_ 512 ADSSysErrorStsFrmADD 0 "default" 1 "fault" 2 "reserved_1" 3 "reserved_2" ;
VAL_ 512 ADSTakeoverRmdFrmADD 0 "default" 1 "takeover_adc" 2 "takeover_adp" 3 "reserved_1" ;
VAL_ 512 ADSTLAStsFrmADD 0 "Off" 1 "Standby" 2 "Active1" 3 "Active2" 4 "Failure" ;
VAL_ 512 AdsTrfcLiCtrlSwtStsFrmADD 0 "Default" 1 "Off" 2 "On" 3 "Unavailable" ;
VAL_ 512 ADSVcCtrlArbFrmADD 0 "No_Conflict" 1 "Conflict" 2 "Reserved" 3 "Reserved" ;
VAL_ 512 AdsVehDetourSwtStsFrmADD 0 "Default" 1 "Off" 2 "On" 3 "Unavailable" ;
VAL_ 512 AEBTarObjClassFrmADD 0 "Unknown" 1 "4_wheeler" 2 "2_wheeler" 3 "Pedestrian" ;
VAL_ 512 AutoDrvLaneChgStsFrmADD 0 "unavailable" 1 "passive" 2 "standby" 3 "LaneChangeWaiting" 4 "LaneChangelateralmovement" 5 "LaneChangeChangeManoeuvre" 6 "LaneChangeChangeReturning" 7 "LaneChangeTakeover" 8 "LaneChangeFinish" ;
VAL_ 512 AVMCamVideoChainSts 0 "Normal" 1 "Error Level1" 2 "Error Level2" 3 "Reserved" ;
VAL_ 512 DrvAtmLiReqFrmADD 0 "NoRequest" 1 "Request" ;
VAL_ 512 DrvGearReqFrmADD 0 "Norequest" 1 "P" 2 "R" 3 "N" 4 "D" ;
VAL_ 512 DrvGearReqVldFrmADD 0 "Invalid" 1 "Valid" ;
VAL_ 512 DrvHUDDspFrmADD 0 "no_display" 1 "NOA_Active" 2 "NOA_Quit" 3 "Pilot_Active" 4 "Pilot_Quit" 5 "ACC_Active" 6 "ACC_Quit" 7 "ALC_active_left" 8 "ALC_active_right" 9 "ALC_warning_left" 10 "ALC_warning_right" ;
VAL_ 512 DrvLaneChgStsFrmADD 0 "unavailable" 1 "passive" 2 "standby" 3 "LaneChangeWaiting" 4 "LaneChangelateralmovement" 5 "LaneChangeChangeManoeuvre" 6 "LaneChangeChangeReturning" 7 "LaneChangeTakeover" 8 "LaneChangeFinish" ;
VAL_ 512 DrvMdlStsFrmADD 0 "NoRequest" 1 "DrivingModel_1" 2 "DrivingModel_2" 3 "DrivingMode_3" 4 "DrivingMode_4" ;
VAL_ 512 DrvNOARemdFrmADD 0 "no_display" 1 "NOA_active" 2 "NOA_quit" 3 "upgrade_to_NOA" 4 "degrade_to_LCC" 5 "degrade_to_ACC" 6 "rerouting_due_to_navigation_failed_" 7 "upgrade_to_NOA_due_to_Navigation_vaild" 8 "degrade_to_LCC_due_to_Navigation_failed" 9 "About_to_reroute" 10 "degrade_to_LCC_due_to_out_of_range" 11 "function_quit_due_to_arrive" 12 "NOA_vaild_reminder" 13 "entry_ramp_towards_left" 14 "entry_ramp_towards_right" 15 "entry_ramp_with_left_lever" 16 "entry_ramp_with_right_lever" 17 "inaccessible_ramp_and_left_lane_change" 18 "inaccessible_ramp_and_right_lane_change" 19 "enter_and_to_left" 20 "enter__and_to_right" 21 "enter_and_to_left_lever" 22 "enter__and_to_right_lever" 23 "not_enter_and_towards_left" 24 "not_enter_and_towards_right" 25 "lane_change_fail_and_towards_left" 26 "lane_change_fail_and_towards_Right" 27 "cannot_be_merged" 28 "faster_lane_and_lever" 29 "better_lane_and_lever" 30 "avoid_the_truck_and_lever" 31 "traffic_jam_and_lever_" 32 "lane_change_left_and_lever" 33 "lane_change_right_and_lever" 34 "lane_merging_and_lever" 35 "lane_changing_and_lever" 36 "navigation_lane_change_and_lever" 37 "avoid_risk_lane_and_lever" 38 "approaching_the_red_light" 39 "remind_to_traffic_light" 40 "waiting_area_confirm" 41 "NOA_quit_and_turn_around" 42 "Accelerator_pedal_confirm" 43 "take_over_remind" 44 "waiting_for_pedestrians" 45 "waiting_and_drive_away" 46 "faster_lane" 47 "reserve" 48 "better_lane" 49 "avoid_the_truck" 50 "traffic_jam" 51 "lane_change_left" 52 "lane_change_right" 53 "lane_merging_" 54 "lane_changing" 55 "navigation_lane_change" 56 "avoid_risk_lane" ;
VAL_ 512 DrvPltSysStsFrmADD 0 "Fault" 1 "Passive" 2 "PilotStandby" 3 "PilotNormalActive" 4 "PilotOverride_Long" 5 "PilotOverride_Lat" 6 "pilotActiveOnlylgt" 7 "Pilotoverlay" 8 "StandActive" 9 "StandWait" 10 "Takeover" 11 "MRM" ;
VAL_ 512 DrvPnt2PntSysStsFrmADD 0 "Default" 1 "Passive" 2 "APA_Standby" 3 "HPP_Standby" 4 "Driving_Standby" 5 "Parking_Active" 6 "Driving_Active" 7 "APA_Parking_In" 8 "APA_Parking_Out" 9 "HPP_Parking_In" 10 "HPP_Parking_Out" 11 "Driving_to_Parking" 12 "Parking_to_Driving" 13 "Fault" 14 "Reserved_0" 15 "Reserved_1" 16 "Reserved_2" 17 "Reserved_3" 18 "Reserved_4" 19 "Reserved_5" 20 "Reserved_6" 21 "Reserved_7" ;
VAL_ 512 DrvrSeldDstLvlFrmADD 0 "NoGapSet" 1 "DistanceLevel1" 2 "DistanceLevel2" 3 "DistanceLevel3" 4 "DistanceLevel4" 5 "DistanceLevel5" 6 "Reserved" 7 "Reserved" ;
VAL_ 512 DrvSysWarnFrmADD 0 "NoRequest" 1 "WarningLevel1" 2 "WarningLevel2" 3 "WarningLevel3" 4 "WarningLevel4" 5 "WarningLevel5" 6 "WarningLevel0" 7 "Reserved" ;
VAL_ 512 DrvTurnLiReqFrmADD 0 "no_request" 1 "Left_turn_request" 2 "Right_turn_request" 3 "hazard_light_request" ;
VAL_ 512 IndcrCancelReqFrmADD 0 "Norequest" 1 "Request" ;
VAL_ 512 LidarCleanReqFrmADD 0 "NoReq" 1 "Req" ;
VAL_ 512 NOASysStsFrmADD 0 "Fault" 1 "Passive" 2 "NOAstandby" 3 "NOANormalActive" 4 "NOAOverride_Long" 5 "StandActive" 6 "StandWait" 7 "Overlay" 8 "Takeover" 9 "MRM" ;
VAL_ 512 NOATypFrmADD 0 "Default" 1 "HNOA" 2 "CNOA" 3 "Reserved_1" ;
VAL_ 512 TSASignQlyFrmADD 127 "invalid" ;
VAL_ 512 TSASignTypeFrmADD 0 "NotDetected" 1 "SpeedLimits" 2 "OvertakingSigns" 3 "StopYieldSigns" 4 "CityLimits_EntryExit" 5 "MotorwayHighway" 6 "PreferenceRoad" 7 "ResidentialAreaSigns" 8 "NoEntry_NoAll" 9 "DangerSigns" 10 "WeatherCondition" 11 "VehicleCategory" 12 "Exit" 13 "Zone" 63 "Unknown" ;
VAL_ 512 TSASpdLimitFrmADD 0 "No_display" 1 "Cancelled" 2 "5" 3 "10" 4 "15" 5 "20" 6 "25" 7 "30" 8 "35" 9 "40" 10 "45" 11 "50" 12 "55" 13 "60" 14 "65" 15 "70" 16 "75" 17 "80" 18 "85" 19 "90" 20 "95" 21 "100" 22 "105" 23 "110" 24 "115" 25 "120" 26 "125" 27 "130" ;
VAL_ 512 TSASpdLimitUnitFrmADD 0 "Unknown" 1 "kmph" 2 "Miph" 3 "Not_used" ;
VAL_ 512 UserFbReqFrmADD 0 "NoRequest" 1 "Request" ;
VAL_ 513 ADSAPPUnableOpenRsnFrmADD 0 "default" 1 "lowpower_mode" 2 "extreme_eco_mode" 3 "Error_detected" 4 "SettingsItemNotOpen" 5 "Privacy_mode" 6 "Reserved_1" 7 "Req_TLC" ;
VAL_ 513 ADSAVPStsFrmADD 0 "OFF" 1 "Passive" 2 "Standby" 3 "Ready" 4 "Active" 5 "RecoverInterrupt" 6 "Completed" 7 "Terminated" 8 "Failure" 9 "Reserved" ;
VAL_ 513 ADSHPPStsFrmADD 0 "OFF" 1 "Passive" 2 "Standby" 3 "Ready" 4 "Active" 5 "RecoverInterrupt" 6 "Completed" 7 "Terminated" 8 "Failure" 9 "RecoverTakeover" 10 "PreStandby" 11 "RoamCalculate" 12 "Reserved_1" 13 "Reserved_2" 14 "Reserved_3" 15 "Reserved_4" ;
VAL_ 513 ADSLRRSnsrStsFrmADD 0 "Normal" 1 "Blocked" 2 "Not_calibrated" 3 "Error" 4 "Reserved" 5 "Reserved" 6 "Reserved" 7 "Reserved" 8 "Reserved" ;
VAL_ 513 ADSRLSRSnsrStsFrmADD 0 "Normal" 1 "Blocked" 2 "Not_calibrated" 3 "Error" 4 "Reserved" 5 "Reserved" 6 "Reserved" 7 "Reserved" 8 "Reserved" ;
VAL_ 513 ADSRRSRSnsrStsFrmADD 0 "Normal" 1 "Blocked" 2 "Not_calibrated" 3 "Error" 4 "Reserved" 5 "Reserved" 6 "Reserved" 7 "Reserved" 8 "Reserved" ;
VAL_ 513 AFrCamStsFrmADD 0 "off" 1 "Standby" 2 "Normal" 3 "Blocked" 4 "Error" 5 "Reserved" 6 "Reserved" 7 "Reserved" ;
VAL_ 513 ALeCamStsFrmADD 0 "off" 1 "Standby" 2 "Normal" 3 "Blocked" 4 "Error" 5 "Reserved" 6 "Reserved" 7 "Reserved" ;
VAL_ 513 APAIcnDispStsFrmADD 0 "no_display" 1 "grey" 2 "light" 3 "yellow_unable_active" 4 "yellow_system_failure" 5 "reserved" 6 "reserved" 7 "reserved" ;
VAL_ 513 APAVcFbFrmADD 0 "No_Command" 1 "Start_Searching" 2 "Speed_High" 3 "Slope_out_of_Limit" 4 "Charging" 5 "ADAS_Function_Active" 6 "Bad_weather" 7 "System_Fail" 8 "Req_Gear_D" 9 "Req_Close_Door_Driver" 10 "Req_Close_Door_Passenger" 11 "Req_Close_Door_LeftRear" 12 "Req_Close_Door_RightRear" 13 "Req_Close_Front_Lid" 14 "Req_Close_Trunk_Lid" 15 "Low_Power_Mode" 16 "Extreme_Economic_Driving_Mode" 17 "Set_button" 18 "One-click_Privacy_Enable" 19 "Trailer_Mode" 20 "Rescue_Mode" 21 "Car_Wash_Mode" 22 "Tire_Change_Mode" 23 "Ejection_Mode" 24 "Snow_Mode" 25 "One-click_Frenzy_Mode" 26 "Track_Mode" 27 "Drift_Mode" 28 "ESC_Off" 29 "ODD_Not_Available" 30 "Not_Press_SSB" 31 "Driver_Door_Open" 32 "Sensor_fail" 33 "Related_ECU_fail" 34 "Comm_fail" 35 "Lidar_Blocked" 36 "SVS_Blocked" 37 "Other_reason" 38 "SOC_LOW" 39 "Close_door" ;
VAL_ 513 APAVcQuitAvlFrmADD 0 "Unavailable" 1 "Available" ;
VAL_ 513 APAVcStsFrmADD 0 "NotDuringAPA" 1 "DuringAPA" ;
VAL_ 513 AReCamStsFrmADD 0 "off" 1 "Standby" 2 "Normal" 3 "Blocked" 4 "Error" 5 "Reserved" 6 "Reserved" 7 "Reserved" ;
VAL_ 513 ARiCamStsFrmADD 0 "off" 1 "Standby" 2 "Normal" 3 "Blocked" 4 "Error" 5 "Reserved" 6 "Reserved" 7 "Reserved" ;
VAL_ 513 AVMOpnReqFrmADD 0 "NoCommand" 1 "2DAVM&Camera" 2 "2DAVM" 3 "Pending" ;
VAL_ 513 AVPIcnDispStsFrmADD 0 "no_display" 1 "grey" 2 "light" 3 "yellow_unable_active" 4 "yellow_system_failure" 5 "reserved" 6 "reserved" 7 "reserved" ;
VAL_ 513 CameraStsforADBFrmADD 0 "Unknown" 1 "Normal" 2 "Blocking" 3 "Fault" ;
VAL_ 513 CameraStsFrmADD 0 "Not_Blocked" 1 "Blocked" ;
VAL_ 513 F120CamStsFrmADD 0 "off" 1 "Standby" 2 "Normal" 3 "Blocked" 4 "Error" 5 "Reserved" 6 "Reserved" 7 "Reserved" ;
VAL_ 513 F120DVRStsFrmADD 0 "Idle" 1 "DVR_service_is_available" 2 "camera_is_not_available" 3 "processing_resource_is_not_available" 4 "connection_is_not_available" 5 "reserved" 6 "reserved" 7 "reserved" ;
VAL_ 513 F30CamStsFrmADD 0 "off" 1 "Standby" 2 "Normal" 3 "Blocked" 4 "Error" 5 "Reserved" 6 "Reserved" 7 "Reserved" ;
VAL_ 513 F30DVRStsFrmADD 0 "Idle" 1 "DVR_service_is_available" 2 "camera_is_not_available" 3 "reserved" 4 "reserved" 5 "reserved" 6 "reserved" 7 "reserved" ;
VAL_ 513 FLidarStsFrmADD 0 "normal" 1 "PerformanceDegradation" 2 "blocked" 3 "Error" 4 "Reserved" ;
VAL_ 513 FUSSStsFrmADD 0 "normal" 1 "blocked" 2 "Error" 3 "Reserved" ;
VAL_ 513 HPPActiveSubStsFrmADD 0 "Default" 1 "Cruising" 2 "Parking" 3 "Failure" ;
VAL_ 513 HPPAlrtWarnFrmADD 0 "No_Request" 1 "Learn_TakeOverWarnRequest" 2 "PlyBak_TakeOverWarnRequest" ;
VAL_ 513 HPPAVPModSts 0 "None" 1 "AVP_Parkin" 2 "HPP_Parkin" 3 "AVP_Parkout" 4 "HPP_Parkout" 5 "Reserved_1" 6 "Reserved_2" 7 "Reserved_3" ;
VAL_ 513 HPPBakMapDfltParkSlotDispFrmADD 0 "No_Request" 1 "HPPBackMapDfltParkSlotDisplayReq" ;
VAL_ 513 HPPDriverOperateDialogFrmADD 0 "No_Request" 1 "LearnOpr_DistanceOutofLimit_Lev2" 2 "LearnOpr_StudyOvertime_Lev2" 3 "LearnOpr_RDistanceOutofLimit_Lev2" 4 "LearnOpr_APATerminated" 5 "LearnOpr_ChooseFinishVehInSlot" 6 "LearnOpr_ChooseFinishVehNotInSlot" 7 "LearnOpr_ManualPVehInSlot" 8 "LearnOpr_ManualPVehNotInSlot" 9 "LearnOpr_OtherReason" 10 "Reserved_1" 11 "Reserved_2" 12 "Reserved_3" 13 "Reserved_4" 14 "Reserved_5" 15 "Req_TLC" ;
VAL_ 513 HPPDriverOperateInd2FrmADD 0 "No_Request" 1 "LearnOpr_ChooseParkSlot" 2 "LearnOpr_ReqClickStartAPAparkButton" 3 "LearnOpr_APATerminatedDriveToDestination" 4 "LearnOpr_HPPlearnCompleted" 5 "PlyBakOpr_StartPlyBak_Recommend(Releasesteerwheel&Brake)" 6 "PlyBakOpr_Recover_ClickStartAPAparkbutton" 7 "PlyBakOpr_Recover_ParkSlotOccpt_choseOth" 8 "PlyBakOpr_Recover_ZoneParkSlotOccpt_choseOth" 9 "PlyBakOpr_Recover_ParkSlotOccpt_choseOth_BckGrLine" 10 "PlyBakOpr_Recover_ClickRecoverHPPbutton" 11 "PlyBakOpr_Recover_DoorOpen" 12 "PlyBakOpr_Recover_EngineFrontDoorOpen" 13 "PlyBakOpr_Recover_TrunkOpen" 14 "PlyBakOpr_Recover_DriverSeatBeltNotTied" 15 "PlyBakOpr_Arriathend_choseOth" 16 "Pause_To_Active" 17 "Reserved_3" 18 "Reserved_4" 19 "Reserved_5" 20 "Reserved_6" 21 "Reserved_7" 22 "Reserved_8" 23 "Reserved_9" 24 "Reserved_10" 25 "Reserved_11" 26 "Reserved_12" 27 "Reserved_13" 28 "Reserved_14" 29 "Reserved_15" 30 "Reserved_16" 31 "Req_TLC" ;
VAL_ 513 HPPDriverOperateIndFrmADD 0 "No_Request" 1 "LearnOpr_HighSpeed" 2 "LearnOpr_DistanceOutOfLimit" 3 "LearnOpr_PathRepeated" 4 "LearnOpr_RuleBroke" 5 "LearnOpr_StudyOverTime" 6 "LearnOpr_ParkingOverTime" 7 "LearnOpr_DriverSeatBeltNotTied" 8 "LearnOpr_IfParkingBrakeChooseSlot" 9 "LearnOpr_BrakeFirstChooseSlot" 10 "LearnOpr_NoParkingSlot" 11 "LearnOpr_ChooseParkingSlotFirst" 12 "LearnOpr_RDistanceOutOfLimit" 13 "PlayBackOpr_NoResponse_gas_pedal" 14 "PlayBackOpr_NoResponseTurnlight" 15 "PlayBackOpr_NoResponseGearShift" 16 "PlyBakOpr_Recover_DoorOpen" 17 "PlyBakOpr_Recover_EngineFrontDoorOpen" 18 "PlyBakOpr_Recover_TrunkOpen" 19 "PlyBakOpr_Recover_DriverSeatBeltNotTied" 20 "PlyBakOpr_Recover_Obstaclesblocktraffic" 21 "PlayBackOpr_BrakeFirstChooseSlot" 22 "PlayBackOpr_ObstructAcs_Takeover" 23 "Reserved_1" 24 "Reserved_2" 25 "Reserved_3" 26 "Reserved_4" 27 "Reserved_5" 28 "Reserved_6" 29 "Reserved_7" 30 "Reserved_8" 31 "Req_TLC" ;
VAL_ 513 HPPIcnDispStsFrmADD 0 "no_display" 1 "grey" 2 "light" 3 "yellow_unable_active" 4 "yellow_system_failure" 5 "learning" 6 "reserved" 7 "reserved" ;
VAL_ 513 HPPInfotipFrmADD 0 "None" 1 "Learn_StartLearningPleaseDrive" 2 "Learn_RoutelearningProcess" 3 "Learn_SpeedBump" 4 "Learn_CrossRoad" 5 "Learn_Ramp" 6 "Learn_ManualParkingProcess" 7 "PlyBak_ThroughGateMachine" 8 "PlyBak_Turningleft" 9 "PlyBak_TurningRight" 10 "PlyBak_SpeedBump" 11 "PlyBak_CrossRoad" 12 "PlyBak_Ramp" 13 "PlyBak_Willcar" 14 "PlyBak_WarningVru" 15 "PlyBak_WarningObstacle" 16 "PlyBak_DetourObstacle" 17 "PlyBak_StartPlyBak_Recommend(Start)" 18 "PlyBak_NearTarParkSlot" 19 "PlyBak_NearTarLocn" 20 "PlyBak_BackMapFindParkingSlot" 21 "PlyBak_WillAPAParkIn_FixSlot" 22 "PlyBak_WillAPAParkIn_PrferceZone" 23 "PlyBak_Completed" 24 "PlyBak_StartPlyBak_Recommend(Start)_Allline" 25 "PlyBak_PlyBakProcess_Recommend_FixSlot_PrferceZone" 26 "PlyBak_PlyBakProcess_Recommend_AllLine" 27 "PlyBak_StartPlyBak_Recommend(Start)_AVPRoam" 28 "PlyBak_PlyBakProcess_Recommend_AVPRoam" 29 "Reserved_3" 30 "Reserved_4" 31 "Reserved_5" 32 "Reserved_6" 33 "Reserved_7" 34 "Reserved_8" 35 "Reserved_9" 36 "Reserved_10" 37 "Reserved_11" 38 "Reserved_12" 39 "Reserved_13" 40 "Reserved_14" 41 "Reserved_15" 42 "Reserved_16" 43 "Reserved_17" 44 "Reserved_18" 45 "Reserved_19" 46 "Reserved_20" 47 "Reserved_21" 48 "Reserved_22" 49 "Reserved_23" 50 "Reserved_24" 51 "Reserved_25" 52 "Reserved_26" 53 "Reserved_27" 54 "Reserved_28" 55 "Reserved_29" 56 "Reserved_30" 57 "Reserved_31" 58 "Reserved_32" 59 "Reserved_33" 60 "Reserved_34" 61 "Reserved_35" 62 "Reserved_36" 63 "Req_TLC" ;
VAL_ 513 HPPLearnSubStsFrmADD 0 "Learnpassive" 1 "Standby" 2 "Crusing" 3 "ManualParking" 4 "APA" 5 "Completed" 6 "Confirmation" 7 "Terminated" 8 "Waiting" 9 "Save" 10 "Failure" ;
VAL_ 513 HPPLrnVcFbFrmADD 0 "NotLearning" 1 "Learning" ;
VAL_ 513 HPPPlayBackPushFrmADD 0 "No_Request" 1 "RecommendUseHPPPlayBack" ;
VAL_ 513 HPPQuitIndFrmADD 0 "No_Request" 1 "LearnQuit_SpeedOutOfLimit" 2 "LearnQuit_longRoute" 3 "LearnQuit_RouteRepeat" 4 "LearnQuit_OverTime" 5 "LearnQuit_UP&DownSlope" 6 "LearnQuit_OverlapTooComplex" 7 "LearnQuit_SystemFailure" 8 "LearnQuit_SlopeOutOfLimit" 9 "LearnQuit_HVSocLow" 10 "LearnQuit_DoorOpen" 11 "LearnQuit_FrontLidOpen" 12 "LearnQuit_RearLidOpen" 13 "LearnQuit_EnvimntEmpty" 14 "LearnQuit_AVMNotOnline" 15 "LearnQuit_RDistanceOutOfLimit" 16 "LearnQuit_DriveInRamp" 17 "LearnQuit_Charging" 18 "LearnQuit_ADAS_Function_Active" 19 "LearnQuit_OtherReason" 20 "PlayBack_SpeedOutofLimit" 21 "PlayBack_GearsShifted" 22 "PlayBack_ParkingOverTime" 23 "PlayBack_ReplayOverTime" 24 "PlayBack_PauseOverTime" 25 "PlayBack_DoorOpen" 26 "PlayBack_FrontLidOpen" 27 "PlayBack_RearLidOpen" 28 "PlayBack_PositionLost" 29 "PlayBack_HVSocLow" 30 "PlayBack_APATerminated" 31 "PlayBack_SystemMalFunction" 32 "PlayBack_EnviromentDisallowed" 33 "PlayBack_SpecialDrivingMode" 34 "PlayBack_BrakingPedalStepped" 35 "PlayBack_SteeringWheelSteered" 36 "PlayBack_OutODD" 37 "PlayBack_DriverQuit" 38 "PlayBack_P" 39 "PlayBack_Charging" 40 "PlayBack_ADAS_Function_Active" 41 "PlayBack_NoParkingSlot" 42 "PlayBack_OtherReason" 43 "PlayBack_RoamCalculateFailed" 44 "PlayBack_NoParkingSlot_Fuzzy" 45 "Reserved_3" 46 "Reserved_4" 47 "Reserved_5" 48 "Reserved_6" 49 "Reserved_7" 50 "Reserved_8" 51 "Reserved_9" 52 "Reserved_10" 53 "Reserved_11" 54 "Reserved_12" 55 "Reserved_13" 56 "Reserved_14" 57 "Reserved_15" 58 "Reserved_16" 59 "Reserved_17" 60 "Reserved_18" 61 "Reserved_19" 62 "Reserved_20" 63 "Reserved_21" 64 "Reserved_22" 65 "Reserved_23" 66 "Reserved_24" 67 "Reserved_25" 68 "Reserved_26" 69 "Reserved_27" 70 "Reserved_28" 71 "Reserved_29" 72 "Reserved_30" 73 "Reserved_31" 74 "Reserved_32" 75 "Reserved_33" 76 "Reserved_34" 77 "Reserved_35" 78 "Reserved_36" 79 "Reserved_37" 80 "Reserved_38" 81 "Reserved_39" 82 "Reserved_40" 83 "Reserved_41" 84 "Reserved_42" 85 "Reserved_43" 86 "Reserved_44" 87 "Reserved_45" 88 "Reserved_46" 89 "Reserved_47" 90 "Reserved_48" 91 "Reserved_49" 92 "Reserved_50" 93 "Reserved_51" 94 "Reserved_52" 95 "Reserved_53" 96 "Reserved_54" 97 "Reserved_55" 98 "Reserved_56" 99 "Reserved_57" 100 "Reserved_58" 101 "Reserved_59" 102 "Reserved_60" 103 "Reserved_61" 104 "Reserved_62" 105 "Reserved_63" 106 "Reserved_64" 107 "Reserved_65" 108 "Reserved_66" 109 "Reserved_67" 110 "Reserved_68" 111 "Reserved_69" 112 "Reserved_70" 113 "Reserved_71" 114 "Reserved_72" 115 "Reserved_73" 116 "Reserved_74" 117 "Reserved_75" 118 "Reserved_76" 119 "Reserved_77" 120 "Reserved_78" 121 "Reserved_79" 122 "Reserved_80" 123 "Reserved_81" 124 "Reserved_82" 125 "Reserved_83" 126 "Reserved_84" 127 "Req_TLC" ;
VAL_ 513 HPPRecoverButtonStsFrmADD 0 "Default" 1 "Passive" 2 "Standby" ;
VAL_ 513 HPPRecoverIndFrmADD 0 "No_Request" 1 "RecvInd_AvodingPedestrains" 2 "RecvInd_AvodingObstacles" 3 "RecvInd_Reversing" 4 "RecvInd_Crossing" 5 "RecvInd_APARequest" 6 "RecvInd_CP_Overtake_Req" 7 "RecvInd_ParkingSpaceOccupied" 8 "RecvInd_TakeOverSteeringWheelRequest" 9 "RecvInd_SelectSpaceAfterBraking" 10 "RecvInd_SapceOccupiedGo2NewSpace" 11 "RecvInd_BrakingPedalStepped" 12 "RecvInd_BrakePedal&SteeringWheelControlled" 13 "RecvInd_GearsShifted" 14 "RecvInd_ObstaclesInterrupted" 15 "RecvInd_GateMachineInterrupted" 16 "RecvInd_ParkingLocked" 17 "RecvInd_GasPedalStepped" 18 "RecvInd_SteeringWheelControlled" 19 "RecvInd_GasPedal&SteeringWheelControlled" ;
VAL_ 513 HPPRouteInd2FrmADD 0 "No_Request" 1 "RouteSavedSucceed" 2 "RoutePreferenceSetSucceed" 3 "RouteSavingProcess" 4 "RouteShareSucceed" 5 "DeleteRouteSucceed" 6 "RouteDownloaded" 7 "RenameSucceed" 8 "Reserved_1" 9 "Reserved_2" 10 "Reserved_3" 11 "Reserved_4" 12 "Reserved_5" 13 "Reserved_6" 14 "Reserved_7" 15 "Req_TLC" ;
VAL_ 513 HPPRouteIndFrmADD 0 "No_Request" 1 "RouteSaveFailed" 2 "RouteSaveFailed_Long" 3 "RouteSaveFailed_FewFeature" 4 "RouteSaveFailed_LargeRepetition" 5 "RouteSaveFailed_HighSpeed" 6 "RouteSaveFailed_SystemFailure" 7 "RouteShareFailure" 8 "DeleteRouteFailed" 9 "RouteDownloadFailed" 10 "Renamefailed" 11 "RoutePreferenceSetFailed" 12 "Reserved_1" 13 "Reserved_2" 14 "Reserved_3" 15 "Reserved_4" 16 "Reserved_5" 17 "Reserved_6" 18 "Reserved_7" 19 "Reserved_8" 20 "Reserved_9" 21 "Reserved_10" 22 "Reserved_11" 23 "Reserved_12" 24 "Reserved_13" 25 "Reserved_14" 26 "Reserved_15" 27 "Reserved_16" 28 "Reserved_17" 29 "Reserved_18" 30 "Reserved_19" 31 "Req_TLC" ;
VAL_ 513 HPPRouteManageStsFrmADD 0 "Abnormal" 1 "Normal" ;
VAL_ 513 HPPUnableToActiveIndFrmADD 0 "No_Request" 1 "UnabLern_Charging" 2 "UnabLern_Go_groundThenDown" 3 "UnabLern_HVSocLow" 4 "UnabLern_BadWeather" 5 "UnabLern_SlopeOutOfLimit" 6 "UnabLern_SystemFailure" 7 "UnabLern_Specialcase" 8 "UnabLern_OutOfCarpark" 9 "UnabLern_Lowpower_mode" 10 "UnabLern_Extreme_eco_mode" 11 "UnabLern_Privacy_mode" 12 "UnabLern_Trailermode" 13 "UnabLern_Rescue_mode" 14 "UnabLern_Tire_change_mode" 15 "UnabLern_Ejector_mode" 16 "UnabLern_Wash_mode" 17 "UnabLern_Snow_mode" 18 "UnabLern_Battle_mode" 19 "UnabLern_Mountain_mode" 20 "UnabLern_Drift_mode" 21 "UnabLern_Setting_option_blocked" 22 "UnabLern_ADAS_Function_Active" 23 "UnabLern_DoorOpen" 24 "UnabLern_FrontLidOpen" 25 "UnabLern_RearLidOpen" 26 "UnabLern_Oth_ODD_Cdn_NotMet" 27 "UnabLern_LidarSysBlkd" 28 "UnabLern_SVSSysBlkd" 29 "UnabLern_HighSpeed" 30 "UnabLern_SSB" 31 "UnabLern_OtherReaon" 32 "UnabPlyBak_Charging" 33 "UnabPlyBak_SpeedOutOfLimit" 34 "UnabPlyBak_DepartureMismatch" 35 "UnabPlyBak_PublicRoad" 36 "UnabPlyBak__HVSocLow" 37 "UnabPlyBak_BadWeather" 38 "UnabPlyBak_SlopeOutOfLimit" 39 "UnabPlyBak_SpecialDrivingMode" 40 "UnabPlyBak_SystemFailure" 41 "UnabPlyBak_NoRouteAvailable" 42 "UnabPlyBak_LargeSWA" 43 "UnabPlyBak_Extreme_eco_mode" 44 "UnabPlyBak_Privacy_mode" 45 "UnabPlyBak_Trailermode" 46 "UnabPlyBak_Rescue_mode" 47 "UnabPlyBak_Tire_change_mode" 48 "UnabPlyBak_Ejector_mode" 49 "UnabPlyBak_Wash_mode" 50 "UnabPlyBak_Snow_mode" 51 "UnabPlyBak_Battle_mode" 52 "UnabPlyBak_Mountain_mode" 53 "UnabPlyBak_Drift_mode" 54 "UnabPlyBak_Setting_option_blocked" 55 "UnabPlyBak_SeatBeltNotBuckled" 56 "UnabPlyBak_DoorOpen" 57 "UnabPlyBak_FrontLidOpen" 58 "UnabPlyBak_RearLidOpen" 59 "UnabPlyBak_DrvrNotOcuped" 60 "UnabPlyBak_ESPOff" 61 "UnabPlyBak_CarInSlot" 62 "UnabPlyBak_CloseToEndAndNoSlot" 63 "UnabPlyBak_Oth_ODD_Cdn_NotMet" 64 "UnabPlyBak_ADAS_Function_Active" 65 "UnabPlyBak_LidarSysBlkd" 66 "UnabPlyBak_SVSSysBlkd" 67 "UnabPlyBak_SideCamSysBlkd" 68 "UnabPlyBak_FrontCamSysBlkd" 69 "UnabPlyBak_RearCamSysBlkd" 70 "UnabPlyBak_lowpower_mode" 71 "UnabPlyBak_SSB" 72 "UnabPlyBak_OtherReaon" 73 "UnabPlyBak_NoNavigationPaths" 74 "UnabPlyBak_INNavigationPathsCalculating" 75 "UnabLern_INAVPCarpark" 76 "UnabPlyBak_HPP_Learning_Try_Later" 77 "UnabPlyBak_Suspension_Adjusted_Try_Later" 78 "UnabPlyBak_HPP_Uavailable_Try_Later" 79 "UnabPlyBak_Function_Unavailable_Temporary" 80 "UnabPlyBak_D_Gear_Please" 81 "UnabPlyBak_Vehicle_Mode_Abnormal" 82 "R_10" 83 "R_11" 84 "R_12" 85 "R_13" 86 "R_14" 87 "R_15" 88 "R_16" 89 "R_17" 90 "R_18" 91 "R_19" 92 "R_20" 93 "R_21" 94 "R_22" 95 "R_23" 96 "R_24" 97 "R_25" 98 "R_26" 99 "R_27" 100 "R_28" 101 "R_29" 102 "R_30" 103 "R_31" 104 "R_32" 105 "R_33" 106 "R_34" 107 "R_35" 108 "R_36" 109 "R_37" 110 "R_38" 111 "R_39" 112 "R_40" 113 "R_41" 114 "R_42" 115 "R_43" 116 "R_44" 117 "R_45" 118 "R_46" 119 "R_47" 120 "R_48" 121 "R_49" 122 "R_50" 123 "R_51" 124 "R_52" 125 "R_53" 126 "R_54" 127 "Req_TLC" ;
VAL_ 513 HPPVehInParkSlotFrmADD 0 "OutParkslot" 1 "InParkslot" ;
VAL_ 513 IMUStsFrmADD 0 "normal" 1 "PerformanceDegradation" 2 "blocked" 3 "Error" 4 "Reserved" ;
VAL_ 513 LidarStsFrmADD 0 "Not_Blocked" 1 "Left_Lidar_Blocked" 2 "Right_Lidar_Blocked" 3 "Both_Blocked" ;
VAL_ 513 ParkVicShdFrmADD 0 "No_Inhibit" 1 "APA_Inhibit" 2 "RPA_Inhibit" 3 "HPP_Inhibit" 4 "AVP_Inhibit" 5 "Reserved" 6 "Reserved" 7 "Reserved" ;
VAL_ 513 PrkSteerWhlBtnLi 0 "No_Request" 1 "Request_breathe_Light" 2 "Reserved" 3 "Reserved" ;
VAL_ 513 ReCamStsFrmADD 0 "off" 1 "Standby" 2 "Normal" 3 "Blocked" 4 "Error" 5 "Reserved" 6 "Reserved" 7 "Reserved" ;
VAL_ 513 ReDVRStsFrmADD 0 "Idle" 1 "DVR_service_is_available" 2 "camera_is_not_available" 3 "processing_resource_is_not_available" 4 "connection_is_not_available" 5 "reserved" 6 "reserved" 7 "reserved" ;
VAL_ 513 RUSSStsFrmADD 0 "normal" 1 "blocked" 2 "Error" 3 "Reserved" ;
VAL_ 513 SLFCamStsFrmADD 0 "off" 1 "Standby" 2 "Normal" 3 "Blocked" 4 "Error" 5 "Reserved" 6 "Reserved" 7 "Reserved" ;
VAL_ 513 SLFDVRStsFrmADD 0 "Idle" 1 "DVR_service_is_available" 2 "camera_is_not_available" 3 "processing_resource_is_not_available" 4 "connection_is_not_available" 5 "reserved" 6 "reserved" 7 "reserved" ;
VAL_ 513 SLLidarStsFrmADD 0 "normal" 1 "PerformanceDegradation" 2 "blocked" 3 "Error" 4 "Reserved" ;
VAL_ 513 SLRCamStsFrmADD 0 "off" 1 "Standby" 2 "Normal" 3 "Blocked" 4 "Error" 5 "Reserved" 6 "Reserved" 7 "Reserved" ;
VAL_ 513 SLRDVRStsFrmADD 0 "Idle" 1 "DVR_service_is_available" 2 "camera_is_not_available" 3 "processing_resource_is_not_available" 4 "connection_is_not_available" 5 "reserved" 6 "reserved" 7 "reserved" ;
VAL_ 513 SnmDetResFrmADD 0 "idle" 1 "Normal" 2 "Abnormal" 3 "Danger" ;
VAL_ 513 SnmF120CamDetResFrmADD 0 "idle" 1 "Normal" 2 "Abnormal" 3 "Danger" ;
VAL_ 513 SnmReCamDetResFrmADD 0 "idle" 1 "Normal" 2 "Abnormal" 3 "Danger" ;
VAL_ 513 SnmSLFCamDetResFrmADD 0 "idle" 1 "Normal" 2 "Abnormal" 3 "Danger" ;
VAL_ 513 SnmSLRCamDetResFrmADD 0 "idle" 1 "Normal" 2 "Abnormal" 3 "Danger" ;
VAL_ 513 SnmSRFCamDetResFrmADD 0 "idle" 1 "Normal" 2 "Abnormal" 3 "Danger" ;
VAL_ 513 SnmSRRCamDetResFrmADD 0 "idle" 1 "Normal" 2 "Abnormal" 3 "Danger" ;
VAL_ 513 SRFCamStsFrmADD 0 "off" 1 "Standby" 2 "Normal" 3 "Blocked" 4 "Error" 5 "Reserved" 6 "Reserved" 7 "Reserved" ;
VAL_ 513 SRLidarStsFrmADD 0 "normal" 1 "PerformanceDegradation" 2 "blocked" 3 "Error" 4 "Reserved" ;
VAL_ 513 SRRCamStsFrmADD 0 "off" 1 "Standby" 2 "Normal" 3 "Blocked" 4 "Error" 5 "Reserved" 6 "Reserved" 7 "Reserved" ;
VAL_ 513 SRRDVRStsFrmADD 0 "Idle" 1 "DVR_service_is_available" 2 "camera_is_not_available" 3 "processing_resource_is_not_available" 4 "connection_is_not_available" 5 "reserved" 6 "reserved" 7 "reserved" ;
VAL_ 516 APAAlrtWarnFrmADD 0 "No_Request" 1 "TakeOverWarnRequest" 2 "Reserved" 3 "Reserved" ;
VAL_ 516 APAButtonReqFrmADD 0 "No_Request" 1 "ParkIn_Request" 2 "ParkOut_Request" 3 "Reserved" ;
VAL_ 516 APARPAActiveSubFunFrmADD 0 "None" 1 "APA_Park_in" 2 "APA_Park_Out" 3 "RPA_Park_in" 4 "RPA_Park_Out" 5 "RPA_Move" ;
VAL_ 516 APARPADriverOperateInd2FrmADD 0 "No_Request" 1 "Search_Choose_Parkslot_Speed_Not_Zero" 2 "Act_NarrowSlot_Mirrors_folding" 3 "Act_No_Response_gaspedal" 4 "Act_No_Response_Steeringlight" 5 "Act_No_Response_GearPaddle" 6 "Act_More_Trajectory_Mode" 7 "Recover_brake_pedal" 8 "Recover_Door_Open" 9 "Recover_FrontLidOpen" 10 "Recover_RearLidOpen" 11 "Warning_DriverControl" 12 "Recover_obstacle" 13 "Search_Door_Open" 14 "Search_FrontLidOpen" 15 "Search_Recover_RearLidOpen" 16 "Recover_DrvrNotOcupcy" 17 "Search_Speed_high" 18 "Search_NarrowSlot_Recommend_RPA" 19 "Tips_Return_APA" 20 "Act_Start_parking_Recommend(Release_steerwheel&Brake)" 21 "Parking_Completed" 22 "Parking_Completed_Stereo_Lot" 23 "Act_ParkOut_ExtMirr_Fold" 24 "Act_ParkOut_ExtMirr_Unfold" 25 "ParkOut_Completed" 26 "Act_Air_Suspension_Control" 27 "OutDoorParkinTips" 28 "Reserved_8" 29 "Reserved_9" 30 "Reserved_10" 31 "Reserved_11" 32 "Reserved_12" 33 "Reserved_13" 34 "Reserved_14" 35 "Reserved_15" 36 "Reserved_16" 37 "Reserved_17" 38 "Reserved_18" 39 "Reserved_19" 40 "Reserved_20" 41 "Reserved_21" 42 "Reserved_22" 43 "Reserved_23" 44 "Reserved_24" 45 "Reserved_25" 46 "Reserved_26" 47 "Reserved_27" 48 "Reserved_28" 49 "Reserved_29" 50 "Reserved_30" 51 "Reserved_31" 52 "Reserved_32" 53 "Reserved_33" 54 "Reserved_34" 55 "Reserved_35" 56 "Reserved_36" 57 "Reserved_37" 58 "Reserved_38" 59 "Reserved_39" 60 "Reserved_40" 61 "Reserved_41" 62 "Reserved_42" 63 "Req_TLC" ;
VAL_ 516 APARPADriverOperateIndFrmADD 0 "No_Request" 1 "Req_Gear_D" 2 "Req_Slow_Down" 3 "Req_Close_Door_Driver" 4 "Req_Close_Door_passenger" 5 "Req_Close_Door_LeftRear" 6 "Req_Close_Door_RightRear" 7 "Req_Close_Engine_Front_Door" 8 "Req_Close_Trunk" 9 "Req_Parking_slot_in_Searching" 10 "Req_ParkOut_is_Available" 11 "Req_Parking_Process_Recommend(PI&PO)_stereo_lot_ARS" 12 "Req_Choose_Park_Slot" 13 "Req_Click_Start_ParkOut_Button" 14 "Req_Parking_Process_Recommend(PI&PO)__stereo_lot" 15 "Req_Choose_Park_out_direction" 16 "Req_Click_Start_APA_park_Button" 17 "Req_Start_parking_Recommend(Release_steerwheel&Brake)" 18 "Req_Parking_process_Recommend(PI&PO)" 19 "Req_Choose_ParkOut_Direction_Speed_Not_Zero" 20 "Req_ParkOut_Gear_D_or_R" 21 "Req_ParkOut_No_Direction" 22 "Req_Leave_car_Control_on_APP" 23 "Req_ParkOut_Direction_Available" 24 "Req_ParkOut_Process_Recommend(PI&PO)_Left" 25 "Req_ParkOut_Process_Recommend(PI&PO)_Right" 26 "Req_ParkOut_ExtMirr_Fold" 27 "Req_ParkOut_ExtMirr_Unfold" 28 "Req_Self_check_RPA_park_out/move__avaiable" 29 "Req_Self_check_only_RPA_move_avaiable" 30 "Req_Close_Door_LeftRear_RPA" 31 "Req_Close_Door_RightRear_RPA" 32 "Req_Close_Engine_Front_Door_RPA" 33 "Req_Close_Trunk_RPA" 34 "Req_RPA_move_completed" 35 "Req_Pop-ups_Choose_system_refence_Parking_Slot" 36 "Req_Keep_Standstill" 37 "Not_P_Gear" 38 "Req_Press_Button_Not_Press_Brakepedal" 39 "Req_Press_Button_N0_Parkslot" 40 "Req_Press_Brakepedal_Parkslot_Exist" 41 "Req_Left_AutoDeviation_APA" 42 "Req_Right_AutoDeviation_APA" 43 "Parking_GearChange_NotAllow" 44 "AD_NotAvl" 45 "Req_Choose_Parkslot_Speed_Not_Zero" 46 "Recom_Narrow" 47 "Choose_ps" 48 "RPAselfcheck" 49 "RPA_move_selfcheck" 50 "No_parking_record" 51 "Can_not_move" 52 "one_button_search" 53 "one_button_bckgrd" 54 "one_button_parking" 55 "Reserved_1" 56 "Reserved_2" 57 "Reserved_3" 58 "Reserved_4" 59 "Reserved_5" 60 "Reserved_6" 61 "Reserved_7" 62 "Reserved_8" 63 "Req_TLC" ;
VAL_ 516 APARPAQuitReasonIndFrmADD 0 "No_Request" 1 "Req_Quit_Searching_Speed_High" 2 "Req_Quit_Searching_Time_Out" 3 "Req_Quit_HDCmode" 4 "Req_Quit_Door_Open_Time_Out" 5 "Req_Quit_Handshake_Fail" 6 "Req_Quit_Driver_Require_Quit" 7 "Req_Quit_Driver_Not_release_Brake_Pedal_Time_Out" 8 "Req_Quit_DriverSeatBelt_Nottied_Time_Out" 9 "Req_Quit_ParkOut_Leave_storage" 10 "Rear_Spoiler_Not_P0" 11 "Req_Quit_Driver_Interrupt_Brake_Pedal_Time_Out" 12 "Req_Quit_Driver_Interrupt_Gear" 13 "Req_Quit_Driver_Interrupt_Steering_Wheel" 14 "Req_Quit_Obstacle_In_Trajectory_Time_Out" 15 "Req_Quit_EPB_UnLock" 16 "Req_Quit_Parking_Total_time_Time_Out" 17 "Req_Quit_Recover_Interrupt_Times_Overflow" 18 "Req_Quit_D/R_Times_Overflow" 19 "Req_Quit_Control_Speed_Over_Limit" 20 "Req_Quit_Path_Planning_Abnormal" 21 "APP_Quit_RPAin" 22 "Req_Quit_Slope_Out_Of_limit" 23 "Req_Quit_ADAS_Function_Active" 24 "Req_Quit_Parking_Total_time_TimeOut_RPA" 25 "Req_Quit_Slope_Out_of_limit_RPA" 26 "Req_Quit_ADD_System_Fail" 27 "Req_Quit_ADD_System_Fail_RPA" 28 "Blue_Tooth_Connect_UnStable_Timeout_RPA_In" 29 "Account_log_out" 30 "Req_Quit_ADAS_Function_Active_RPA" 31 "Blue_Tooth_Connect_UnStable_Timeout_RPA_Move" 32 "Req_Quit_Active_Rear_Spoiler_Not_P0" 33 "Req_Quit_Driver_leave_Phone_RPA_Contro_lPage_Time_Out(RPA)" 34 "APP_Quit_RPA_Move" 35 "Req_Driver_Interrupt_RPA_In" 36 "Req_Driver_Interrupt_RPA_Move" 37 "Req_Quit_Driver_Interrupt_Press_Gas_Pedal(RPA)" 38 "Req_Quit_Driver_Interrupt_Press_Brake_Pedal(RPA)" 39 "Battery_Low_RPA_Move" 40 "Req_Quit_Handshake_Fail_RPA_Move" 41 "Req_Quit_Total_Distance_overrange(RPA_Move)" 42 "Req_Quit_Warning_someone_In_car_Time_Out(RPA)" 43 "Req_Quit_Control_Speed_Over_Limit_RPA_Move" 44 "Req_Quit_Narrow_Slot_RPA_In" 45 "Req_Quit_Timeout_Not_Press_Start_Button(RPA)" 46 "Req_Quit_Stereo_Lot_Narrow" 47 "Req_Quit_Function_off" 48 "BatteryLow" 49 "Req_Quit_Driver_Interrupt_Gear_RPA" 50 "Req_Quit_Driver_Door_Open" 51 "Plannig_Control_Sleep" 52 "Req_Quit_MirrorFold_Fail_RPA" 53 "Req_Quit_MirrorFold_Fail" 54 "Req_Quit_Obstacle_In_Trajectory_TimeOut_RPA_Move" 55 "CounterAbnormal_TimeOut_RPA_In" 56 "CounterAbnormal_TimeOut_RPA_Move" 57 "CRC_Abnormal_RPA_In" 58 "CRC_Abnormal_RPA_Move" 59 "FrontLid_Open_TimeOut" 60 "RearLid_Open_TimeOut" 61 "Req_Quit_OtherReason" 62 "Plannig_Control_Sleep_RPA_Move" 63 "Controller_Abnormal_RPA_Move" ;
VAL_ 516 APARPARecoverIndFrmADD 0 "No_Request" 1 "Req_Recover_DriverSeatBeltNot_tied" 2 "Req_Recover_ParkOut_ExtMirr_Fold" 3 "Req_Recover_Found_Obstacle_In_Trajectory" 4 "Req_Recover_Phone_out_of_range" 5 "Req_Recover_Driver_Press_brake_pedal" 6 "Req_Recover_DoorOpen_Driver" 7 "Req_Recover_DoorOpen_passenger" 8 "Req_Recover_DoorOpen_LeftRear" 9 "Req_Recover_DoorOpen_RightRear" 10 "Req_Recover_Engine_Front_DoorOpen" 11 "Req_Recover_TrunkOpen" 12 "Req_Recover_DoorOpen_RPA" 13 "Req_Recover_Engine_Front_DoorOpen_RPA" 14 "Req_Recover_TrunkOpen_RPA" 15 "Req_Recover_RPA_Move_Driver_Active_pause" 16 "Req_DrvrNotOcupcy" 17 "Pause_To_Active" 18 "CounterAbnormal_RPA_in" 19 "CounterAbnormal_RPA_Move" 20 "Recover_Blue_Tooth_Connect_UnStable_RPA_In" 21 "Recover_Blue_Tooth_Connect_UnStable_RPA_Move" 22 "Reserved_3" 23 "Reserved_4" 24 "Reserved_5" 25 "Reserved_6" 26 "Reserved_7" 27 "Reserved_8" 28 "Reserved_9" 29 "Reserved_10" 30 "Reserved_11" 31 "Lev_Control_Page" ;
VAL_ 516 APARPAstatusFrmADD 0 "Off" 1 "Standby" 2 "background_Searching" 3 "Searching" 4 "Ready" 5 "Active" 6 "Recovery_interrupt" 7 "Completed" 8 "Terminated" 9 "Failure" ;
VAL_ 516 APARPAUnableToActiveIndFrmADD 0 "No_Request" 1 "Speed_high" 2 "Slope_out_of_limit" 3 "Charging" 4 "ADAS_Function_Active" 5 "Speed_ParkOut_Voice" 6 "Not_in_Parking_Space_ParkOut_Voice" 7 "ImpctEvnt_or_ACUWarn_APA" 8 "ParkOut_Stereo_Lot" 9 "Air_suspension_Action" 10 "Low_Power_Mode" 11 "Extreme_Economic_Driving_Mode" 12 "One-click_Privacy_Enable" 13 "Trailer_Mode" 14 "Car_Wash_Mode" 15 "AD_Setting_Not_Enable" 16 "ESC_Off" 17 "ODD_Not_Available" 18 "Driver_Door_Open" 19 "NO_Detailed_Reason_Failure" 20 "Rescue_Mode" 21 "Tire_Change_Mode" 22 "Ejection_Mode" 23 "Snow_Mode" 24 "One-click_Frenzy_Mode" 25 "Track_Mode" 26 "Drift_Mode" 27 "PwrModSts_NotRun" 28 "RPA2APA" 29 "Lidar_Blocked" 30 "SVS_Blocked" 31 "Drv_Mod_Unable_APA" 32 "Drg_Rac_Mode_Active_APA" 33 "Off_Road_Active_APA" 34 "HDC_Mode_Active_APA" 35 "Mountain_Mode_Active_APA" 36 "AntMtnsick_Mode_Active_APA" 37 "Controller_Sleep_RPAmove" 38 "Door_Open_RPA" 39 "FrontLidOpen_RPA" 40 "RearLidOpen_RPA" 41 "SVS_Blocked_Blur" 42 "Account_not_log_in" 43 "Not_P" 44 "Obstacle_RPA" 45 "someone_in_car" 46 "DR_Abnormal_APA" 47 "DR_Abnormal_RPAmove" 48 "System_failure_APA" 49 "ExtmPfmncMod_RPAmove" 50 "Rescue_Mode_RPAmove" 51 "OtherReason" 52 "Speed_Not_Zero_RPAMove" 53 "Low_Pwrmod_RPAMove" 54 "ADAS_Active_RPAMove" 55 "Slope_out_of_limit_RPAMove" 56 "Privacy_Mode_RPAMove" 57 "Trlr_Mode_RPAMove" 58 "Jack_Mode_RPAMove" 59 "Lnch_Plus_RPAMove" 60 "Snow_Mode_RPAMove" 61 "Mountain_Mode_RPAMove" 62 "Battle_Mode_RPAMove" 63 "Extreme_Eco_Mode_RPAMove" ;
VAL_ 516 AVPCharLidCtrlFrmADD 0 "No_Request" 1 "OpenLid" 2 "CloseLid" 3 "Reserved" ;
VAL_ 516 DriverlessStsFrmADD 0 "None" 1 "Driverless_Active" 2 "Reserved_1" 3 "Reserved_2" ;
VAL_ 516 OutdoorPrkDrvrOperIndFrmADD 0 "None" 1 "Req_Close_Door_Driver_RPAmove" 2 "Req_Close_Door_passenger_RPAmove" 3 "Req_Close_Door_Driver_RPAin" 4 "Req_Close_Door_passenger_RPAin" 5 "Req_Close_Door_LeftRear_RPAin" 6 "Req_Close_Door_RightRear_RPAin" 7 "Req_Close_Engine_Front_Door_RPAin" 8 "Req_Close_Trunk_RPAin" 9 "Req_Warning_someone_In_car_RPAmove" 10 "Searching_Lev_Control_Page_RPAin" 11 "Found_Obstacle_In_Trajectory_RPAin" 12 "Reserved_1" 13 "Blue_Tooth_Connect_UnStable_RPAin" 14 "Reserved_2" 15 "Reserved_3" 16 "Reserved_4" 17 "Reserved_5" 18 "Reserved_6" 19 "Blue_Tooth_Connect_UnStable_RPA_Move" 20 "Reserved_7" 21 "Reserved_8" 22 "Reserved_9" 23 "Reserved_10" 24 "Reserved_11" 25 "Req_Warning_someone_In_car_RPAin" 26 "Reserved_12" 27 "Reserved_13" 28 "Reserved_14" 29 "Reserved_15" 30 "Req_Close_Door_LeftRear_RPAmove" 31 "Req_Close_Door_RightRear_RPAmove" 32 "Req_Close_Engine_Front_Door_RPAmove" 33 "Req_Close_Trunk_RPAmove" 35 "Reserved_16" 36 "Reserved_17" 37 "Reserved_18" 38 "Reserved_19" 39 "Reserved_20" 40 "Reserved_21" 41 "Reserved_22" 42 "Reserved_23" 43 "Reserved_24" 44 "Reserved_25" 45 "Reserved_26" 46 "Reserved_27" 47 "Reserved_28" 48 "Reserved_29" 49 "Reserved_30" 50 "Reserved_31" 51 "Reserved_32" 52 "Reserved_33" 53 "Reserved_34" 54 "Reserved_35" 55 "Reserved_36" 56 "Reserved_37" 57 "Reserved_38" 58 "Reserved_39" 59 "Reserved_40" 60 "Reserved_41" 61 "Reserved_42" 62 "Reserved_43" 63 "Reserved_44" ;
VAL_ 516 OutdoorPrkQuitIndFrmADD 0 "None" 1 "FrontLid_Open_TimeOut_RPAmove" 2 "RearLid_Open_TimeOut_RPAmove" 3 "Req_Quit_Door_Open_Time_Out_RPAmove" 4 "Req_Quit_Door_Open_Time_Out_RPAin" 5 "Req_Quit_Handshake_Fail_RPAin" 6 "Req_Quit_Warning_someone_In_car_Time_Out_RPAmove" 7 "Req_Quit_Timeout_Not_Press_Start_Button_RPAmove" 8 "Reserved_1" 9 "Req_Quit_Driver_Interrupt_Steering_Wheel_RPAmove" 10 "Reserved_2" 11 "Reserved_3" 12 "Req_Quit_Driver_Interrupt_Gear_RPAin" 13 "Req_Quit_Driver_Interrupt_Steering_WheelRPAin" 14 "Req_Quit_Obstacle_In_Trajectory_Time_Out_RPAin" 15 "Reserved_4" 16 "Req_Quit_Parking_Total_time_Time_Out_RPAin" 17 "Req_Quit_Recover_Interrupt_Times_Overflow_RPAin" 18 "Req_Quit_D/R_Times_Overflow_RPAin" 19 "Req_Quit_Control_Speed_Over_Limit_RPAin" 20 "Req_Quit_Path_Planning_Abnormal_RPAin" 21 "APP_Quit_RPAIn" 22 "Req_Quit_Slope_Out_Of_limit_RPAin" 23 "Req_Quit_ADAS_Function_Active_RPAin" 24 "Req_Quit_Parking_Total_Time_Out_RPAmove" 25 "Req_Quit_Slope_Out_Of_limit_RPAmove" 26 "Req_Quit_ADD_System_Fail_RPAin" 27 "Req_Quit_ADD_System_Fail_RPAmove" 28 "Blue_Tooth_Connect_UnStable_Timeout_RPA_In" 30 "Req_Quit_ADAS_Function_Active_RPAmove" 31 "Blue_Tooth_Connect_UnStable_Timeout_RPAmove" 32 "Reserved_5" 33 "Req_Quit_Driver_leave_Phone_RPA_Contro_lPage_Time_Out_RPAin" 34 "APP_Quit_RPAmove" 35 "Req_Driver_Interrupt_RPAin" 36 "Req_Driver_Interrupt_RPAmove" 37 "Req_Quit_Driver_Interrupt_Press_Gas_Pedal_RPAin" 38 "Req_Quit_Driver_Interrupt_Press_Brake_Pedal_RPAin" 39 "Battery_Low_RPAmove" 40 "Req_Quit_Handshake_Fail_RPAmove" 41 "Req_Quit_Total_Distance_overrange_RPAmove" 42 "Req_Quit_Warning_someone_In_car_Time_Out_RPAin" 43 "Req_Quit_Control_Speed_Over_Limit_RPAMove" 44 "Req_Quit_Narrow_Slot_RPAin" 45 "Req_Quit_Timeout_Not_Press_Start_Button_RPAin" 46 "Mechanical_Parking_Garage_Narrow_RPAin" 47 "Req_Quit_Function_off_RPAmove" 48 "Battery_Low_RPAin" 49 "Req_Quit_Driver_Interrupt_Gear_RPAmove" 50 "Reserved_6" 51 "Plannig_Control_Sleep_RPAmove" 52 "Req_Quit_MirrorFold_Fail_RPAmove" 53 "Req_Quit_MirrorFold_Fail_RPAin" 54 "Req_Quit_Obstacle_In_Trajectory_Time_Out_RPAmove" 55 "CounterAbnormal_TimeOut_RPAin" 56 "CounterAbnormal_TimeOut_RPAmove" 57 "CRC_Abnormal_RPAin" 58 "CRC_Abnormal_RPAmove" 59 "FrontLid_Open_TimeOut_RPAin" 60 "RearLid_Open_TimeOut_RPAin" 61 "Req_Quit_OtherReason_RPAin" 62 "Reserved_7" 63 "Reserved_8" ;
VAL_ 516 OutdoorPrkRecoverIndFrmADD 0 "None" 1 "Reserved_1" 2 "Req_Recover_Found_Obstacle_In_Trajectory_RPAmove" 3 "Req_Recover_Found_Obstacle_In_Trajectory_RPAin" 4 "Reserved_2" 5 "Reserved_3" 6 "Req_Recover_DoorOpen_Driver_RPAin" 7 "Req_Recover_DoorOpen_passenger_RPAin" 8 "Req_Recover_DoorOpen_LeftRear_RPAin" 9 "Req_Recover_DoorOpen_RightRear_RPAin" 10 "Req_Recover_Engine_Front_DoorOpen_RPAin" 11 "Req_Recover_TrunkOpen_RPAin" 12 "Req_Recover_DoorOpen_RPAmove" 13 "Req_Recover_Engine_Front_DoorOpen_RPAmove" 14 "Req_Recover_TrunkOpen_RPAmove" 15 "Reserved_4" 16 "Reserved_5" 17 "Reserved_6" 18 "CounterAbnormal_RPAin" 19 "CounterAbnormal_RPAmove" 20 "Recover_BlueTooth_Connect_UnStable_RPAin" 21 "Recover_BlueTooth_Connect_UnStable_RPAmove" 22 "Reserved_7" 23 "Reserved_8" 24 "Reserved_9" 25 "Reserved_10" 26 "Reserved_11" 27 "Reserved_12" 28 "Reserved_13" 29 "Reserved_14" 30 "Reserved_15" 31 "Lev_Control_Page_RPAin" ;
VAL_ 516 ParkActiveRearSpoilerReqFrmADD 0 "NoRequest" 1 "Request_Close" 2 "Request_OpenP1" 3 "Request_OpenP2" 4 "Request_OpenP3" 5 "Reserved_1" 6 "Reserved_2" 7 "Reserved_3" ;
VAL_ 516 ParkAtmLiReqFrmADD 0 "NoRequest" 1 "Request_Around" 2 "Request_Red" ;
VAL_ 516 ParkBackMirrorUnfoldReqFrmADD 0 "NoRequest" 1 "Request_Unfold" 2 "Request_Fold" ;
VAL_ 516 ParkCornrLiReqFrmADD 0 "NoRequest" 1 "Request_CornerLightOn" 2 "Reserved" 3 "Reserved" ;
VAL_ 516 ParkDoorLockReqFrmADD 0 "NoRequest" 1 "Request_Unlock" 2 "Request_lock" ;
VAL_ 516 ParkingPushFrmADD 0 "No_Request" 1 "RPA_Park_in" 2 "RPA_Park_out" 3 "RPA_Move" 4 "Reserved" 5 "Reserved" 6 "Reserved" 7 "Reserved" ;
VAL_ 516 ParkLoBeamReqFrmADD 0 "NoRequest" 1 "Request" ;
VAL_ 516 ParkMdlStsFrmADD 0 "NoRequest" 1 "DrivingModel_1" 2 "DrivingModel_2" 3 "DrivingMode_3" 4 "DrivingMode_4" ;
VAL_ 516 ParkTurnLiReqFrmADD 0 "NoRequest" 1 "Leftturnrequest" 2 "Rightturnrequest" 3 "hazardlightrequest" ;
VAL_ 516 ParkWindowReqFrmADD 0 "NoRequest" 1 "Request" ;
VAL_ 516 PASBuzzerWarnMuteIndFrmADD 0 "None" 1 "Mute_info" ;
VAL_ 516 PrkgHornReqFrmADD 0 "No_request" 1 "Request" ;
VAL_ 516 RPAAvailableFrmADD 0 "RPA_available" 1 "RPA_not_available" ;
VAL_ 516 RPADriverOperateIndFrmADD 0 "None" 1 "Reserved_1" 2 "Reserved_2" 3 "Reserved_3" 4 "Reserved_4（active勿用）" 5 "Req_Close_Door_Driver_Parkout" 6 "Req_Close_Door_passenger_Parkout" 7 "Req_Close_Door_LeftRear_RPAParkout" 8 "Req_Close_Door_RightRear_RPAParkout" 9 "Req_Close_Engine_Front_Door_RPAParkout" 10 "Req_Close_Trunk_RPAParkout" 11 "Req_Warning_someone_In_car_RPAParkout" 12 "Searching_Lev_Control_Page_RPAParkout" 13 "Blue_Tooth_Connect_UnStable_RPAParkout" 14 "Reserved_5" 15 "Reserved_6" ;
VAL_ 516 RPAOperateToastFrmADD 0 "None" 1 "Act_More_Trajectory_Mode_RPAin" 2 "Req_Rearview_Mirrors_are_folding_RPAin" 3 "Req_Rearview_Mirrors_are_folding_RPAmove" 4 "Req_RearSpoiler_Closing" 5 "Reserved_1" 6 "Reserved_2" 7 "Reserved_3" 8 "Reserved_4" 9 "Reserved_5" 10 "Reserved_6" 11 "Reserved_7" 12 "Reserved_8" 13 "Reserved_9" 14 "Reserved_10" 15 "Reserved_11" ;
VAL_ 516 RPAQuitReasonIndFrmADD 0 "None" 1 "HDCActvRPAin" 2 "HDCActvRPAMove" 3 "OffroadActvRPAin" 4 "OffroadActvRPAMove" 5 "DrgRacModActv_RPAin" 6 "DrgRacModActv_RPAmove" 7 "DrvModActv_RPAin" 8 "DrvModActv_RPAmove" 9 "DoorOpenTimeOut_RPAout" 10 "FrontLidOpenTimeOut_RPAout" 11 "RearLidOpenTimeOut_Parkout" 12 "Warning_someoneIncarTimeOut_RPAout" 13 "RescueModActv_RPAin" 14 "RescueModActv_RPAmove" 15 "TimeoutNotPressStartButton_RPAout" 16 "WashModActv_RPAin" 17 "WashModActv_RPAmove" 18 "LnchPlusActv_RPAin" 19 "LnchPlusActv_RPAmove" 20 "BatModActv_RPAin" 21 "BatModActv_RPAmove" 22 "SnowModActv_RPAin" 23 "SnowModActv_RPAmove" 24 "BattLow_RPAout" 25 "Blue_Tooth_UnStable_Timeout_RPAout" 26 "APP_RPAout" 27 "ExtremeEcoMode_RPAmove" 28 "JackModActv_RPAin" 29 "JackModActv_RPAmove" 30 "Charg_RPAin" 31 "Charg_RPAmove" 32 "LowPwrMod_RPAout" 33 "ExtremeEcoMode_RPAout" 34 "Charg_RPAout" 35 "ADAS_FcnActvRPAout" 36 "SlopeOutOfLimit_RPAout" 37 "SVSFrontBlkd_RPAout" 38 "SVSRearBlkd_RPAout" 39 "SVSLeftBlkd_RPAout" 40 "SVSRightBlkd_RPAout" 41 "LowPwrMod_RPAmove" 42 "PrivacyMod_RPAin" 43 "PrivacyMod_RPAmove" 44 "ExtmPfmncMod_RPAin" 45 "ExtmPfmncMod_RPAmove" 46 "PrivacyMod_RPAout" 47 "RescueModActv_RPAout" 48 "WashModActv_RPAout" 49 "SVSFrontBlkd_RPAmove" 50 "JackModActv_RPAout" 51 "SVSRearBlkd_RPAmove" 52 "LnchPlusActv_RPAout" 53 "SVSLeftBlkd_RPAmove" 54 "SnowModActv_RPAout" 55 "SVSRightBlkd_RPAmove" 56 "ExtmPfmncMod_RPAout" 57 "BatModActv_RPAout" 58 "DriftModActv_RPAout" 59 "ESCoff_RPAout" 60 "DriftModActv_RPAin" 61 "DriftModActv_RPAmove" 62 "ESCoff_RPAin" 63 "ESCoff_RPAmove" 64 "leavCntrl_PageTimeOut_RPAout" 65 "HDCActvRPAout" 66 "OffroadActvRPAout" 67 "DrvrIntrpt_PressGasPedal_RPAmove" 68 "DrvrIntrpt_PressBrakePedal_RPAmove" 69 "DrgRacModActv_RPAout" 70 "DrvModActv_RPAout" 71 "OtherReason_RPAout" 72 "RC_Not_Available_RPAmove" 73 "RearSpoilerCloseFailed" 74 "System_Failr_RPAout" 75 "HandShakeFail_RPAout" 76 "Drvr_IntrptGear_RPAout" 77 "Drvr_Intrpt_SteerWheel_RPAout" 78 "Drvr_IntrptPressGasPedl_RPAout" 79 "Drvr_IntrptPressBrkPedl_RPAout" 80 "ParkinTotalTimeOut_RPAout" 81 "ObstclinTrajctryTimeOut_RPAout" 82 "CunterAbnormlTimeOut_RPAout" 83 "CRCAbnormal_RPAout" 84 "DrvrIntrpt_RPAout" 85 "CntrlSpeedOverLimit_RPAout" 86 "PathPlanAbnorml_RPAout" 87 "RecovrIntrpt_Times_Overflow_RPAmove" 88 "D/ROverflow_RPAout" 89 "Driver_leavCntrlPage_RPAmove" 90 "resrv1" 91 "resrv2" 92 "resrv3" 93 "resrv4" 94 "resrv5" 95 "resrv6" 96 "resrv7" 97 "resrv8" 98 "resrv9" 99 "resrv10" 100 "resrv11" 101 "resrv12" 102 "resrv13" 103 "resrv14" 104 "resrv15" 105 "resrv16" 106 "resrv17" 107 "resrv18" 108 "resrv19" 109 "resrv20" 110 "resrv21" 111 "resrv22" 112 "resrv23" 113 "resrv24" 114 "resrv25" 115 "resrv26" 116 "resrv27" 117 "resrv28" 118 "resrv29" 119 "resrv30" 120 "resrv31" 121 "resrv32" 122 "resrv33" 123 "resrv34" 124 "resrv35" 125 "resrv36" 126 "resrv37" 127 "resrv38" ;
VAL_ 516 RPAUnableToActiveIndFrmADD 0 "None" 1 "HDC_Active_RPAMove" 2 "Game_Mode_RPAMove" 3 "Limd_Warn_RPAMove" 4 "Carmod_Not_Allowed_RPAMove" 5 "ESC_OFF_RPAmove" 6 "lvl_Adjusting_RPAMove" 7 "Charhing_RPAMove" 8 "Wash_Mode_RPAMove" 9 "Off_Road_Active_RPAMove" 10 "P_Speed_Not_Zero_RPAmove" 11 "Drg_Rac_Mod_Active_RPAmove" 12 "Parking_Active_RPAmove" 13 "Drv_Mod_Active_RPAMove" 14 "Reserved_1" 15 "Reserved_2" ;
VAL_ 516 WeatherStsFrmADD 0 "Unknown" 1 "GoodWeather" 2 "HeavyRain" 3 "HeavySnow" ;
VAL_ 519 BndryValidity1FrmADD 0 "Invalid" 1 "Valid" ;
VAL_ 519 BndryValidity2FrmADD 0 "Invalid" 1 "Valid" ;
VAL_ 519 BndryValidity3FrmADD 0 "Invalid" 1 "Valid" ;
VAL_ 519 BndryValidity4FrmADD 0 "Invalid" 1 "Valid" ;
VAL_ 519 BndryValidity5FrmADD 0 "Invalid" 1 "Valid" ;
VAL_ 519 EnvIllumFrmADD 0 "LitEnvironment" 1 "DarkNight" 2 "Reserved1" 3 "Reserved2" ;
VAL_ 519 TooManyBndryFlagFrmADD 0 "InActive" 1 "Active" ;
VAL_ 519 TooManyVehFlagFrmADD 0 "InActive" 1 "Active" ;
VAL_ 519 TrafSignValidity1FrmADD 0 "Invalid" 1 "Valid" ;
VAL_ 519 TrafSignValidity2FrmADD 0 "Invalid" 1 "Valid" ;
VAL_ 519 VehObjDir1FrmADD 0 "AheadObject" 1 "IncomingObject" ;
VAL_ 519 VehObjDir2FrmADD 0 "AheadObject" 1 "IncomingObject" ;
VAL_ 519 VehObjDir3FrmADD 0 "AheadObject" 1 "IncomingObject" ;
VAL_ 519 VehObjDir4FrmADD 0 "AheadObject" 1 "IncomingObject" ;
VAL_ 519 VehObjDir5FrmADD 0 "AheadObject" 1 "IncomingObject" ;
VAL_ 519 VehObjDir6FrmADD 0 "AheadObject" 1 "IncomingObject" ;
VAL_ 519 VehObjDir7FrmADD 0 "AheadObject" 1 "IncomingObject" ;
VAL_ 519 VehObjDir8FrmADD 0 "AheadObject" 1 "IncomingObject" ;
VAL_ 519 VehObjType1FrmADD 0 "Unknown" 1 "fourwheelVehicle" 2 "MotorcycleOrBicycle" 3 "Reserved" ;
VAL_ 519 VehObjType2FrmADD 0 "Unknown" 1 "fourwheelVehicle" 2 "MotorcycleOrBicycle" 3 "Reserved" ;
VAL_ 519 VehObjType3FrmADD 0 "Unknown" 1 "fourwheelVehicle" 2 "MotorcycleOrBicycle" 3 "Reserved" ;
VAL_ 519 VehObjType4FrmADD 0 "Unknown" 1 "fourwheelVehicle" 2 "MotorcycleOrBicycle" 3 "Reserved" ;
VAL_ 519 VehObjType5FrmADD 0 "Unknown" 1 "fourwheelVehicle" 2 "MotorcycleOrBicycle" 3 "Reserved" ;
VAL_ 519 VehObjType6FrmADD 0 "Unknown" 1 "fourwheelVehicle" 2 "MotorcycleOrBicycle" 3 "Reserved" ;
VAL_ 519 VehObjType7FrmADD 0 "Unknown" 1 "fourwheelVehicle" 2 "MotorcycleOrBicycle" 3 "Reserved" ;
VAL_ 519 VehObjType8FrmADD 0 "Unknown" 1 "fourwheelVehicle" 2 "MotorcycleOrBicycle" 3 "Reserved" ;
VAL_ 519 VehObjValidity1FrmADD 0 "Invalid" 1 "Valid" ;
VAL_ 519 VehObjValidity2FrmADD 0 "Invalid" 1 "Valid" ;
VAL_ 519 VehObjValidity3FrmADD 0 "Invalid" 1 "Valid" ;
VAL_ 519 VehObjValidity4FrmADD 0 "Invalid" 1 "Valid" ;
VAL_ 519 VehObjValidity5FrmADD 0 "Invalid" 1 "Valid" ;
VAL_ 519 VehObjValidity6FrmADD 0 "Invalid" 1 "Valid" ;
VAL_ 519 VehObjValidity7FrmADD 0 "Invalid" 1 "Valid" ;
VAL_ 519 VehObjValidity8FrmADD 0 "Invalid" 1 "Valid" ;
VAL_ 661 ADSRCTBBrkReqFrmADD 0 "no_request" 1 "request" ;
VAL_ 661 BmpTrk1ConfFrmADD 127 "invalid" ;
VAL_ 688 ADDFaultInfoFlag 0 "No_Fault" 1 "Fault" ;
VAL_ 688 ADSLrnUnavlRsnFrmADD 0 "default" 1 "No_reason_req" 2 "account_not_log_in" 3 "not_P_gear" 4 "not_authorized" ;
VAL_ 688 ADSParkSpdSwtStsFrmADD 0 "default" 1 "Standard" 2 "Fast" 3 "Unavailable" 4 "Reserved_1" 5 "Reserved_2" 6 "Reserved_3" 7 "Reserved_4" ;
VAL_ 688 ADSParkSpdSwtUnavlRsnFrmADD 0 "default" 1 "No_reason_req" 2 "not_P_gear" 3 "account_not_log_in" 4 "not_authorized" 5 "not_learned" 6 "privacy_mode" 7 "extreme_eco_mode" 8 "lowpower_mode" 9 "function_active" 10 "other_reasons" 11 "Error_detected" ;
VAL_ 688 APASwtStsFrmADD 0 "default" 1 "Off" 2 "ON" 3 "unavailable" 4 "On_not_support_click" 5 "ON&Active" 6 "Off_not_support_click" ;
VAL_ 688 APASwtUnavlRsnFrmADD 0 "default" 1 "No_reason_req" 2 "not_P_gear" 3 "account_not_log_in" 4 "not_authorized" 5 "not_learned" 6 "privacy_mode" 7 "extreme_eco_mode" 8 "lowpower_mode" 9 "function_active" 10 "other_reasons" 11 "Error_detected" ;
VAL_ 688 AutoVehCustEIPSwtFrmADD 0 "defualt" 1 "Off" 2 "On" 3 "Off_no_click" 4 "On_no_click" ;
VAL_ 688 AutoVehCustEIPSwtRsnFrmADD 0 "default" 1 "No_reason_req" 2 "not_P_gear" 3 "account_not_log_in" ;
VAL_ 688 AutoVehSrvAuthntStsFrmADD 0 "default" 1 "unauthorized" 2 "authorized" 3 "unauthorized_no_click" 4 "authorized_no_click" ;
VAL_ 688 AutoVehSrvAuthntStsRsnFrmADD 0 "default" 1 "No_reason_req" 2 "not_P_gear" 3 "account_not_log_in" ;
VAL_ 688 AvmCamTriggerModReqFrmADD 0 "NoReq" 1 "XcdControlRequest" 2 "AddControlRequest" 3 "Reserved" ;
VAL_ 688 AVPSwtStsFrmADD 0 "default" 1 "Off" 2 "ON" 3 "unavailable" 4 "On_not_support_click" 5 "ON_Active" 6 "Off_not_support_click" 7 "Reserved" ;
VAL_ 688 AVPSwtUnavlRsnFrmADD 0 "default" 1 "No_reason_req" 2 "not_P_gear" 3 "account_not_log_in" 4 "not_authorized" 5 "not_learned" 6 "privacy_mode" 7 "extreme_eco_mode" 8 "lowpower_mode" 9 "function_active" 10 "adas_not_purchased" 11 "Error_detected" 12 "location_limited" 13 "Reserved" 14 "Reserved" 15 "Reserved" ;
VAL_ 688 HPPBckGrLearFrmADD 0 "default" 1 "Off" 2 "ON" 3 "unavailable" 4 "On_not_support_click" 5 "ON_Active" 6 "Off_not_support_click" 7 "Reserved" ;
VAL_ 688 HPPBckGrLearUnavlRsnFrmADD 0 "default" 1 "No_reason_req" 2 "not_P_gear" 3 "account_not_log_in" 4 "not_authorized" 5 "not_learned" 6 "privacy_mode" 7 "extreme_eco_mode" 8 "lowpower_mode" 9 "function_active" 10 "other_reasons" 11 "Error_detected" 12 "location_limited" 13 "Reserved" 14 "Reserved" 15 "Reserved" ;
VAL_ 688 HPPSwtStsFrmADD 0 "default" 1 "Off" 2 "ON" 3 "unavailable" 4 "On_not_support_click" 5 "ON_Active" 6 "Off_not_support_click" 7 "Reserved" ;
VAL_ 688 HPPSwtUnavlRsnFrmADD 0 "default" 1 "No_reason_req" 2 "not_P_gear" 3 "account_not_log_in" 4 "not_authorized" 5 "not_learned" 6 "privacy_mode" 7 "extreme_eco_mode" 8 "lowpower_mode" 9 "function_active" 10 "adas_not_purchased" 11 "Error_detected" 12 "location_limited" 13 "Reserved" 14 "Reserved" 15 "Reserved" ;
VAL_ 688 RPASentryQuit 0 "No_Req" 1 "RPA_Sentry_Quit_Req" ;
VAL_ 693 ParkOutTarDirFrmADD 0 "None" 1 "Left" 2 "Right" ;
VAL_ 693 ParkSlotTarFrmADD 0 "None" 1 "L1" 2 "L2" 3 "L3" 4 "L4" 5 "L5" 6 "L6" 7 "L7" 8 "L8" 9 "R1" 10 "R2" 11 "R3" 12 "R4" 13 "R5" 14 "R6" 15 "R7" 16 "R8" ;
VAL_ 693 PASBuzzerWarnMuteReqFrmADD 0 "No_Request" 1 "Request" ;
VAL_ 693 PASFCBuzzerWarnFrmADD 0 "No_object" 1 "Level1" 2 "Level2" 3 "Level3" 4 "Level4" 5 "Level5" ;
VAL_ 693 PASFLBuzzerWarnFrmADD 0 "No_object" 1 "Level1" 2 "Level2" 3 "Level3" 4 "Level4" 5 "Level5" ;
VAL_ 693 PASFLDistanceLevFrmADD 0 "No_object" 1 "Level1" 2 "Level2" 3 "Level3" 4 "Level4" 5 "Level5" 6 "Level6" ;
VAL_ 693 PASFMLDistanceLevFrmADD 0 "No_object" 1 "Level1" 2 "Level2" 3 "Level3" 4 "Level4" 5 "Level5" 6 "Level6" ;
VAL_ 693 PASFMRDistanceLevFrmADD 0 "No_object" 1 "Level1" 2 "Level2" 3 "Level3" 4 "Level4" 5 "Level5" 6 "Level6" ;
VAL_ 693 PASFRBuzzerWarnFrmADD 0 "No_object" 1 "Level1" 2 "Level2" 3 "Level3" 4 "Level4" 5 "Level5" ;
VAL_ 693 PASFRDistanceLevFrmADD 0 "No_object" 1 "Level1" 2 "Level2" 3 "Level3" 4 "Level4" 5 "Level5" 6 "Level6" ;
VAL_ 693 PASFSLDistanceLevFrmADD 0 "No_object" 1 "Level1" 2 "Level2" 3 "Level3" 4 "Level4" 5 "Level5" 6 "Level6" ;
VAL_ 693 PASFSRDistanceLevFrmADD 0 "No_object" 1 "Level1" 2 "Level2" 3 "Level3" 4 "Level4" 5 "Level5" 6 "Level6" ;
VAL_ 693 PASRLBuzzerWarnFrmADD 0 "No_object" 1 "Level1" 2 "Level2" 3 "Level3" 4 "Level4" 5 "Level5" ;
VAL_ 693 PASRLDistanceLevFrmADD 0 "No_object" 1 "Level1" 2 "Level2" 3 "Level3" 4 "Level4" 5 "Level5" 6 "Level6" ;
VAL_ 693 PASRMLDistanceLevFrmADD 0 "No_object" 1 "Level1" 2 "Level2" 3 "Level3" 4 "Level4" 5 "Level5" 6 "Level6" ;
VAL_ 693 PASRMRDistanceLevFrmADD 0 "No_object" 1 "Level1" 2 "Level2" 3 "Level3" 4 "Level4" 5 "Level5" 6 "Level6" ;
VAL_ 693 PASRRBuzzerWarnFrmADD 0 "No_object" 1 "Level1" 2 "Level2" 3 "Level3" 4 "Level4" 5 "Level5" ;
VAL_ 693 PASRRDistanceLevFrmADD 0 "No_object" 1 "Level1" 2 "Level2" 3 "Level3" 4 "Level4" 5 "Level5" 6 "Level6" ;
VAL_ 693 PASRSLDistanceLevFrmADD 0 "No_object" 1 "Level1" 2 "Level2" 3 "Level3" 4 "Level4" 5 "Level5" 6 "Level6" ;
VAL_ 693 PASRSRDistanceLevFrmADD 0 "No_object" 1 "Level1" 2 "Level2" 3 "Level3" 4 "Level4" 5 "Level5" 6 "Level6" ;
VAL_ 693 PASSDWFLSideDistanceLevFrmADD 0 "No_object" 1 "Level1" 2 "Level2" 3 "Level3" 4 "Level4" 5 "Level5" 6 "Level6" ;
VAL_ 693 PASSDWFMLSideDistanceLevFrmADD 0 "No_object" 1 "Level1" 2 "Level2" 3 "Level3" 4 "Level4" 5 "Level5" 6 "Level6" ;
VAL_ 693 PASSDWFMRSideDistanceLevFrmADD 0 "No_object" 1 "Level1" 2 "Level2" 3 "Level3" 4 "Level4" 5 "Level5" 6 "Level6" ;
VAL_ 693 PASSDWFRSideDistanceLevFrmADD 0 "No_object" 1 "Level1" 2 "Level2" 3 "Level3" 4 "Level4" 5 "Level5" 6 "Level6" ;
VAL_ 693 PASSDWRLSideDistanceLevFrmADD 0 "No_object" 1 "Level1" 2 "Level2" 3 "Level3" 4 "Level4" 5 "Level5" 6 "Level6" ;
VAL_ 693 PASSDWRMLSideDistanceLevFrmADD 0 "No_object" 1 "Level1" 2 "Level2" 3 "Level3" 4 "Level4" 5 "Level5" 6 "Level6" ;
VAL_ 693 PASSDWRMRSideDistanceLevFrmADD 0 "No_object" 1 "Level1" 2 "Level2" 3 "Level3" 4 "Level4" 5 "Level5" 6 "Level6" ;
VAL_ 693 PASSDWRRSideDistanceLevFrmADD 0 "No_object" 1 "Level1" 2 "Level2" 3 "Level3" 4 "Level4" 5 "Level5" 6 "Level6" ;
VAL_ 775 ParkProgressSigLFPosXFrmADD 65535 "Invalid" ;
VAL_ 775 ParkProgressSigLFPosYFrmADD 65535 "Invalid" ;
VAL_ 775 ParkProgressSigLRPosXFrmADD 65535 "Invalid" ;
VAL_ 775 ParkProgressSigLRPosYFrmADD 65535 "Invalid" ;
VAL_ 775 ParkProgressSigRFPosXFrmADD 65535 "Invalid" ;
VAL_ 775 ParkProgressSigRFPosYFrmADD 65535 "Invalid" ;
VAL_ 775 ParkProgressSigRRPosXFrmADD 65535 "Invalid" ;
VAL_ 775 ParkProgressSigRRPosYFrmADD 65535 "Invalid" ;
VAL_ 775 PASSubFunAvaiFrmADD 0 "Available" 1 "Front_Not_Available_Rear_Available" 2 "Rear_Not_Available_Front__Available" 3 "Only_SDW_Not_Available" 4 "Not_Available" 5 "PAS_Initialization" 6 "Lowpower_Mode" 7 "Other_Reasons" ;
VAL_ 775 PASWorkingModeFrmADD 0 "Off" 1 "Standby" 2 "Active" 3 "SystemFailure" ;
VAL_ 873 LowPwrReqFrLdrFrmADD 0 "default" 1 "exit_request" 2 "enter_requet" ;
VAL_ 873 LowPwrReqFrRdrFrmADD 0 "default" 1 "exit_request" 2 "enter_requet" ;
VAL_ 239 XAccelStaFrmADD 0 "available" 1 "abnormal" 2 "outrange" 3 "CRC_check_failed" ;
VAL_ 239 XAngRateStaFrmADD 0 "available" 1 "abnormal" 2 "outrange" 3 "CRC_check_failed" ;
VAL_ 239 YAccelStaFrmADD 0 "available" 1 "abnormal" 2 "outrange" 3 "CRC_check_failed" ;
VAL_ 239 YAngRateStaFrmADD 0 "available" 1 "abnormal" 2 "outrange" 3 "CRC_check_failed" ;
VAL_ 239 ZAccelStaFrmADD 0 "available" 1 "abnormal" 2 "outrange" 3 "CRC_check_failed" ;
VAL_ 239 ZAngRateStaFrmADD 0 "available" 1 "abnormal" 2 "outrange" 3 "CRC_check_failed" ;
VAL_ 1331 ADDChassisBkpActiveWakeup 0 "passive_wakeup" 1 "active_Wakeup" ;
VAL_ 1331 ADDChassisBkpRepeatMsgReq 0 "Repeat_Message_State_not_requested" 1 "Repeat_Message_State_requested" ;
VAL_ 1331 ADDChassisBkpRepeatMsgSt 0 "Not_in_Repeat_Message_State" 1 "In_Repeat_Message_State" ;
VAL_ 1326 ADDChassisBkpActiveWakeup1 0 "passive_wakeup" 1 "active_Wakeup" ;
VAL_ 1326 ADDChassisBkpRepeatMsgReq1 0 "Repeat_Message_State_not_requested" 1 "Repeat_Message_State_requested" ;
VAL_ 1326 ADDChassisBkpRepeatMsgSt1 0 "Not_in_Repeat_Message_State" 1 "In_Repeat_Message_State" ;
VAL_ 336 ABAActv 0 "NotActive" 1 "Active" ;
VAL_ 336 ABAAvl 0 "NotAvailable" 1 "Available" ;
VAL_ 336 APBAplAvlBCP 0 "Available" 1 "NotAvailable_fault" 2 "NotAvailable_SpeedLimit" ;
VAL_ 336 APBRelAvlBCP 0 "Available" 1 "NotAvailable_fault" 2 "NotAvailable_withoutpedal" 3 "NotAvailable_withcharging" ;
VAL_ 336 APBStsBkp 0 "Released" 1 "Applied" 2 "Releasing" 3 "Applying" 4 "Undefined" ;
VAL_ 336 BCPBrkLiIllmnReq 0 "NoRequest" 1 "Request" ;
VAL_ 336 BCPBrkSysWarnText 0 "NoWarning" 1 "the_brake_system_fault" 2 "Please_check_because_the_brake_system_leakage" 3 "Overheat_of_brake_system" 4 "reserved" 5 "reserved" 6 "reserved" 7 "reserved" ;
VAL_ 336 BCPFaultInfoFlag 0 "No_Fault" 1 "Fault" ;
VAL_ 336 BCPKeepAwakeReq 0 "No_request" 1 "Request" ;
VAL_ 336 BCPMstCylPVld 0 "NotInitialized" 1 "Normal" 2 "Faulty" ;
VAL_ 336 BCPSimulatorPVld 0 "NotInitialized" 1 "Normal" 2 "Faulty" ;
VAL_ 336 BCPSysSts 0 "Off" 1 "DegradedPedalFeeling" 2 "On" ;
VAL_ 336 BrkFldWarn 0 "NoWarning" 1 "Warning" ;
VAL_ 336 BrkFldWarnVld 0 "Invalid" 1 "Valid" ;
VAL_ 336 BrkPedlAppld 0 "NotApplied" 1 "Applied" ;
VAL_ 336 BrkPedlAppldVld 0 "BrkPedlAppld_NotInitialized" 1 "BrkPedlAppld_Normal" 2 "BrkPedlAppld_Faulty" ;
VAL_ 336 BrkPedlPerctVld 0 "Invalid" 1 "Valid" ;
VAL_ 336 HBAActv 0 "NotActive" 1 "Active" ;
VAL_ 336 HBAAvl 0 "NotAvailable" 1 "Available" ;
VAL_ 336 HBBActv 0 "NotActive" 1 "Active" ;
VAL_ 336 InpRodStkVld 0 "Invalid" 1 "Valid" ;
VAL_ 340 APBAplAvlBCPFusion 0 "Available" 1 "NotAvailable_fault" 2 "NotAvailable_SpeedLimit" ;
VAL_ 340 APBRelAvlBCPFusion 0 "Available" 1 "NotAvailable_fault" 2 "NotAvailable_withoutpedal" 3 "NotAvailable_withcharging" ;
VAL_ 340 APBStsBkpFusion 0 "Released" 1 "Applied" 2 "Releasing" 3 "Applying" 4 "Undefined" ;
VAL_ 340 BCPBrkSysActCircNoP 0 "False" 1 "True" ;
VAL_ 340 BCPBrkSysFTarDrvrVld 0 "NotInitialized" 1 "Normal" 2 "ExternalBrakeRequest" 3 "Faulty" ;
VAL_ 340 BrkSysActCircNoP 0 "False" 1 "True" ;
VAL_ 340 BrkSysBCPDiagActv 0 "NotActive" 1 "Active" ;
VAL_ 340 BrkSysHBCReq 0 "NoRequest" 1 "Request" ;
VAL_ 340 BrkSysPRntVld 0 "PRnt_NotInitialized" 1 "PRnt_Faulty" 2 "PRnt_Normal" ;
VAL_ 340 RPBActrStSec 0 "Applied" 1 "Released" 2 "Applying" 3 "Releasing" 4 "Unknown" 5 "HoldApplied" 6 "CompletelyReleased" 7 "HapPrepared" ;
VAL_ 344 BCPKeepAwakeReqBkp 0 "NoRequest" 1 "Request" ;
VAL_ 487 BCPDrvBrakeActType 0 "Dynamic" 1 "Standard" 2 "Comfort_Low" 3 "Comfort_Medium" 4 "Comfort_Max" ;
VAL_ 487 BrkSysAPBBkp2MainSafeLimCom2 0 "NotBlocked" 1 "Blocked" 2 "StandstillDetected" ;
VAL_ 487 BrkSysAPBParkBrkReqBkp2MainCom2 0 "NotInitialized" 1 "NoRequest" 2 "ReleaseBrake" 3 "LockBrake" 4 "EmergencyParkApply" ;
VAL_ 487 BrkSysAPCBkp2MainStCom2 0 "NotAvailable_temporary" 1 "NotAvailable_NotReleased" 2 "NotAvailable_permanent" 3 "NotActivated_FullAvailable" 4 "Activation_Preparation" 5 "Activation_Pending" 6 "Activation_PendingRedundancyLost" 7 "Activation_PendingFailOperation" 8 "Activated_FullAvailable" 9 "Activated_FailOperation" 10 "Activated_RedundancyLost" 11 "Deactivation_pending" ;
VAL_ 487 BrkSysBCPLdmBrkActActr 0 "Actuator_PrimaryOrSecondary" 1 "Actuator_Primary" 2 "Actuator_Secondary" 3 "Actuator_PrimOrSeconOrBackup" ;
VAL_ 487 BrkSysBCPLdmBrkActAxle 0 "Axle_DontCare" 1 "Axle_Front" 2 "Axle_Rear" ;
VAL_ 487 BrkSysBCPLdmBrkActGenr 0 "Generaator_No" 1 "Generator_Yes" 2 "Generator_NoIncrease" ;
VAL_ 487 BrkSysBCPLdmBrkActTyp 0 "ActType_Dynamic" 1 "ActType_Standard" 2 "ActType_Comfort_Low" 3 "ActType_Comfort_Medium" 4 "ActType_Comfort_Max" ;
VAL_ 487 BrkSysBCPLdmSysModReq 0 "SMM_INIT" 1 "SMM_OFF" 2 "SMM_NET_OFF" 3 "SMM_NET_ON" 4 "SMM_NORMAAL" ;
VAL_ 487 BrkSysBrkPedlAppld 0 "NotApplied" 1 "Applied" ;
VAL_ 487 BrkSysBrkPedlAppldVld 0 "BrkPedlAppld_NotInitialized" 1 "BrkPedlAppld_Normal" 2 "BrkPedlAppld_Faulty" ;
VAL_ 487 BrkSysEnaActvCtrlByDrvr 0 "NotEnable" 1 "Enable" ;
VAL_ 487 BrkSysFTarDrvrVld 0 "NotInitialized" 1 "Normal" 2 "ExternalBrakeRequest" 3 "Faulty" ;
VAL_ 487 BrkSysLdmFTarBrkBCPVld 0 "NotInitialized" 1 "Normal" 2 "Faulty" ;
VAL_ 487 BrkSysLdmGlbStsAct 0 "LdmGlbArb_NotInitialized" 1 "LdmGlbArb_Faulty" 2 "LdmGlbArb_Normal" ;
VAL_ 487 BrkSysParkBrkReq 0 "LdmReqApb_NotInitialized" 1 "LdmReqApb_NoRequest" 2 "LdmReqApb_Release" 3 "LdmReqApb_Lock" 4 "LdmReqApb_EmergencyParkApply" ;
VAL_ 487 BrkSysPRednPotnlVld 0 "NotInitialized" 1 "Normal" 2 "Faulty" ;
VAL_ 487 BrkSysWarnLampReq 0 "NoLamp" 1 "YellowLamp" 2 "RedLamp" ;
VAL_ 487 RecuSuppressEna 0 "false" 1 "true" ;
VAL_ 487 RPBHydPSpprtReq 0 "None" 1 "NormalPressureGradient" 2 "MaximumPressureGradient" ;
VAL_ 1318 BCPChassisBkpActiveWakeup 0 "passive_wakeup" 1 "active_Wakeup" ;
VAL_ 1318 BCPChassisBkpRepeatMsgReq 0 "Repeat_Message_State_not_requested" 1 "Repeat_Message_State_requested" ;
VAL_ 1318 BCPChassisBkpRepeatMsgSt 0 "Not_in_Repeat_Message_State" 1 "In_Repeat_Message_State" ;
VAL_ 337 ABPActv 0 "NotActive" 1 "Active" ;
VAL_ 337 ABPAvl 0 "NotAvailable" 1 "Available" ;
VAL_ 337 ABSActv 0 "NotActive" 1 "Active" ;
VAL_ 337 ABSErrDetd 0 "Error" 1 "NoError" ;
VAL_ 337 AEBActv 0 "NotActive" 1 "Active" ;
VAL_ 337 AEBAvl 0 "NotAvailable" 1 "Available" ;
VAL_ 337 APBAplAvlBCS 0 "Available" 1 "NotAvailable_fault" 2 "NotAvailable_SpeedLimit" ;
VAL_ 337 APBErrDetd 0 "NotInit" 1 "Normal" 2 "Faulty" ;
VAL_ 337 APBRelAvlBCS 0 "Available" 1 "NotAvailable_fault" 2 "NotAvailable_withoutpedal" 3 "NotAvailable_withcharging" ;
VAL_ 337 APBSts 0 "Released" 1 "Applied" 2 "Releasing" 3 "Applying" 4 "Undefined" ;
VAL_ 337 APBTxtDip 0 "default" 1 "Slope_out_of_specified_limit" 2 "Left_Parking_brake_fail" 3 "Right_Parking_brake_fail" 4 "Hot_parking_brake_system" 5 "Use_APB_Button_to_releaseandappl" 6 "Parking_brake_cannot_hold_vehicle" 7 "Parking_brake_roller_bench_test_mode" 8 "Left_parking_brake_released" 9 "Left_parking_brake_Applied" 10 "reserved" 11 "reserved" 12 "reserved" 13 "reserved" ;
VAL_ 337 AVHAvl 0 "NotAvailable" 1 "Available" ;
VAL_ 337 AVHSts 0 "Off" 1 "Standby" 2 "Active" ;
VAL_ 337 AWBActv 0 "NotActive" 1 "Active" ;
VAL_ 337 AWBAvl 0 "NotAvailable" 1 "Available" ;
VAL_ 337 BCSBrkSysWarnText 0 "NoWarning" 1 "the_brake_system_fault" 2 "Please_check_because_the_brake_system_leakage" 3 "Overheat_of_brake_system" 4 "reserved" 5 "reserved" 6 "reserved" 7 "reserved" ;
VAL_ 337 BCSFaultInfoFlag 0 "No_Fault" 1 "Fault" ;
VAL_ 337 BCSKeepAwakeReq 0 "No_request" 1 "Request" ;
VAL_ 337 BrkLiIllmnReq 0 "NoRequest" 1 "Request" ;
VAL_ 337 BrkSysWarnLamp 0 "NoRequest" 1 "YellowLampt" 2 "RedLamp" ;
VAL_ 337 CDPActv 0 "NotActive" 1 "Active" ;
VAL_ 337 CDPAvl 0 "NotAvailable" 1 "Available" ;
VAL_ 337 CSTSts 0 "Off" 1 "Standby" 2 "Active" 3 "Failure" ;
VAL_ 337 DSTActv 0 "NotActive" 1 "Active" ;
VAL_ 337 EBAActv 0 "NotActive" 1 "Active" ;
VAL_ 337 EBDActv 0 "NotActive" 1 "Active" ;
VAL_ 337 EBDErrDetd 0 "Error" 1 "NoError" ;
VAL_ 337 EmgyBrkLiReq 0 "NoRequest" 1 "Request" ;
VAL_ 337 ESCErrDetd 0 "Error" 1 "NoError" ;
VAL_ 337 ESCIntvLamp 0 "NotActive" 1 "Active" ;
VAL_ 337 ESCPataLamp 0 "NoRequest" 1 "Level1Request" 2 "Level2Request" ;
VAL_ 337 ESCSwitchAvl 0 "Available" 1 "Disabled_EscError" 2 "Disabled_EscActvMode" 3 "Disabled_TestDrvMode" 4 "Disabled_ADASMode" 5 "Disabled_NotLogin" 6 "Disabled_NotAuthorized" 7 "Disabled_ExamFailed" ;
VAL_ 337 HBBSts 0 "HBBNormalMode" 1 "HBBFailedBoost" 2 "HBBFailedBoostBackup" 3 "HBBDisabled" ;
VAL_ 337 HBCActv 0 "NotActive" 1 "Active" ;
VAL_ 337 HDCAvl 0 "NotAvailable" 1 "Available" ;
VAL_ 337 HDCCtrlSts 0 "Off" 1 "Standby" 2 "Active" 3 "Reserved" ;
VAL_ 337 HDCUnAvlRsn 0 "Available" 1 "NotAvailable_ESCError" 2 "NotAvailable_TooHighSpd" 3 "NotAvailable_ACCActive" 4 "NotAvailable_TrlrMode" 5 "NotAvailable_WashMode" 6 "NotAvailable_JackMode" ;
VAL_ 337 HHCActv 0 "NotActive" 1 "Active" ;
VAL_ 337 HHCAvl 0 "NotAvailable" 1 "Available" ;
VAL_ 337 HRBActv 0 "NotActive" 1 "Active" ;
VAL_ 337 HRBAvl 0 "NotAvailable" 1 "Available" ;
VAL_ 337 HydBrkFExist 0 "NotExist" 1 "Exist" ;
VAL_ 337 MstCylPVld 0 "Invalid" 1 "Valid" ;
VAL_ 337 SCMActv 0 "NotActive" 1 "Active" ;
VAL_ 337 SCMAvl 0 "NotAvailable" 1 "Available" ;
VAL_ 337 TCSActv 0 "NotActive" 1 "Active" ;
VAL_ 337 VDCActv 0 "NotActive" 1 "Active" ;
VAL_ 337 VehStandStillIndcr 0 "NotStandstill" 1 "Standstill" ;
VAL_ 337 VehStandStillIndcrVld 0 "Invalid" 1 "Valid" ;
VAL_ 338 APAActrAvl 0 "NotAvailable" 1 "Available" ;
VAL_ 338 APCActvVehHld 0 "False" 1 "True" ;
VAL_ 338 APCDrvrBrkOvrdFlg 0 "False" 1 "True" ;
VAL_ 338 APCFailrSts 0 "NoError" 1 "APC1_APA_DriverNotPresent" 2 "APC24_RPAAVP_TooHighSlope" 3 "TooHighSpeed" 4 "UnexpectEPBApply" 5 "VehicleBlock" 6 "APC24_RPAAVP_TriggerWithoutSecure" 7 "Error" 8 "Reserved" ;
VAL_ 338 APCSts 0 "Standby" 1 "Active_APA" 2 "Active_RPA" 3 "Active_AVP" 4 "Active_DynamicAVP" ;
VAL_ 338 BCSLgtCtrlPtTarTqEna 0 "False" 1 "True" ;
VAL_ 338 CstRgnBlendSts 0 "Off" 1 "DTC_Fault" 2 "LFC_Fault" 3 "Normal" ;
VAL_ 338 DrgTqCtrlActvFA 0 "NotActive" 1 "Active" ;
VAL_ 338 DrgTqCtrlActvRA 0 "NotActive" 1 "Active" ;
VAL_ 338 PtTqRednActvFA 0 "NotActive" 1 "Active" ;
VAL_ 338 PtTqRednActvRA 0 "NotActive" 1 "Active" ;
VAL_ 338 RPAAVPActrAvl 0 "Not_Available" 1 "Available" 2 "Test_Pending" ;
VAL_ 338 TarRecuTqReqSts 0 "NotIntialized" 1 "Normal" 2 "Faulty" ;
VAL_ 354 APBAplAvlBCSFusion 0 "Available" 1 "NotAvailable_fault" 2 "NotAvailable_SpeedLimit" ;
VAL_ 354 APBRelAvlBCSFusion 0 "Available" 1 "NotAvailable_fault" 2 "NotAvailable_withoutpedal" 3 "NotAvailable_withcharging" ;
VAL_ 354 APBStsFusion 0 "Released" 1 "Applied" 2 "Releasing" 3 "Applying" 4 "Undefined" ;
VAL_ 354 BCSKeepAwakeReqBkp 0 "NoRequest" 1 "Request" ;
VAL_ 354 BrkSysAxRoadSlopeVld 0 "NotReliable" 1 "OnlyAxReliable" 2 "FullReliable" ;
VAL_ 354 BrkSysBCSDiagActv 0 "NotActive" 1 "Active" ;
VAL_ 354 BrkSysSkidDrv 0 "NotDetected" 1 "Detected" ;
VAL_ 354 BrkSysSkidYawRate 0 "NotDetected" 1 "Detected" ;
VAL_ 354 RPBActrStPrim 0 "Applied" 1 "Released" 2 "Applying" 3 "Releasing" 4 "Unknown" 5 "HoldApplied" 6 "CompletelyReleased" 7 "HapPrepared" ;
VAL_ 354 RPBAxSt 0 "SIG_IN_SPEC" 1 "SIGNOTAVAIL" 2 "SIGFAIL" 3 "Reserved" ;
VAL_ 354 RPBIntReqPrim 0 "ApbReqSource_NoRequest" 1 "ApbReqSource_RollerTestBench" 2 "ApbReqSource_EmergencyApply" 3 "ApbReqSource_Button_Apply" 4 "ApbReqSource_Button_Release" 5 "ApbReqSource_Button_DclBrkMech" 6 "ApbReqSource_DriveOff_Release" 7 "ApbReqSource_AutoApply" 8 "ApbReqSource_ExtFunction_Apply" 9 "ApbReqSource_ExtFunction_Release" 10 "ApbReqSource_BrkPadWearAdj" 11 "ApbReqSource_HapPreparation" 12 "ApbReqSource_ApbBackup" 13 "ApbReqSource_Reserved" ;
VAL_ 354 RPBPrkgBtnPsd 0 "NoRequest" 1 "Request" ;
VAL_ 354 RPBPrkgBtnPsdVld 0 "Invalid" 1 "Valid" ;
VAL_ 354 VehSpdBkpVld 0 "Invalid" 1 "Valid" ;
VAL_ 179 BCSActrActvForADC 0 "ADC_Normal" 1 "ADC_Active_L12" 2 "ADC_Active_L123" ;
VAL_ 179 BCSActrAvlStsForADC 0 "ADC_NotAvailable_L123" 1 "ADC_NotAvailableBySituation_L123" 2 "ADC_AvailableL12_NotAvailableL3" 3 "ADC_AvailableL12_NotAvailableBySituationL3" 4 "ADC_AvailableWithFault_L3" 5 "ADC_AvailableWithSituationIssue_L3" 6 "ADC_Available_L123" ;
VAL_ 179 BCSActrAvlStsForADCL3 0 "ADC_NotAvailable_L3" 1 "ADC_NotAvailableBySituation_L3" 2 "ADC_AvailableWithFault_L3" 3 "ADC_AvailableWithSituationIssue_L3" 4 "ADC_Available_L3_No_failure" ;
VAL_ 179 BCSActrRampOffStsForADC 0 "ADC_Normal" 1 "ADC_SuspendByOtherBrake" 2 "ADC_SuspendByDriverPropulsion" 3 "ADC_RampOffByDriverBrake" ;
VAL_ 179 BCSActrVldForADC 0 "Invalid" 1 "Valid" ;
VAL_ 179 VehSpdVld 0 "Invalid" 1 "Valid" ;
VAL_ 179 WhlDirFrntLe 0 "Undefined" 1 "Standstill" 2 "Forward" 3 "Backward" ;
VAL_ 179 WhlDirFrntLeVld 0 "Invalid" 1 "Valid" ;
VAL_ 179 WhlDirFrntRi 0 "Undefined" 1 "Standstill" 2 "Forward" 3 "Backward" ;
VAL_ 179 WhlDirFrntRiVld 0 "Invalid" 1 "Valid" ;
VAL_ 179 WhlDirReLe 0 "Undefined" 1 "Standstill" 2 "Forward" 3 "Backward" ;
VAL_ 179 WhlDirReLeVld 0 "Invalid" 1 "Valid" ;
VAL_ 179 WhlDirReRi 0 "Undefined" 1 "Standstill" 2 "Forward" 3 "Backward" ;
VAL_ 179 WhlDirReRiVld 0 "Invalid" 1 "Valid" ;
VAL_ 179 WhlSpdEdgeFrntLeVld 0 "Invalid" 1 "Valid" ;
VAL_ 179 WhlSpdEdgeFrntRiVld 0 "Invalid" 1 "Valid" ;
VAL_ 179 WhlSpdEdgeReLeVld 0 "Invalid" 1 "Valid" ;
VAL_ 179 WhlSpdEdgeReRiVld 0 "Invalid" 1 "Valid" ;
VAL_ 179 WhlSpdFrntLeVld 0 "Invalid" 1 "Valid" ;
VAL_ 179 WhlSpdFrntRiVld 0 "Invalid" 1 "Valid" ;
VAL_ 179 WhlSpdReLeVld 0 "Invalid" 1 "Valid" ;
VAL_ 179 WhlSpdReRiVld 0 "Invalid" 1 "Valid" ;
SIG_GROUP_ 379 ParkGearReqSigGrp 1 : ParkGearReqEnaFrmADD ParkGearReqFrmADD ParkGearReqSigGrpChks ParkGearReqSigGrpCntr RPAHVOnReqFrmADD RPAPrkinRecdFrmADD;
SIG_GROUP_ 399 HPPAVPSteerReqBkpSigGrp 1 : HPPAVPRecoverIndCtrlBkp HPPAVPSteerReqBkpSigGrpChks HPPAVPSteerReqBkpSigGrpCntr HPPAVPSteerWhlAglReqValBkp HPPAVPSteerWhlCtrlReqStsBkp;
SIG_GROUP_ 493 ParkCtrlAirSuspSigGrp 1 : ParkAirSuspReqFrmADD ParkCtrlAirSuspSigGrpChks ParkCtrlAirSuspSigGrpCntr;
SIG_GROUP_ 512 ADSFctStsSigGrp 1 : ADDBSDLCAStsFrmADD ADSAEBStsFrmADD ADSAEBTarDirFrmADD ADSDOWStsFrmADD ADSELKStsFrmADD ADSESSStsFrmADD ADSFctStsSigGrpChks ADSFctStsSigGrpCntr ADSFCWStsFrmADD ADSLDPStsFrmADD ADSLDWStsFrmADD ADSRCTAStsFrmADD ADSRCTBStsFrmADD ADSRCWStsFrmADD;
SIG_GROUP_ 512 ADSGearReqSigGrp 1 : ADSGearReqSigGrpChks ADSGearReqSigGrpCntr DrvGearReqFrmADD DrvGearReqVldFrmADD;
SIG_GROUP_ 512 ADSWarnRemd2SigGrp 1 : ADSLiReqFrmADD AutoDrvLaneChgStsFrmADD DrvHUDDspFrmADD DrvLaneChgStsFrmADD DrvNOAExtLgtDstFrmADD DrvNOAQutLgtDstFrmADD DrvPltSysStsFrmADD DrvrSeldDstLvlFrmADD DrvTurnLiReqFrmADD IndcrCancelReqFrmADD NOASysStsFrmADD UserFbReqFrmADD;
SIG_GROUP_ 512 ADSWarnSigGrp 1 : ADSAEBWarnReqFrmADD ADSBSDLCAAudioWarnReqFrmADD ADSBSDLCAWarnReqLeFrmADD ADSBSDLCAWarnReqRiFrmADD ADSBSDLightWarningLeReqFrmADD ADSBSDLightWarningRiReqFrmADD ADSDOWWarnReqFrLeFrmADD ADSDOWWarnReqFrRiFrmADD ADSDOWWarnReqReLeFrmADD ADSDOWWarnReqReRiFrmADD ADSESSWarnReqFrmADD ADSFCWReqFrmADD ADSLDPHandOffExitFrmADD ADSLDPHandOffWarningFrmADD ADSLDPWarnReqLeFrmADD ADSLDPWarnReqRiFrmADD ADSLDWWarnLeReqFrmADD ADSLDWWarnRiReqFrmADD ADSRCTAWarnReqLeFrmADD ADSRCTAWarnReqRiFrmADD ADSRCTBWarnReqLeFrmADD ADSRCTBWarnReqRiFrmADD ADSRCWWarnReqFrmADD ADSVcCtrlArbFrmADD ADSWarnSigGrpChks ADSWarnSigGrpCntr DrvAtmLiReqFrmADD DrvSysWarnFrmADD TSASignQlyFrmADD TSASignTypeFrmADD TSASpdLimitFrmADD TSASpdLimitUnitFrmADD;
SIG_GROUP_ 512 ADSwtStsSigGrp2 1 : AdsLearnSwtStsFrmADD AdsLearnSwtUnavlRsnFrmADD AdsModSwtStsFrmADD AdsNOAOddSwtStsFrmADD AdsNOAOddSwtUnavlRsnFrmADD AdsTrfcLiCtrlSwtStsFrmADD AdsVehDetourSwtStsFrmADD ADSwtStsSigGrp2Chks ADSwtStsSigGrp2Cntr;
SIG_GROUP_ 512 AEBtoIDPSigGrp 1 : AEBTarObjClassFrmADD AEBTarObjTTIFrmADD AEBtoIDPFrmADDChks AEBtoIDPFrmADDCntr;
SIG_GROUP_ 512 AVMCamVideoChainStsGrp 1 : AVMCamVideoChainSts AVMCamVideoChainStsChks AVMCamVideoChainStsCntr;
SIG_GROUP_ 513 AVPHPPStatusSigGrp 1 : ADSAPPUnableOpenRsnFrmADD ADSAVPStsFrmADD ADSHPPStsFrmADD AVPHPPStatusSigGrpChks AVPHPPStatusSigGrpCntr HPPActiveSubStsFrmADD HPPAlrtWarnFrmADD HPPDriverOperateDialogFrmADD HPPDriverOperateInd2FrmADD HPPDriverOperateIndFrmADD HPPInfotipFrmADD HPPLearnSubStsFrmADD HPPQuitIndFrmADD HPPRecoverIndFrmADD HPPRouteInd2FrmADD HPPRouteIndFrmADD HPPUnableToActiveIndFrmADD;
SIG_GROUP_ 513 DVRStsSigGrp 1 : F120DVRStsFrmADD F30DVRStsFrmADD ReDVRStsFrmADD SLFDVRStsFrmADD SLRDVRStsFrmADD SRFDVRStsFrmADD SRRDVRStsFrmADD;
SIG_GROUP_ 513 HPPToSRSigGrp 1 : HPPBakMapDfltParkSlotDispFrmADD HPPPlayBackPushFrmADD HPPRecoverButtonStsFrmADD HPPRouteManageStsFrmADD HPPToSRSigGrpChks HPPToSRSigGrpCntr HPPVehInParkSlotFrmADD;
SIG_GROUP_ 513 ParkIcnStsSigGrp 1 : APAIcnDispStsFrmADD AVPIcnDispStsFrmADD HPPIcnDispStsFrmADD ParkIcnStsSigGrpChks ParkIcnStsSigGrpCntr PrkSteerWhlBtnLi;
SIG_GROUP_ 513 ParkVCstatusSigGrp 1 : APAVcFbFrmADD APAVcQuitAvlFrmADD APAVcStsFrmADD AVMOpnReqFrmADD HPPLrnVcFbFrmADD ParkVCstatusSigGrpChks ParkVCstatusSigGrpCntr ParkVicShdFrmADD;
SIG_GROUP_ 513 SnmDetResSigGrp 1 : SnmDetInfoFrmADD SnmDetResFrmADD SnmF120CamDetResFrmADD SnmReCamDetResFrmADD SnmSLFCamDetResFrmADD SnmSLRCamDetResFrmADD SnmSRFCamDetResFrmADD SnmSRRCamDetResFrmADD;
SIG_GROUP_ 516 APARPAstatusSigGrp 1 : APAAlrtWarnFrmADD APARPAActiveSubFunFrmADD APARPADriverOperateInd2FrmADD APARPADriverOperateIndFrmADD APARPAQuitReasonIndFrmADD APARPARecoverIndFrmADD APARPAstatusFrmADD APARPAstatusSigGrpChks APARPAstatusSigGrpCntr APARPAUnableToActiveIndFrmADD ParkProgressSigReDistFrmADD PRAMoveSigReDistFrmADD;
SIG_GROUP_ 516 ParkLightReqSigGrp 1 : AVPCharLidCtrlFrmADD ParkAtmLiReqFrmADD ParkBackMirrorUnfoldReqFrmADD ParkDoorLockReqFrmADD ParkLightReqSigGrpChks ParkLightReqSigGrpCntr ParkLoBeamReqFrmADD ParkTurnLiReqFrmADD ParkWindowReqFrmADD PrkgHornReqFrmADD RPAAvailableFrmADD;
SIG_GROUP_ 661 ADSRCTBBrkSigGrp 1 : ADSRCTBBrkReqFrmADD ADSRCTBBrkSigGrpChks ADSRCTBBrkSigGrpCntr ADSRCTBTarDecelFrmADD;
SIG_GROUP_ 688 ParkSwtStsSigGrp 1 : APASwtStsFrmADD APASwtUnavlRsnFrmADD AVPSwtStsFrmADD AVPSwtUnavlRsnFrmADD HPPBckGrLearFrmADD HPPBckGrLearUnavlRsnFrmADD HPPSwtStsFrmADD HPPSwtUnavlRsnFrmADD ParkSwtStsSigGrpChks ParkSwtStsSigGrpCntr;
SIG_GROUP_ 693 ParkTarPosnSigGrp 1 : ParkOutTarDirFrmADD ParkSlotTarFrmADD ParkTarPosnSigGrpChks ParkTarPosnSigGrpCntr;
SIG_GROUP_ 693 PASDistanceLevSigGrp 1 : PASDistanceLevSigGrpChks PASDistanceLevSigGrpCntr PASFLDistanceLevFrmADD PASFMLDistanceLevFrmADD PASFMRDistanceLevFrmADD PASFRDistanceLevFrmADD PASFSLDistanceLevFrmADD PASFSRDistanceLevFrmADD PASRLDistanceLevFrmADD PASRMLDistanceLevFrmADD PASRMRDistanceLevFrmADD PASRRDistanceLevFrmADD PASRSLDistanceLevFrmADD PASRSRDistanceLevFrmADD PASSDWFLSideDistanceLevFrmADD PASSDWFMLSideDistanceLevFrmADD PASSDWFMRSideDistanceLevFrmADD PASSDWFRSideDistanceLevFrmADD PASSDWRLSideDistanceLevFrmADD PASSDWRMLSideDistanceLevFrmADD PASSDWRMRSideDistanceLevFrmADD PASSDWRRSideDistanceLevFrmADD;
SIG_GROUP_ 693 PASDistanceSystemGrp 1 : PASDistanceSystemGrpChks PASDistanceSystemGrpCntr PASFLDistanceFrmADD PASFMLDistanceFrmADD PASFMRDistanceFrmADD PASFRDistanceFrmADD PASFSLDistanceFrmADD PASFSRDistanceFrmADD PASRLDistanceFrmADD PASRMLDistanceFrmADD PASRMRDistanceFrmADD PASRRDistanceFrmADD PASRSLDistanceFrmADD PASRSRDistanceFrmADD PASSDWFLSideDistanceFrmADD PASSDWFMLSideDistanceFrmADD PASSDWFMRSideDistanceFrmADD PASSDWFRSideDistanceFrmADD PASSDWRLSideDistanceFrmADD PASSDWRMLSideDistanceFrmADD PASSDWRMRSideDistanceFrmADD PASSDWRRSideDistanceFrmADD;
SIG_GROUP_ 693 PASFLBuzzerSigGrp 1 : PASBuzzerWarnMuteReqFrmADD PASFCBuzzerWarnFrmADD PASFLBuzzerSigGrpChks PASFLBuzzerSigGrpCntr PASFLBuzzerWarnFrmADD PASFRBuzzerWarnFrmADD PASRLBuzzerWarnFrmADD PASRRBuzzerWarnFrmADD;
SIG_GROUP_ 775 PASProgressSigGrp 1 : ParkProgressSigLFPosXFrmADD ParkProgressSigLFPosYFrmADD ParkProgressSigLRPosXFrmADD ParkProgressSigLRPosYFrmADD ParkProgressSigRFPosXFrmADD ParkProgressSigRFPosYFrmADD ParkProgressSigRRPosXFrmADD ParkProgressSigRRPosYFrmADD PASProgressSigGrpChks PASProgressSigGrpCntr;
SIG_GROUP_ 775 PASWorkingModeSigGrp 1 : PASSubFunAvaiFrmADD PASWorkingModeFrmADD PASWorkingModeSigGrpChks PASWorkingModeSigGrpCntr;
SIG_GROUP_ 239 ADDIMUSigGrp 1 : ADDIMUSigGrpChks ADDIMUSigGrpCntr XAccelStaFrmADD XAccelValFrmADD XAngRateStaFrmADD XAngRateValFrmADD YAccelStaFrmADD YAccelValFrmADD YAngRateStaFrmADD YAngRateValFrmADD ZAccelStaFrmADD ZAccelValFrmADD ZAngRateStaFrmADD ZAngRateValFrmADD;
SIG_GROUP_ 336 BcpSysStsSigGrp 1 : APBAplAvlBCP APBRelAvlBCP BCPBrkLiIllmnReq BCPBrkSysWarnText BCPMstCylP BCPMstCylPVld BCPSimulatorP BCPSimulatorPVld BCPSysSts BcpSysStsSigGrpChks BcpSysStsSigGrpCntr BrkFldWarn BrkFldWarnVld BrkPedlAppld BrkPedlAppldVld BrkPedlPerct BrkPedlPerctVld InpRodStk InpRodStkVld;
SIG_GROUP_ 336 BrkAssSigGrp 1 : ABAActv ABAAvl APBStsBkp BrkAssSigGrpChks BrkAssSigGrpCntr HBAActv HBAAvl;
SIG_GROUP_ 340 BcpBrkSysCtrlBkpSigGrp 1 : APBStsBkpFusion BcpBrkSysCtrlBkpSigGrpChks BcpBrkSysCtrlBkpSigGrpCntr BrkSysActCircNoP BrkSysBCPDiagActv BrkSysCmptIdx BrkSysHBCReq BrkSysPRnt BrkSysPRntVld;
SIG_GROUP_ 340 BCPSysCtrlSigGrp 1 : ActCirNoPressureQ BCPBrkSysActCircNoP BCPBrkSysFTarDrvr BCPBrkSysFTarDrvrVld BCPSysCtrlSigGrpChks BCPSysCtrlSigGrpCntr InpRodStkBkp InpRodStkBkpVld;
SIG_GROUP_ 340 RpbBkpSigGrp 1 : APBAplAvlBCPFusion APBRelAvlBCPFusion RPBActrStSec RpbBkpSigGrpChks RpbBkpSigGrpCntr RPBRPBCoornSec;
SIG_GROUP_ 487 BcpBrkSysBkpSigGrp 1 : BcpBrkSysBkpSigGrpChks BcpBrkSysBkpSigGrpCntr BrkSysBCPLdmBrkActActr BrkSysBCPLdmBrkActAxle BrkSysBCPLdmBrkActGenr BrkSysBCPLdmBrkActTyp BrkSysBCPLdmSysModReq BrkSysLdmFTarBrkBCP BrkSysLdmFTarBrkBCPVld BrkSysLdmFTarMaxPt BrkSysLdmFTarMinPt BrkSysLdmGlbStsAct BrkSysParkBrkReq;
SIG_GROUP_ 487 BcpBrkSysIndcnBkpSigGrp 1 : BcpBrkSysIndcnBkpSigGrpChks BcpBrkSysIndcnBkpSigGrpCntr BrkSysBrkPedlAppld BrkSysBrkPedlAppldVld BrkSysEnaActvCtrlByDrvr BrkSysFTarDrvr BrkSysFTarDrvrVld BrkSysPRednPotnl BrkSysPRednPotnlVld BrkSysWarnLampReq;
SIG_GROUP_ 487 BrkSysAPCBkpSigGrp 1 : BrkSysAPBBkp2MainSafeLimCom2 BrkSysAPBParkBrkReqBkp2MainCom2 BrkSysAPCBkp2MainStCom2 BrkSysAPCBkpSigGrpChks BrkSysAPCBkpSigGrpCntr;
SIG_GROUP_ 487 RPBHydPSpprt 1 : BCPDrvBrakeActType BCPRecuStatusAct FxTargetDriverMinFrict RecuSuppressEna RPBHydPSpprtChks RPBHydPSpprtCntr RPBHydPSpprtP RPBHydPSpprtReq;
SIG_GROUP_ 337 BcsBasicFcnSigGrp 1 : APBAplAvlBCS APBErrDetd APBRelAvlBCS APBSts AVHAvl AVHSts BcsBasicFcnSigGrpChks BcsBasicFcnSigGrpCntr CDPActv CDPAvl DrvOffTqThd DSTActv DSTSteerTqReq HHCActv HHCAvl SCMActv SCMAvl;
SIG_GROUP_ 337 BcsExtdFcnSigGrp 1 : ABPActv ABPAvl AEBActv AEBAvl AWBActv AWBAvl BcsExtdFcnSigGrpChks BcsExtdFcnSigGrpCntr EBAActv;
SIG_GROUP_ 337 BcsSysCtrSigGrp 1 : ABSActv ABSErrDetd APBTxtDip BCSBrkSysWarnText BcsSysCtrSigGrpChks BcsSysCtrSigGrpCntr BrkLiIllmnReq BrkSysWarnLamp CSTSts EBDActv EBDErrDetd EmgyBrkLiReq ESCErrDetd ESCIntvLamp ESCPataLamp ESCSwitchAvl EstimdSumOfVehHydBrkEachWhl HBBActive HBBSts HBCActv HDCAvl HDCCtrlSts HRBActv HRBAvl HydBrkFExist MstCylPCmp MstCylPVld TCSActv VDCActv VehStandStillIndcr VehStandStillIndcrVld;
SIG_GROUP_ 338 ApcFcnSigGrp 1 : APAActrAvl APCActvVehHld APCDrvrBrkOvrdFlg APCFailrSts ApcFcnSigGrpChks ApcFcnSigGrpCntr APCSts RPAAVPActrAvl;
SIG_GROUP_ 338 BcsTqCtrlSigGrp 1 : BCSLgtCtrlPtTarTq BCSLgtCtrlPtTarTqEna BcsTqCtrlSigGrpChks BcsTqCtrlSigGrpCntr BiasMaxFrntAxle BiasMaxReAxle CstRgnBlendSts CstRgnBlendTqReqFA CstRgnBlendTqReqRA DrgTqCtrlActvFA DrgTqCtrlActvRA PtTqRednActvFA PtTqRednActvRA TarRdcdPtTqFA TarRdcdPtTqRA TarRecuTqReq TarRecuTqReqSts;
SIG_GROUP_ 354 BrkSysMonBkpSigGrp 1 : BrkSysAxRoadSlope BrkSysAxRoadSlopeVld BrkSysBCSDiagActv BrkSysMonBkpSigGrpChks BrkSysMonBkpSigGrpCntr BrkSysMotPedlPosnDrvr BrkSysShiftVol BrkSysSkidDrv BrkSysSkidYawRate;
SIG_GROUP_ 354 RpbStsIndcnBkpSigGrp 1 : APBAplAvlBCSFusion APBRelAvlBCSFusion APBStsFusion PRBCoornPrim RPBActrStPrim RPBAx RPBAxSt RPBIntReqPrim RPBPrkgBtnPsd RPBPrkgBtnPsdVld RpbStsIndcnBkpSigGrpChks RpbStsIndcnBkpSigGrpCntr;
SIG_GROUP_ 354 WhlspdBkpFcnSigGrp 1 : VehSpdBkp VehSpdBkpVld WhlspdBkpFcnSigGrpChks WhlspdBkpFcnSigGrpCntr;
SIG_GROUP_ 179 AdcFcnSigGrp 1 : AdcFcnSigGrpChks AdcFcnSigGrpCntr BCSActrActvForADC BCSActrAvlStsForADC BCSActrAvlStsForADCL3 BCSActrRampOffStsForADC BCSActrVldForADC;
SIG_GROUP_ 179 WhlStsSigGrp 1 : VehSpd VehSpdVld WhlDirFrntLe WhlDirFrntLeVld WhlDirFrntRi WhlDirFrntRiVld WhlDirReLe WhlDirReLeVld WhlDirReRi WhlDirReRiVld WhlDstTiStampFrntLe WhlDstTiStampFrntRi WhlDstTiStampReLe WhlDstTiStampReRi WhlSpdEdgeFrntLe WhlSpdEdgeFrntLeVld WhlSpdEdgeFrntRi WhlSpdEdgeFrntRiVld WhlSpdEdgeReLe WhlSpdEdgeReLeVld WhlSpdEdgeReRi WhlSpdEdgeReRiVld WhlSpdFrntLe WhlSpdFrntLeVld WhlSpdFrntRi WhlSpdFrntRiVld WhlSpdReLe WhlSpdReLeVld WhlSpdReRi WhlSpdReRiVld WhlStsSigGrpChks WhlStsSigGrpCntr;
